VERSION "8.0.0-beta2"

NS_ :

BS_:

BU_:

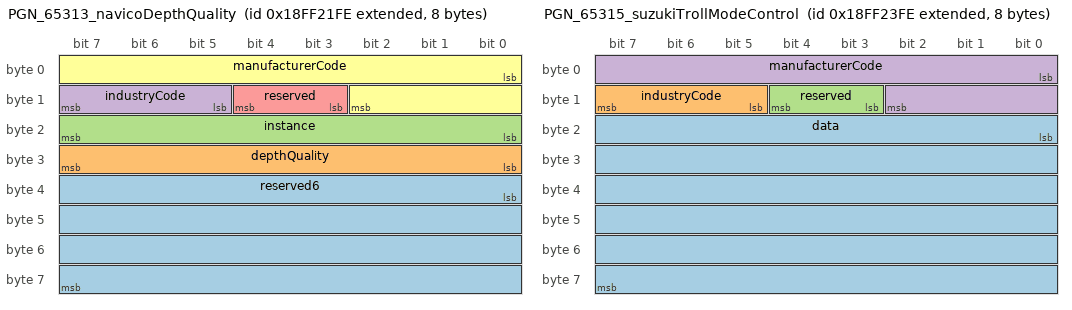
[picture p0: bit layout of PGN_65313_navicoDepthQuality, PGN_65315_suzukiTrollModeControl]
BO_ 2566857214 PGN_65313_navicoDepthQuality: 8 Vector__XXX
 SG_ reserved6 : 32|32@1+ (1,0) [0|0] "" Vector__XXX
 SG_ depthQuality : 24|8@1- (0.01,0) [0|0] "" Vector__XXX
 SG_ instance : 16|8@1+ (1,0) [0|0] "" Vector__XXX
 SG_ industryCode : 13|3@1+ (1,0) [0|0] "" Vector__XXX
 SG_ reserved : 11|2@1+ (1,0) [0|0] "" Vector__XXX
 SG_ manufacturerCode : 0|11@1+ (1,0) [0|0] "" Vector__XXX

BO_ 2566857470 PGN_65314_multiplexed: 8 Vector__XXX
 SG_ m39110_reserved8 m39110 : 48|16@1+ (1,0) [0|0] "" Vector__XXX
 SG_ m39110_reserved7 m39110 : 42|6@1+ (1,0) [0|0] "" Vector__XXX
 SG_ m39110_neutral m39110 : 41|1@1+ (1,0) [0|0] "" Vector__XXX
 SG_ m39110_reserved5 m39110 : 40|1@1+ (1,0) [0|0] "" Vector__XXX
 SG_ m39110_reserved4 m39110 : 16|24@1+ (1,0) [0|0] "" Vector__XXX
 SG_ m39207_data m39207 : 16|48@1+ (1,0) [0|0] "" Vector__XXX
 SG_ manufacturerIndustry M : 0|16@1+ (1,0) [0|0] "" Vector__XXX

BO_ 2566857726 PGN_65315_suzukiTrollModeControl: 8 Vector__XXX
 SG_ data : 16|48@1+ (1,0) [0|0] "" Vector__XXX
 SG_ industryCode : 13|3@1+ (1,0) [0|0] "" Vector__XXX
 SG_ reserved : 11|2@1+ (1,0) [0|0] "" Vector__XXX
 SG_ manufacturerCode : 0|11@1+ (1,0) [0|0] "" Vector__XXX

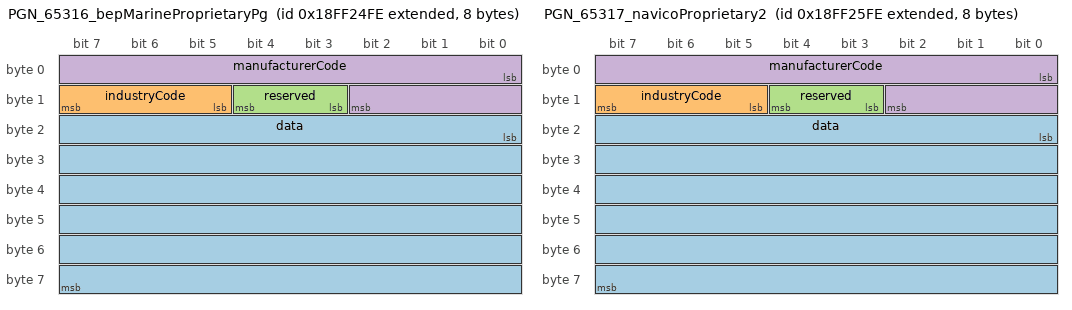
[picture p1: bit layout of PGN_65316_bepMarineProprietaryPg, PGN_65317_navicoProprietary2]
BO_ 2566857982 PGN_65316_bepMarineProprietaryPg: 8 Vector__XXX
 SG_ data : 16|48@1+ (1,0) [0|0] "" Vector__XXX
 SG_ industryCode : 13|3@1+ (1,0) [0|0] "" Vector__XXX
 SG_ reserved : 11|2@1+ (1,0) [0|0] "" Vector__XXX
 SG_ manufacturerCode : 0|11@1+ (1,0) [0|0] "" Vector__XXX

BO_ 2566858238 PGN_65317_navicoProprietary2: 8 Vector__XXX
 SG_ data : 16|48@1+ (1,0) [0|0] "" Vector__XXX
 SG_ industryCode : 13|3@1+ (1,0) [0|0] "" Vector__XXX
 SG_ reserved : 11|2@1+ (1,0) [0|0] "" Vector__XXX
 SG_ manufacturerCode : 0|11@1+ (1,0) [0|0] "" Vector__XXX

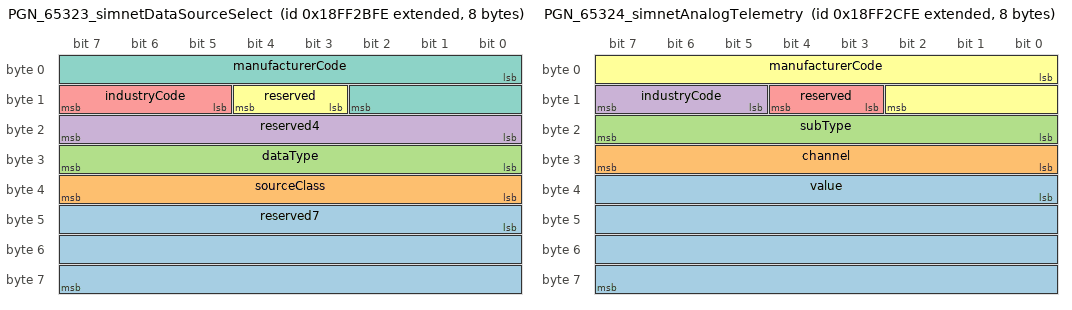
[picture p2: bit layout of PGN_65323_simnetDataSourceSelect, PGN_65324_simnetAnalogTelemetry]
BO_ 2566859774 PGN_65323_simnetDataSourceSelect: 8 Vector__XXX
 SG_ reserved7 : 40|24@1+ (1,0) [0|0] "" Vector__XXX
 SG_ sourceClass : 32|8@1+ (1,0) [0|0] "" Vector__XXX
 SG_ dataType : 24|8@1+ (1,0) [0|0] "" Vector__XXX
 SG_ reserved4 : 16|8@1+ (1,0) [0|0] "" Vector__XXX
 SG_ industryCode : 13|3@1+ (1,0) [0|0] "" Vector__XXX
 SG_ reserved : 11|2@1+ (1,0) [0|0] "" Vector__XXX
 SG_ manufacturerCode : 0|11@1+ (1,0) [0|0] "" Vector__XXX

BO_ 2566860030 PGN_65324_simnetAnalogTelemetry: 8 Vector__XXX
 SG_ value : 32|32@1+ (1,0) [0|0] "" Vector__XXX
 SG_ channel : 24|8@1+ (1,0) [0|0] "" Vector__XXX
 SG_ subType : 16|8@1+ (1,0) [0|0] "" Vector__XXX
 SG_ industryCode : 13|3@1+ (1,0) [0|0] "" Vector__XXX
 SG_ reserved : 11|2@1+ (1,0) [0|0] "" Vector__XXX
 SG_ manufacturerCode : 0|11@1+ (1,0) [0|0] "" Vector__XXX

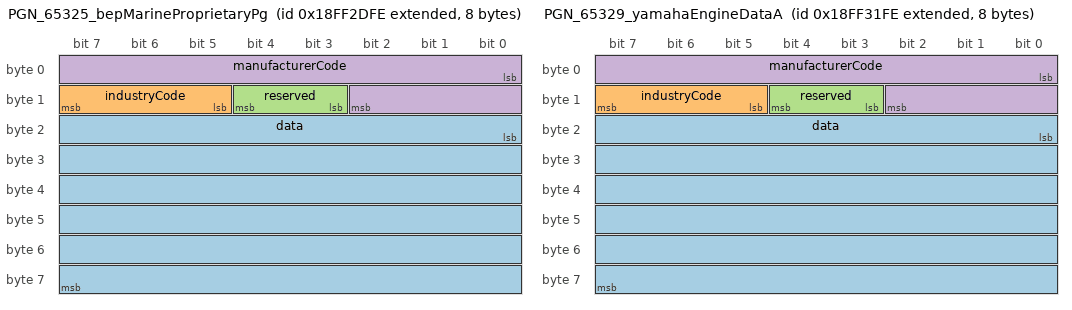
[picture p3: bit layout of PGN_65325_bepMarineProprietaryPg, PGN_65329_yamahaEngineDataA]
BO_ 2566860286 PGN_65325_bepMarineProprietaryPg: 8 Vector__XXX
 SG_ data : 16|48@1+ (1,0) [0|0] "" Vector__XXX
 SG_ industryCode : 13|3@1+ (1,0) [0|0] "" Vector__XXX
 SG_ reserved : 11|2@1+ (1,0) [0|0] "" Vector__XXX
 SG_ manufacturerCode : 0|11@1+ (1,0) [0|0] "" Vector__XXX

BO_ 2566861310 PGN_65329_yamahaEngineDataA: 8 Vector__XXX
 SG_ data : 16|48@1+ (1,0) [0|0] "" Vector__XXX
 SG_ industryCode : 13|3@1+ (1,0) [0|0] "" Vector__XXX
 SG_ reserved : 11|2@1+ (1,0) [0|0] "" Vector__XXX
 SG_ manufacturerCode : 0|11@1+ (1,0) [0|0] "" Vector__XXX

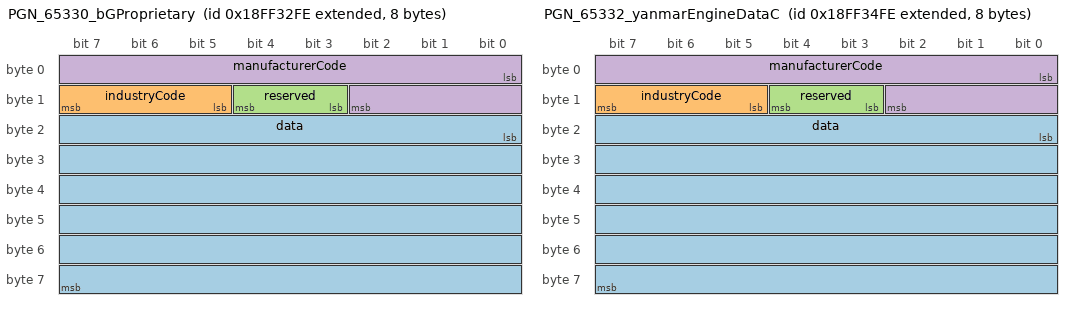
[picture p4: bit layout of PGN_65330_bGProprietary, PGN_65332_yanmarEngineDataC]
BO_ 2566861566 PGN_65330_bGProprietary: 8 Vector__XXX
 SG_ data : 16|48@1+ (1,0) [0|0] "" Vector__XXX
 SG_ industryCode : 13|3@1+ (1,0) [0|0] "" Vector__XXX
 SG_ reserved : 11|2@1+ (1,0) [0|0] "" Vector__XXX
 SG_ manufacturerCode : 0|11@1+ (1,0) [0|0] "" Vector__XXX

BO_ 2566862078 PGN_65332_yanmarEngineDataC: 8 Vector__XXX
 SG_ data : 16|48@1+ (1,0) [0|0] "" Vector__XXX
 SG_ industryCode : 13|3@1+ (1,0) [0|0] "" Vector__XXX
 SG_ reserved : 11|2@1+ (1,0) [0|0] "" Vector__XXX
 SG_ manufacturerCode : 0|11@1+ (1,0) [0|0] "" Vector__XXX

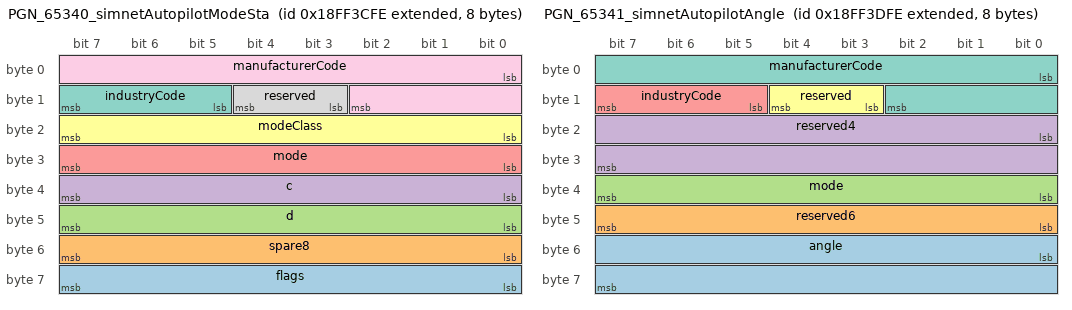
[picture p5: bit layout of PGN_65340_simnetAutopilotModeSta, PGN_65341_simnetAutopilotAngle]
BO_ 2566864126 PGN_65340_simnetAutopilotModeSta: 8 Vector__XXX
 SG_ flags : 56|8@1+ (1,0) [0|0] "" Vector__XXX
 SG_ spare8 : 48|8@1+ (1,0) [0|0] "" Vector__XXX
 SG_ d : 40|8@1+ (1,0) [0|0] "" Vector__XXX
 SG_ c : 32|8@1+ (1,0) [0|0] "" Vector__XXX
 SG_ mode : 24|8@1+ (1,0) [0|0] "" Vector__XXX
 SG_ modeClass : 16|8@1+ (1,0) [0|0] "" Vector__XXX
 SG_ industryCode : 13|3@1+ (1,0) [0|0] "" Vector__XXX
 SG_ reserved : 11|2@1+ (1,0) [0|0] "" Vector__XXX
 SG_ manufacturerCode : 0|11@1+ (1,0) [0|0] "" Vector__XXX

BO_ 2566864382 PGN_65341_simnetAutopilotAngle: 8 Vector__XXX
 SG_ angle : 48|16@1+ (0.0001,0) [0|0] "rad" Vector__XXX
 SG_ reserved6 : 40|8@1+ (1,0) [0|0] "" Vector__XXX
 SG_ mode : 32|8@1+ (1,0) [0|0] "" Vector__XXX
 SG_ reserved4 : 16|16@1+ (1,0) [0|0] "" Vector__XXX
 SG_ industryCode : 13|3@1+ (1,0) [0|0] "" Vector__XXX
 SG_ reserved : 11|2@1+ (1,0) [0|0] "" Vector__XXX
 SG_ manufacturerCode : 0|11@1+ (1,0) [0|0] "" Vector__XXX

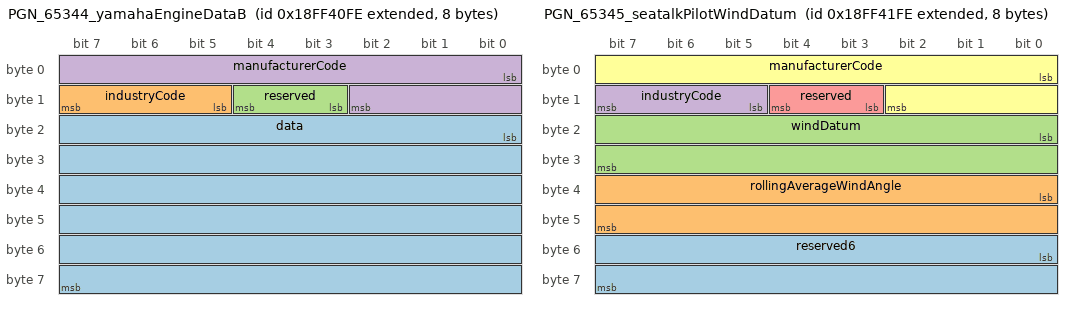
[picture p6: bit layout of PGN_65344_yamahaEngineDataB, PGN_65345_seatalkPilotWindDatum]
BO_ 2566865150 PGN_65344_yamahaEngineDataB: 8 Vector__XXX
 SG_ data : 16|48@1+ (1,0) [0|0] "" Vector__XXX
 SG_ industryCode : 13|3@1+ (1,0) [0|0] "" Vector__XXX
 SG_ reserved : 11|2@1+ (1,0) [0|0] "" Vector__XXX
 SG_ manufacturerCode : 0|11@1+ (1,0) [0|0] "" Vector__XXX

BO_ 2566865406 PGN_65345_seatalkPilotWindDatum: 8 Vector__XXX
 SG_ reserved6 : 48|16@1+ (1,0) [0|0] "" Vector__XXX
 SG_ rollingAverageWindAngle : 32|16@1+ (0.0001,0) [0|0] "rad" Vector__XXX
 SG_ windDatum : 16|16@1+ (0.0001,0) [0|0] "rad" Vector__XXX
 SG_ industryCode : 13|3@1+ (1,0) [0|0] "" Vector__XXX
 SG_ reserved : 11|2@1+ (1,0) [0|0] "" Vector__XXX
 SG_ manufacturerCode : 0|11@1+ (1,0) [0|0] "" Vector__XXX

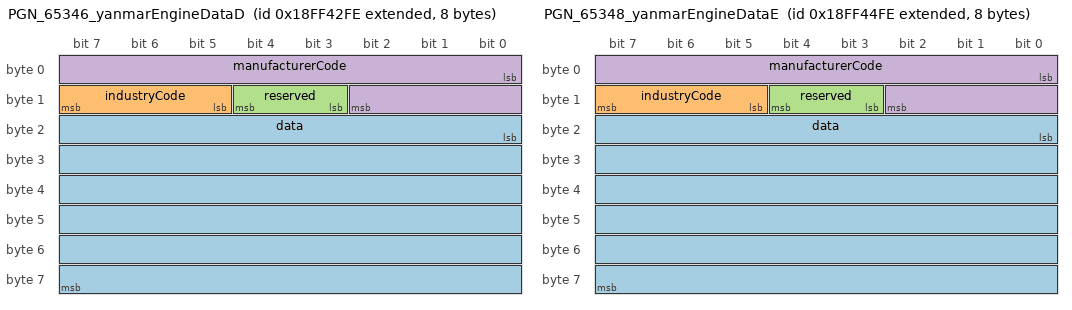
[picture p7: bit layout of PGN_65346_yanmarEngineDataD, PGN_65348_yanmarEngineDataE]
BO_ 2566865662 PGN_65346_yanmarEngineDataD: 8 Vector__XXX
 SG_ data : 16|48@1+ (1,0) [0|0] "" Vector__XXX
 SG_ industryCode : 13|3@1+ (1,0) [0|0] "" Vector__XXX
 SG_ reserved : 11|2@1+ (1,0) [0|0] "" Vector__XXX
 SG_ manufacturerCode : 0|11@1+ (1,0) [0|0] "" Vector__XXX

BO_ 2566866174 PGN_65348_yanmarEngineDataE: 8 Vector__XXX
 SG_ data : 16|48@1+ (1,0) [0|0] "" Vector__XXX
 SG_ industryCode : 13|3@1+ (1,0) [0|0] "" Vector__XXX
 SG_ reserved : 11|2@1+ (1,0) [0|0] "" Vector__XXX
 SG_ manufacturerCode : 0|11@1+ (1,0) [0|0] "" Vector__XXX

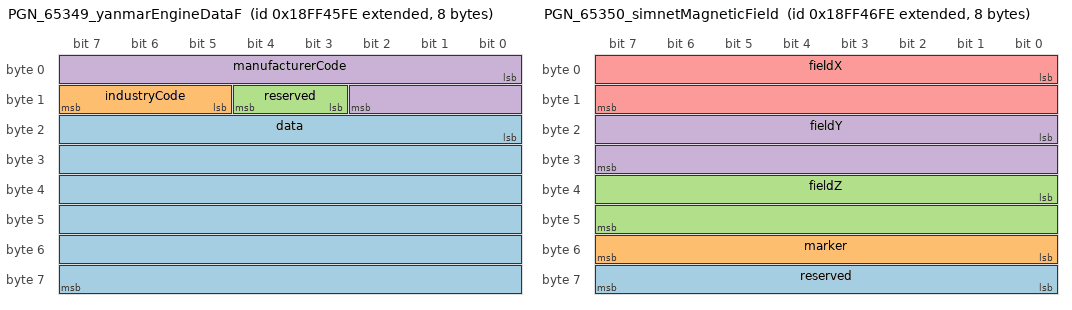
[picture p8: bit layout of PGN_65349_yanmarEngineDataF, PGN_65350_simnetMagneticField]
BO_ 2566866430 PGN_65349_yanmarEngineDataF: 8 Vector__XXX
 SG_ data : 16|48@1+ (1,0) [0|0] "" Vector__XXX
 SG_ industryCode : 13|3@1+ (1,0) [0|0] "" Vector__XXX
 SG_ reserved : 11|2@1+ (1,0) [0|0] "" Vector__XXX
 SG_ manufacturerCode : 0|11@1+ (1,0) [0|0] "" Vector__XXX

BO_ 2566866686 PGN_65350_simnetMagneticField: 8 Vector__XXX
 SG_ reserved : 56|8@1+ (1,0) [0|0] "" Vector__XXX
 SG_ marker : 48|8@1+ (1,0) [0|0] "" Vector__XXX
 SG_ fieldZ : 32|16@1- (0.0001,0) [0|0] "" Vector__XXX
 SG_ fieldY : 16|16@1- (0.0001,0) [0|0] "" Vector__XXX
 SG_ fieldX : 0|16@1- (0.0001,0) [0|0] "" Vector__XXX

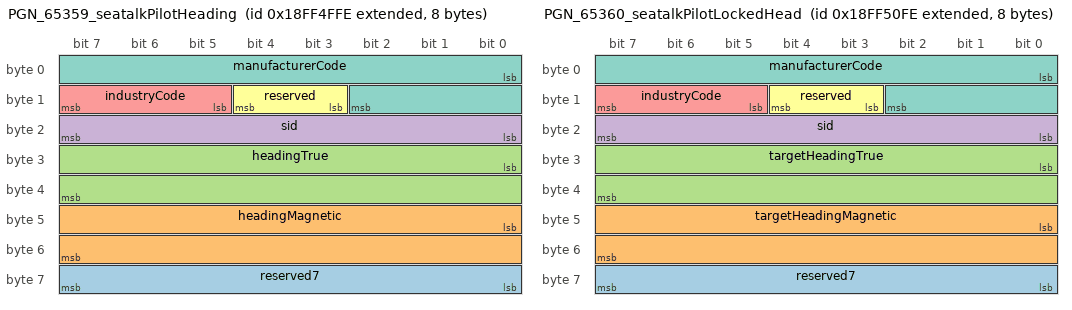
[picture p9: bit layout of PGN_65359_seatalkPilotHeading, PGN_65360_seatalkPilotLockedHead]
BO_ 2566868990 PGN_65359_seatalkPilotHeading: 8 Vector__XXX
 SG_ reserved7 : 56|8@1+ (1,0) [0|0] "" Vector__XXX
 SG_ headingMagnetic : 40|16@1+ (0.0001,0) [0|0] "rad" Vector__XXX
 SG_ headingTrue : 24|16@1+ (0.0001,0) [0|0] "rad" Vector__XXX
 SG_ sid : 16|8@1+ (1,0) [0|0] "" Vector__XXX
 SG_ industryCode : 13|3@1+ (1,0) [0|0] "" Vector__XXX
 SG_ reserved : 11|2@1+ (1,0) [0|0] "" Vector__XXX
 SG_ manufacturerCode : 0|11@1+ (1,0) [0|0] "" Vector__XXX

BO_ 2566869246 PGN_65360_seatalkPilotLockedHead: 8 Vector__XXX
 SG_ reserved7 : 56|8@1+ (1,0) [0|0] "" Vector__XXX
 SG_ targetHeadingMagnetic : 40|16@1+ (0.0001,0) [0|0] "rad" Vector__XXX
 SG_ targetHeadingTrue : 24|16@1+ (0.0001,0) [0|0] "rad" Vector__XXX
 SG_ sid : 16|8@1+ (1,0) [0|0] "" Vector__XXX
 SG_ industryCode : 13|3@1+ (1,0) [0|0] "" Vector__XXX
 SG_ reserved : 11|2@1+ (1,0) [0|0] "" Vector__XXX
 SG_ manufacturerCode : 0|11@1+ (1,0) [0|0] "" Vector__XXX

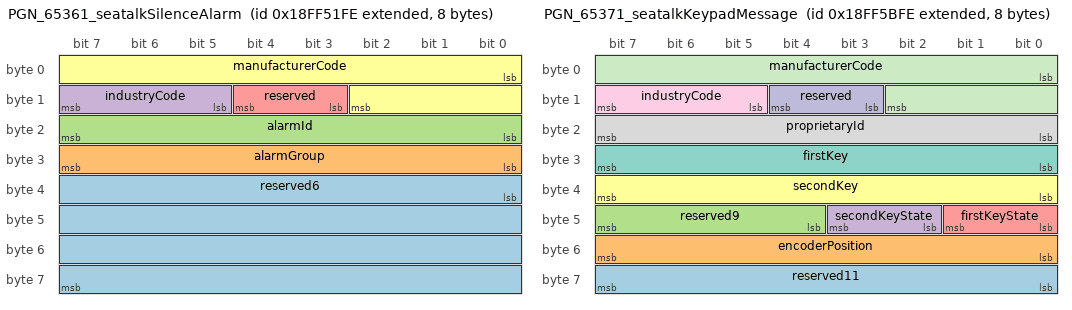
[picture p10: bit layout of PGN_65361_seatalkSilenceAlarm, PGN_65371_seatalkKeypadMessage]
BO_ 2566869502 PGN_65361_seatalkSilenceAlarm: 8 Vector__XXX
 SG_ reserved6 : 32|32@1+ (1,0) [0|0] "" Vector__XXX
 SG_ alarmGroup : 24|8@1+ (1,0) [0|0] "" Vector__XXX
 SG_ alarmId : 16|8@1+ (1,0) [0|0] "" Vector__XXX
 SG_ industryCode : 13|3@1+ (1,0) [0|0] "" Vector__XXX
 SG_ reserved : 11|2@1+ (1,0) [0|0] "" Vector__XXX
 SG_ manufacturerCode : 0|11@1+ (1,0) [0|0] "" Vector__XXX

BO_ 2566872062 PGN_65371_seatalkKeypadMessage: 8 Vector__XXX
 SG_ reserved11 : 56|8@1+ (1,0) [0|0] "" Vector__XXX
 SG_ encoderPosition : 48|8@1+ (1,0) [0|0] "" Vector__XXX
 SG_ reserved9 : 44|4@1+ (1,0) [0|0] "" Vector__XXX
 SG_ secondKeyState : 42|2@1+ (1,0) [0|0] "" Vector__XXX
 SG_ firstKeyState : 40|2@1+ (1,0) [0|0] "" Vector__XXX
 SG_ secondKey : 32|8@1+ (1,0) [0|0] "" Vector__XXX
 SG_ firstKey : 24|8@1+ (1,0) [0|0] "" Vector__XXX
 SG_ proprietaryId : 16|8@1+ (1,0) [0|0] "" Vector__XXX
 SG_ industryCode : 13|3@1+ (1,0) [0|0] "" Vector__XXX
 SG_ reserved : 11|2@1+ (1,0) [0|0] "" Vector__XXX
 SG_ manufacturerCode : 0|11@1+ (1,0) [0|0] "" Vector__XXX

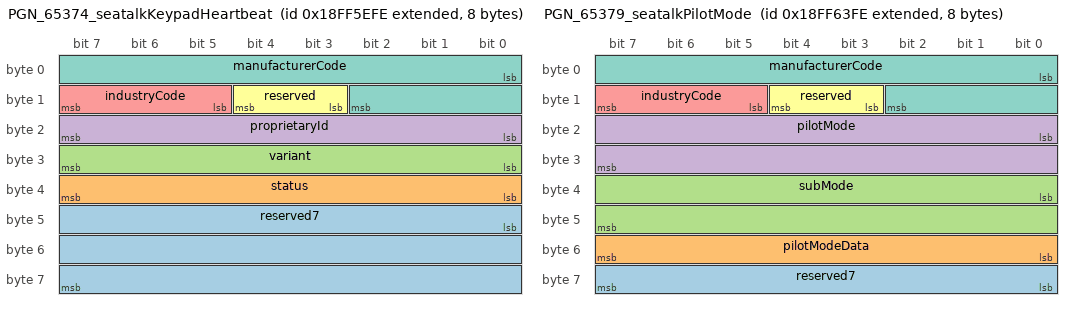
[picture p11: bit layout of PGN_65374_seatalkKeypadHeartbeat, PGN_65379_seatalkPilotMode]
BO_ 2566872830 PGN_65374_seatalkKeypadHeartbeat: 8 Vector__XXX
 SG_ reserved7 : 40|24@1+ (1,0) [0|0] "" Vector__XXX
 SG_ status : 32|8@1+ (1,0) [0|0] "" Vector__XXX
 SG_ variant : 24|8@1+ (1,0) [0|0] "" Vector__XXX
 SG_ proprietaryId : 16|8@1+ (1,0) [0|0] "" Vector__XXX
 SG_ industryCode : 13|3@1+ (1,0) [0|0] "" Vector__XXX
 SG_ reserved : 11|2@1+ (1,0) [0|0] "" Vector__XXX
 SG_ manufacturerCode : 0|11@1+ (1,0) [0|0] "" Vector__XXX

BO_ 2566874110 PGN_65379_seatalkPilotMode: 8 Vector__XXX
 SG_ reserved7 : 56|8@1+ (1,0) [0|0] "" Vector__XXX
 SG_ pilotModeData : 48|8@1+ (1,0) [0|0] "" Vector__XXX
 SG_ subMode : 32|16@1+ (1,0) [0|0] "" Vector__XXX
 SG_ pilotMode : 16|16@1+ (1,0) [0|0] "" Vector__XXX
 SG_ industryCode : 13|3@1+ (1,0) [0|0] "" Vector__XXX
 SG_ reserved : 11|2@1+ (1,0) [0|0] "" Vector__XXX
 SG_ manufacturerCode : 0|11@1+ (1,0) [0|0] "" Vector__XXX

CM_ BO_ 2566857214 "Navico: Depth Quality";
CM_ SG_ 2566857214 depthQuality "Depth signal quality ratio (0 = no bottom lock .. ~1.0 = good)";
CM_ SG_ 2566857214 industryCode "Marine Industry";
CM_ SG_ 2566857214 manufacturerCode "Navico";
CM_ BO_ 2566857470 "Multiplexed message";
CM_ BO_ 2566857726 "Suzuki: Troll Mode Control";
CM_ SG_ 2566857726 industryCode "Marine Industry";
CM_ SG_ 2566857726 manufacturerCode "Suzuki Motor Corporation";
CM_ BO_ 2566857982 "BEP Marine: Proprietary PGN 65316";
CM_ SG_ 2566857982 industryCode "Marine Industry";
CM_ SG_ 2566857982 manufacturerCode "BEP Marine 2";
CM_ BO_ 2566858238 "Navico: Proprietary 2";
CM_ SG_ 2566858238 industryCode "Marine Industry";
CM_ SG_ 2566858238 manufacturerCode "Navico";
CM_ BO_ 2566859774 "Simnet: Data Source Selection Request";
CM_ SG_ 2566859774 sourceClass "Class of source for this Data Type, constant per Data Type: observed as 1 for direct sensor/navigation sources and 100 for autopilot-provided sources";
CM_ SG_ 2566859774 industryCode "Marine Industry";
CM_ SG_ 2566859774 manufacturerCode "Simrad";
CM_ BO_ 2566860030 "Simnet: Analog Telemetry";
CM_ SG_ 2566860030 value "Raw channel reading; 0x7FFF or 0xFFFF means not available";
CM_ SG_ 2566860030 channel "Selects which analog quantity is reported (e.g. drive/heatsink temperature, drive supply voltage, drive current, rudder-feedback angle)";
CM_ SG_ 2566860030 subType "0x40 = telemetry";
CM_ SG_ 2566860030 industryCode "Marine Industry";
CM_ SG_ 2566860030 manufacturerCode "Simrad";
CM_ BO_ 2566860286 "BEP Marine: Proprietary PGN 65325";
CM_ SG_ 2566860286 industryCode "Marine Industry";
CM_ SG_ 2566860286 manufacturerCode "BEP Marine 2";
CM_ BO_ 2566861310 "Yamaha: Engine Data A";
CM_ SG_ 2566861310 industryCode "Marine Industry";
CM_ SG_ 2566861310 manufacturerCode "Mystic Valley Communications";
CM_ BO_ 2566861566 "B&G: Proprietary";
CM_ SG_ 2566861566 industryCode "Marine Industry";
CM_ SG_ 2566861566 manufacturerCode "B & G";
CM_ BO_ 2566862078 "Yanmar: Engine Data C";
CM_ SG_ 2566862078 industryCode "Marine Industry";
CM_ SG_ 2566862078 manufacturerCode "Yanmar Marine";
CM_ BO_ 2566864126 "Simnet: Autopilot Mode State";
CM_ SG_ 2566864126 industryCode "Marine Industry";
CM_ SG_ 2566864126 manufacturerCode "Simrad";
CM_ BO_ 2566864382 "Simnet: Autopilot Angle";
CM_ SG_ 2566864382 industryCode "Marine Industry";
CM_ SG_ 2566864382 manufacturerCode "Simrad";
CM_ BO_ 2566865150 "Yamaha: Engine Data B";
CM_ SG_ 2566865150 industryCode "Marine Industry";
CM_ SG_ 2566865150 manufacturerCode "Mystic Valley Communications";
CM_ BO_ 2566865406 "Seatalk: Pilot Wind Datum";
CM_ SG_ 2566865406 industryCode "Marine Industry";
CM_ SG_ 2566865406 manufacturerCode "Raymarine";
CM_ BO_ 2566865662 "Yanmar: Engine Data D";
CM_ SG_ 2566865662 industryCode "Marine Industry";
CM_ SG_ 2566865662 manufacturerCode "Yanmar Marine";
CM_ BO_ 2566866174 "Yanmar: Engine Data E";
CM_ SG_ 2566866174 industryCode "Marine Industry";
CM_ SG_ 2566866174 manufacturerCode "Yanmar Marine";
CM_ BO_ 2566866430 "Yanmar: Engine Data F";
CM_ SG_ 2566866430 industryCode "Marine Industry";
CM_ SG_ 2566866430 manufacturerCode "Yanmar Marine";
CM_ BO_ 2566866686 "Simnet: Magnetic Field";
CM_ BO_ 2566868990 "Seatalk: Pilot Heading";
CM_ SG_ 2566868990 industryCode "Marine Industry";
CM_ SG_ 2566868990 manufacturerCode "Raymarine";
CM_ BO_ 2566869246 "Seatalk: Pilot Locked Heading";
CM_ SG_ 2566869246 industryCode "Marine Industry";
CM_ SG_ 2566869246 manufacturerCode "Raymarine";
CM_ BO_ 2566869502 "Seatalk: Silence Alarm";
CM_ SG_ 2566869502 industryCode "Marine Industry";
CM_ SG_ 2566869502 manufacturerCode "Raymarine";
CM_ BO_ 2566872062 "Seatalk: Keypad Message";
CM_ SG_ 2566872062 industryCode "Marine Industry";
CM_ SG_ 2566872062 manufacturerCode "Raymarine";
CM_ BO_ 2566872830 "SeaTalk: Keypad Heartbeat";
CM_ SG_ 2566872830 industryCode "Marine Industry";
CM_ SG_ 2566872830 manufacturerCode "Raymarine";
CM_ BO_ 2566874110 "Seatalk: Pilot Mode";
CM_ SG_ 2566874110 industryCode "Marine Industry";
CM_ SG_ 2566874110 manufacturerCode "Raymarine";
BA_DEF_ BO_  "SystemMessageLongSymbol" STRING ;
BA_DEF_ SG_  "SystemSignalLongSymbol" STRING ;
BA_DEF_DEF_  "SystemMessageLongSymbol" "";
BA_DEF_DEF_  "SystemSignalLongSymbol" "";
BA_ "SystemMessageLongSymbol" BO_ 2566857982 "PGN_65316_bepMarineProprietaryPgn65316";
BA_ "SystemMessageLongSymbol" BO_ 2566859774 "PGN_65323_simnetDataSourceSelectionRequest";
BA_ "SystemMessageLongSymbol" BO_ 2566860286 "PGN_65325_bepMarineProprietaryPgn65325";
BA_ "SystemMessageLongSymbol" BO_ 2566864126 "PGN_65340_simnetAutopilotModeState";
BA_ "SystemMessageLongSymbol" BO_ 2566869246 "PGN_65360_seatalkPilotLockedHeading";
VAL_ 2566857214 industryCode 0 "Global" 1 "Highway" 2 "Agriculture" 3 "Construction" 4 "Marine Industry" 5 "Industrial" ;
VAL_ 2566857214 manufacturerCode 69 "ARKS Enterprises, Inc." 78 "FW Murphy/Enovation Controls" 80 "Twin Disc" 85 "Kohler Power Systems" 88 "Hemisphere GPS Inc" 116 "BEP Marine" 135 "Airmar" 137 "Maretron" 140 "Lowrance" 144 "Mercury Marine" 147 "Nautibus Electronic GmbH" 148 "Blue Water Data" 154 "Westerbeke" 157 "ISSPRO Inc" 161 "Offshore Systems (UK) Ltd." 163 "Evinrude/BRP" 165 "CPAC Systems AB" 168 "Xantrex Technology Inc." 169 "Marlin Technologies, Inc." 172 "Yanmar Marine" 174 "Volvo Penta" 175 "Honda Marine" 176 "Carling Technologies Inc. (Moritz Aerospace)" 185 "Beede Instruments" 192 "Floscan Instrument Co. Inc." 193 "Nobletec" 198 "Mystic Valley Communications" 199 "Actia" 200 "Honda Marine 2" 201 "Disenos Y Technologia" 211 "Digital Switching Systems" 215 "Xintex/Atena" 224 "EMMI NETWORK S.L." 225 "Honda Marine 3" 228 "ZF" 229 "Garmin" 233 "Yacht Monitoring Solutions" 235 "Sailormade Marine Telemetry/Tetra Technology LTD" 243 "Eride" 250 "Honda Marine 4" 257 "Honda Motor Company LTD" 272 "Groco" 273 "Actisense" 274 "Amphenol LTW Technology" 275 "Navico" 283 "Hamilton Jet" 285 "Sea Recovery" 286 "Coelmo SRL Italy" 295 "BEP Marine 2" 304 "Empir Bus" 305 "NovAtel" 306 "Sleipner Motor AS" 307 "MBW Technologies" 311 "Fischer Panda" 315 "ICOM" 328 "Qwerty" 329 "Dief" 341 "Boening Automationstechnologie GmbH & Co. KG" 345 "Korean Maritime University" 351 "Thrane and Thrane" 355 "Mastervolt" 356 "Fischer Panda Generators" 358 "Victron Energy" 370 "Rolls Royce Marine" 373 "Electronic Design" 374 "Northern Lights" 378 "Glendinning" 381 "B & G" 384 "Rose Point Navigation Systems" 385 "Johnson Outdoors Marine Electronics Inc Geonav" 394 "Capi 2" 396 "Beyond Measure" 400 "Livorsi Marine" 404 "ComNav" 409 "Chetco" 419 "Fusion Electronics" 421 "Standard Horizon" 422 "True Heading AB" 426 "Egersund Marine Electronics AS" 427 "em-trak Marine Electronics" 431 "Tohatsu Co, JP" 437 "Digital Yacht" 438 "Comar Systems Limited" 440 "Cummins" 443 "VDO (aka Continental-Corporation)" 451 "Parker Hannifin aka Village Marine Tech" 459 "Alltek Marine Electronics Corp" 460 "SAN GIORGIO S.E.I.N" 466 "Veethree Electronics & Marine" 467 "Humminbird Marine Electronics" 470 "SI-TEX Marine Electronics" 471 "Sea Cross Marine AB" 475 "GME aka Standard Communications Pty LTD" 476 "Humminbird Marine Electronics 2" 478 "Ocean Sat BV" 481 "Chetco Digitial Instruments" 493 "Watcheye" 499 "Lcj Capteurs" 502 "Attwood Marine" 503 "Naviop S.R.L." 504 "Vesper Marine Ltd" 510 "Marinesoft Co. LTD" 513 "Simarine" 517 "NoLand Engineering" 518 "Transas USA" 529 "National Instruments Korea" 530 "National Marine Electronics Association" 532 "Onwa Marine" 540 "Webasto" 571 "Marinecraft (South Korea)" 573 "McMurdo Group aka Orolia LTD" 578 "Advansea" 579 "KVH" 580 "San Jose Technology" 583 "Yacht Control" 586 "Suzuki Motor Corporation" 591 "US Coast Guard" 595 "Ship Module aka Customware" 600 "Aquatic AV" 605 "Aventics GmbH" 606 "Intellian" 612 "SamwonIT" 614 "Arlt Tecnologies" 637 "Bavaria Yacts" 641 "Diverse Yacht Services" 644 "Wema U.S.A dba KUS" 645 "Garmin 2" 658 "Shenzhen Jiuzhou Himunication" 688 "Rockford Corp" 699 "Harman International" 704 "JL Audio" 708 "Lars Thrane" 715 "Autonnic" 717 "Yacht Devices" 734 "REAP Systems" 735 "Au Electronics Group" 739 "LxNav" 741 "Littelfuse, Inc (formerly Carling Technologies)" 743 "DaeMyung" 744 "Woosung" 748 "ISOTTA IFRA srl" 772 "Blink Marine" 773 "Clarion US" 776 "HMI Systems" 777 "Ocean Signal" 778 "Seekeeper" 781 "Poly Planar" 785 "Fischer Panda DE" 795 "Broyda Industries" 796 "Canadian Automotive" 797 "Tides Marine" 798 "Lumishore" 799 "Still Water Designs and Audio" 802 "BJ Technologies (Beneteau)" 803 "Gill Sensors" 811 "Blue Water Desalination" 815 "FLIR" 824 "Undheim Systems" 826 "Lewmar Inc" 838 "TeamSurv" 844 "Fell Marine" 847 "Oceanvolt" 862 "Prospec" 868 "Data Panel Corp" 890 "L3 Technologies" 894 "Rhodan Marine Systems" 896 "Nexfour Solutions" 905 "ASA Electronics" 909 "Marines Co (South Korea)" 911 "Nautic-on" 917 "Sentinel" 929 "JL Marine ystems" 930 "Ecotronix" 944 "Zontisa Marine" 951 "EXOR International" 962 "Timbolier Industries" 963 "TJC Micro" 968 "Cox Powertrain" 969 "Blue Seas" 981 "Kobelt Manufacturing Co. Ltd" 992 "Blue Ocean IOT" 997 "Xenta Systems" 999 "Signal K" 1004 "Ultraflex SpA" 1008 "Lintest SmartBoat" 1011 "Soundmax" 1020 "Team Italia Marine (Onyx Marine Automation s.r.l)" 1021 "Entratech" 1022 "ITC Inc." 1029 "The Marine Guardian LLC" 1047 "Sonic Corporation" 1051 "ProNav" 1053 "Vetus Maxwell INC." 1056 "Lithium Pros" 1059 "Boatrax" 1062 "Marol Co ltd" 1065 "CALYPSO Instruments" 1066 "Spot Zero Water" 1069 "Lithionics Battery LLC" 1070 "Quick-teck Electronics Ltd" 1075 "Uniden America" 1083 "Nauticoncept" 1084 "Shadow-Caster LED lighting LLC" 1085 "Wet Sounds, LLC" 1088 "E-T-A Circuit Breakers" 1092 "Scheiber" 1100 "Smart Yachts International Limited" 1109 "Dockmate" 1114 "Bobs Machine" 1118 "L3Harris ASV" 1119 "Balmar LLC" 1120 "Elettromedia spa" 1127 "Electromaax" 1140 "Across Oceans Systems Ltd." 1145 "Kiwi Yachting" 1150 "BSB Artificial Intelligence GmbH" 1151 "Orca Technologoes AS" 1154 "TBS Electronics BV" 1158 "Technoton Electroics" 1160 "MG Energy Systems B.V." 1169 "Sea Macine Robotics Inc." 1171 "Vista Manufacturing" 1183 "Zipwake" 1186 "Sailmon BV" 1192 "Airmoniq Pro Kft" 1194 "Sierra Marine" 1200 "Xinuo Information Technology (Xiamen)" 1218 "Septentrio" 1233 "NKE Marine Elecronics" 1238 "SuperTrack Aps" 1239 "Honda Electronics Co., LTD" 1245 "Raritan Engineering Company, Inc" 1249 "Integrated Power Solutions AG" 1260 "Interactive Technologies, Inc." 1283 "LTG-Tech" 1299 "Energy Solutions (UK) LTD." 1300 "WATT Fuel Cell Corp" 1302 "Pro Mainer" 1305 "Dragonfly Energy" 1306 "Koden Electronics Co., Ltd" 1311 "Humphree AB" 1316 "Hinkley Yachts" 1317 "Global Marine Management GmbH (GMM)" 1320 "Triskel Marine Ltd" 1330 "Warwick Control Technologies" 1331 "Dolphin Charger" 1337 "Barnacle Systems Inc" 1348 "Radian IoT, Inc." 1353 "Ocean LED Marine Ltd" 1359 "BluNav" 1361 "OVA (Nantong Saiyang Electronics Co., Ltd)" 1368 "RAD Propulsion" 1369 "Electric Yacht" 1372 "Elco Motor Yachts" 1384 "Tecnoseal Foundry S.r.l" 1385 "Pro Charging Systems, LLC" 1389 "EVEX Co., LTD" 1398 "Gobius Sensor Technology AB" 1403 "Arco Marine" 1408 "Lenco Marine Inc." 1413 "Naocontrol S.L." 1417 "Revatek" 1438 "Aeolionics" 1439 "PredictWind Ltd" 1440 "Egis Mobile Electric" 1445 "Starboard Yacht Group" 1446 "Roswell Marine" 1451 "ePropulsion (Guangdong ePropulsion Technology Ltd.)" 1452 "Micro-Air LLC" 1453 "Vital Battery" 1458 "Ride Controller LLC" 1460 "Tocaro Blue" 1461 "Vanquish Yachts" 1471 "FT Technologies" 1478 "Alps Alpine Co., Ltd." 1481 "E-Force Marine" 1482 "CMC Marine" 1483 "Nanjing Sandemarine Information Technology Co., Ltd." 1850 "Teleflex Marine (SeaStar Solutions)" 1851 "Raymarine" 1852 "Navionics" 1853 "Japan Radio Co" 1854 "Northstar Technologies" 1855 "Furuno" 1856 "Trimble" 1857 "Simrad" 1858 "Litton" 1859 "Kvasar AB" 1860 "MMP" 1861 "Vector Cantech" 1862 "Yamaha Marine" 1863 "Faria Instruments" ;
VAL_ 2566857470 m39110_neutral 0 "No" 1 "Yes" ;
VAL_ 2566857470 manufacturerIndustry 39207 "BEP Marine 2" 39110 "Mystic Valley Communications" ;
VAL_ 2566857726 industryCode 0 "Global" 1 "Highway" 2 "Agriculture" 3 "Construction" 4 "Marine Industry" 5 "Industrial" ;
VAL_ 2566857726 manufacturerCode 69 "ARKS Enterprises, Inc." 78 "FW Murphy/Enovation Controls" 80 "Twin Disc" 85 "Kohler Power Systems" 88 "Hemisphere GPS Inc" 116 "BEP Marine" 135 "Airmar" 137 "Maretron" 140 "Lowrance" 144 "Mercury Marine" 147 "Nautibus Electronic GmbH" 148 "Blue Water Data" 154 "Westerbeke" 157 "ISSPRO Inc" 161 "Offshore Systems (UK) Ltd." 163 "Evinrude/BRP" 165 "CPAC Systems AB" 168 "Xantrex Technology Inc." 169 "Marlin Technologies, Inc." 172 "Yanmar Marine" 174 "Volvo Penta" 175 "Honda Marine" 176 "Carling Technologies Inc. (Moritz Aerospace)" 185 "Beede Instruments" 192 "Floscan Instrument Co. Inc." 193 "Nobletec" 198 "Mystic Valley Communications" 199 "Actia" 200 "Honda Marine 2" 201 "Disenos Y Technologia" 211 "Digital Switching Systems" 215 "Xintex/Atena" 224 "EMMI NETWORK S.L." 225 "Honda Marine 3" 228 "ZF" 229 "Garmin" 233 "Yacht Monitoring Solutions" 235 "Sailormade Marine Telemetry/Tetra Technology LTD" 243 "Eride" 250 "Honda Marine 4" 257 "Honda Motor Company LTD" 272 "Groco" 273 "Actisense" 274 "Amphenol LTW Technology" 275 "Navico" 283 "Hamilton Jet" 285 "Sea Recovery" 286 "Coelmo SRL Italy" 295 "BEP Marine 2" 304 "Empir Bus" 305 "NovAtel" 306 "Sleipner Motor AS" 307 "MBW Technologies" 311 "Fischer Panda" 315 "ICOM" 328 "Qwerty" 329 "Dief" 341 "Boening Automationstechnologie GmbH & Co. KG" 345 "Korean Maritime University" 351 "Thrane and Thrane" 355 "Mastervolt" 356 "Fischer Panda Generators" 358 "Victron Energy" 370 "Rolls Royce Marine" 373 "Electronic Design" 374 "Northern Lights" 378 "Glendinning" 381 "B & G" 384 "Rose Point Navigation Systems" 385 "Johnson Outdoors Marine Electronics Inc Geonav" 394 "Capi 2" 396 "Beyond Measure" 400 "Livorsi Marine" 404 "ComNav" 409 "Chetco" 419 "Fusion Electronics" 421 "Standard Horizon" 422 "True Heading AB" 426 "Egersund Marine Electronics AS" 427 "em-trak Marine Electronics" 431 "Tohatsu Co, JP" 437 "Digital Yacht" 438 "Comar Systems Limited" 440 "Cummins" 443 "VDO (aka Continental-Corporation)" 451 "Parker Hannifin aka Village Marine Tech" 459 "Alltek Marine Electronics Corp" 460 "SAN GIORGIO S.E.I.N" 466 "Veethree Electronics & Marine" 467 "Humminbird Marine Electronics" 470 "SI-TEX Marine Electronics" 471 "Sea Cross Marine AB" 475 "GME aka Standard Communications Pty LTD" 476 "Humminbird Marine Electronics 2" 478 "Ocean Sat BV" 481 "Chetco Digitial Instruments" 493 "Watcheye" 499 "Lcj Capteurs" 502 "Attwood Marine" 503 "Naviop S.R.L." 504 "Vesper Marine Ltd" 510 "Marinesoft Co. LTD" 513 "Simarine" 517 "NoLand Engineering" 518 "Transas USA" 529 "National Instruments Korea" 530 "National Marine Electronics Association" 532 "Onwa Marine" 540 "Webasto" 571 "Marinecraft (South Korea)" 573 "McMurdo Group aka Orolia LTD" 578 "Advansea" 579 "KVH" 580 "San Jose Technology" 583 "Yacht Control" 586 "Suzuki Motor Corporation" 591 "US Coast Guard" 595 "Ship Module aka Customware" 600 "Aquatic AV" 605 "Aventics GmbH" 606 "Intellian" 612 "SamwonIT" 614 "Arlt Tecnologies" 637 "Bavaria Yacts" 641 "Diverse Yacht Services" 644 "Wema U.S.A dba KUS" 645 "Garmin 2" 658 "Shenzhen Jiuzhou Himunication" 688 "Rockford Corp" 699 "Harman International" 704 "JL Audio" 708 "Lars Thrane" 715 "Autonnic" 717 "Yacht Devices" 734 "REAP Systems" 735 "Au Electronics Group" 739 "LxNav" 741 "Littelfuse, Inc (formerly Carling Technologies)" 743 "DaeMyung" 744 "Woosung" 748 "ISOTTA IFRA srl" 772 "Blink Marine" 773 "Clarion US" 776 "HMI Systems" 777 "Ocean Signal" 778 "Seekeeper" 781 "Poly Planar" 785 "Fischer Panda DE" 795 "Broyda Industries" 796 "Canadian Automotive" 797 "Tides Marine" 798 "Lumishore" 799 "Still Water Designs and Audio" 802 "BJ Technologies (Beneteau)" 803 "Gill Sensors" 811 "Blue Water Desalination" 815 "FLIR" 824 "Undheim Systems" 826 "Lewmar Inc" 838 "TeamSurv" 844 "Fell Marine" 847 "Oceanvolt" 862 "Prospec" 868 "Data Panel Corp" 890 "L3 Technologies" 894 "Rhodan Marine Systems" 896 "Nexfour Solutions" 905 "ASA Electronics" 909 "Marines Co (South Korea)" 911 "Nautic-on" 917 "Sentinel" 929 "JL Marine ystems" 930 "Ecotronix" 944 "Zontisa Marine" 951 "EXOR International" 962 "Timbolier Industries" 963 "TJC Micro" 968 "Cox Powertrain" 969 "Blue Seas" 981 "Kobelt Manufacturing Co. Ltd" 992 "Blue Ocean IOT" 997 "Xenta Systems" 999 "Signal K" 1004 "Ultraflex SpA" 1008 "Lintest SmartBoat" 1011 "Soundmax" 1020 "Team Italia Marine (Onyx Marine Automation s.r.l)" 1021 "Entratech" 1022 "ITC Inc." 1029 "The Marine Guardian LLC" 1047 "Sonic Corporation" 1051 "ProNav" 1053 "Vetus Maxwell INC." 1056 "Lithium Pros" 1059 "Boatrax" 1062 "Marol Co ltd" 1065 "CALYPSO Instruments" 1066 "Spot Zero Water" 1069 "Lithionics Battery LLC" 1070 "Quick-teck Electronics Ltd" 1075 "Uniden America" 1083 "Nauticoncept" 1084 "Shadow-Caster LED lighting LLC" 1085 "Wet Sounds, LLC" 1088 "E-T-A Circuit Breakers" 1092 "Scheiber" 1100 "Smart Yachts International Limited" 1109 "Dockmate" 1114 "Bobs Machine" 1118 "L3Harris ASV" 1119 "Balmar LLC" 1120 "Elettromedia spa" 1127 "Electromaax" 1140 "Across Oceans Systems Ltd." 1145 "Kiwi Yachting" 1150 "BSB Artificial Intelligence GmbH" 1151 "Orca Technologoes AS" 1154 "TBS Electronics BV" 1158 "Technoton Electroics" 1160 "MG Energy Systems B.V." 1169 "Sea Macine Robotics Inc." 1171 "Vista Manufacturing" 1183 "Zipwake" 1186 "Sailmon BV" 1192 "Airmoniq Pro Kft" 1194 "Sierra Marine" 1200 "Xinuo Information Technology (Xiamen)" 1218 "Septentrio" 1233 "NKE Marine Elecronics" 1238 "SuperTrack Aps" 1239 "Honda Electronics Co., LTD" 1245 "Raritan Engineering Company, Inc" 1249 "Integrated Power Solutions AG" 1260 "Interactive Technologies, Inc." 1283 "LTG-Tech" 1299 "Energy Solutions (UK) LTD." 1300 "WATT Fuel Cell Corp" 1302 "Pro Mainer" 1305 "Dragonfly Energy" 1306 "Koden Electronics Co., Ltd" 1311 "Humphree AB" 1316 "Hinkley Yachts" 1317 "Global Marine Management GmbH (GMM)" 1320 "Triskel Marine Ltd" 1330 "Warwick Control Technologies" 1331 "Dolphin Charger" 1337 "Barnacle Systems Inc" 1348 "Radian IoT, Inc." 1353 "Ocean LED Marine Ltd" 1359 "BluNav" 1361 "OVA (Nantong Saiyang Electronics Co., Ltd)" 1368 "RAD Propulsion" 1369 "Electric Yacht" 1372 "Elco Motor Yachts" 1384 "Tecnoseal Foundry S.r.l" 1385 "Pro Charging Systems, LLC" 1389 "EVEX Co., LTD" 1398 "Gobius Sensor Technology AB" 1403 "Arco Marine" 1408 "Lenco Marine Inc." 1413 "Naocontrol S.L." 1417 "Revatek" 1438 "Aeolionics" 1439 "PredictWind Ltd" 1440 "Egis Mobile Electric" 1445 "Starboard Yacht Group" 1446 "Roswell Marine" 1451 "ePropulsion (Guangdong ePropulsion Technology Ltd.)" 1452 "Micro-Air LLC" 1453 "Vital Battery" 1458 "Ride Controller LLC" 1460 "Tocaro Blue" 1461 "Vanquish Yachts" 1471 "FT Technologies" 1478 "Alps Alpine Co., Ltd." 1481 "E-Force Marine" 1482 "CMC Marine" 1483 "Nanjing Sandemarine Information Technology Co., Ltd." 1850 "Teleflex Marine (SeaStar Solutions)" 1851 "Raymarine" 1852 "Navionics" 1853 "Japan Radio Co" 1854 "Northstar Technologies" 1855 "Furuno" 1856 "Trimble" 1857 "Simrad" 1858 "Litton" 1859 "Kvasar AB" 1860 "MMP" 1861 "Vector Cantech" 1862 "Yamaha Marine" 1863 "Faria Instruments" ;
VAL_ 2566857982 industryCode 0 "Global" 1 "Highway" 2 "Agriculture" 3 "Construction" 4 "Marine Industry" 5 "Industrial" ;
VAL_ 2566857982 manufacturerCode 69 "ARKS Enterprises, Inc." 78 "FW Murphy/Enovation Controls" 80 "Twin Disc" 85 "Kohler Power Systems" 88 "Hemisphere GPS Inc" 116 "BEP Marine" 135 "Airmar" 137 "Maretron" 140 "Lowrance" 144 "Mercury Marine" 147 "Nautibus Electronic GmbH" 148 "Blue Water Data" 154 "Westerbeke" 157 "ISSPRO Inc" 161 "Offshore Systems (UK) Ltd." 163 "Evinrude/BRP" 165 "CPAC Systems AB" 168 "Xantrex Technology Inc." 169 "Marlin Technologies, Inc." 172 "Yanmar Marine" 174 "Volvo Penta" 175 "Honda Marine" 176 "Carling Technologies Inc. (Moritz Aerospace)" 185 "Beede Instruments" 192 "Floscan Instrument Co. Inc." 193 "Nobletec" 198 "Mystic Valley Communications" 199 "Actia" 200 "Honda Marine 2" 201 "Disenos Y Technologia" 211 "Digital Switching Systems" 215 "Xintex/Atena" 224 "EMMI NETWORK S.L." 225 "Honda Marine 3" 228 "ZF" 229 "Garmin" 233 "Yacht Monitoring Solutions" 235 "Sailormade Marine Telemetry/Tetra Technology LTD" 243 "Eride" 250 "Honda Marine 4" 257 "Honda Motor Company LTD" 272 "Groco" 273 "Actisense" 274 "Amphenol LTW Technology" 275 "Navico" 283 "Hamilton Jet" 285 "Sea Recovery" 286 "Coelmo SRL Italy" 295 "BEP Marine 2" 304 "Empir Bus" 305 "NovAtel" 306 "Sleipner Motor AS" 307 "MBW Technologies" 311 "Fischer Panda" 315 "ICOM" 328 "Qwerty" 329 "Dief" 341 "Boening Automationstechnologie GmbH & Co. KG" 345 "Korean Maritime University" 351 "Thrane and Thrane" 355 "Mastervolt" 356 "Fischer Panda Generators" 358 "Victron Energy" 370 "Rolls Royce Marine" 373 "Electronic Design" 374 "Northern Lights" 378 "Glendinning" 381 "B & G" 384 "Rose Point Navigation Systems" 385 "Johnson Outdoors Marine Electronics Inc Geonav" 394 "Capi 2" 396 "Beyond Measure" 400 "Livorsi Marine" 404 "ComNav" 409 "Chetco" 419 "Fusion Electronics" 421 "Standard Horizon" 422 "True Heading AB" 426 "Egersund Marine Electronics AS" 427 "em-trak Marine Electronics" 431 "Tohatsu Co, JP" 437 "Digital Yacht" 438 "Comar Systems Limited" 440 "Cummins" 443 "VDO (aka Continental-Corporation)" 451 "Parker Hannifin aka Village Marine Tech" 459 "Alltek Marine Electronics Corp" 460 "SAN GIORGIO S.E.I.N" 466 "Veethree Electronics & Marine" 467 "Humminbird Marine Electronics" 470 "SI-TEX Marine Electronics" 471 "Sea Cross Marine AB" 475 "GME aka Standard Communications Pty LTD" 476 "Humminbird Marine Electronics 2" 478 "Ocean Sat BV" 481 "Chetco Digitial Instruments" 493 "Watcheye" 499 "Lcj Capteurs" 502 "Attwood Marine" 503 "Naviop S.R.L." 504 "Vesper Marine Ltd" 510 "Marinesoft Co. LTD" 513 "Simarine" 517 "NoLand Engineering" 518 "Transas USA" 529 "National Instruments Korea" 530 "National Marine Electronics Association" 532 "Onwa Marine" 540 "Webasto" 571 "Marinecraft (South Korea)" 573 "McMurdo Group aka Orolia LTD" 578 "Advansea" 579 "KVH" 580 "San Jose Technology" 583 "Yacht Control" 586 "Suzuki Motor Corporation" 591 "US Coast Guard" 595 "Ship Module aka Customware" 600 "Aquatic AV" 605 "Aventics GmbH" 606 "Intellian" 612 "SamwonIT" 614 "Arlt Tecnologies" 637 "Bavaria Yacts" 641 "Diverse Yacht Services" 644 "Wema U.S.A dba KUS" 645 "Garmin 2" 658 "Shenzhen Jiuzhou Himunication" 688 "Rockford Corp" 699 "Harman International" 704 "JL Audio" 708 "Lars Thrane" 715 "Autonnic" 717 "Yacht Devices" 734 "REAP Systems" 735 "Au Electronics Group" 739 "LxNav" 741 "Littelfuse, Inc (formerly Carling Technologies)" 743 "DaeMyung" 744 "Woosung" 748 "ISOTTA IFRA srl" 772 "Blink Marine" 773 "Clarion US" 776 "HMI Systems" 777 "Ocean Signal" 778 "Seekeeper" 781 "Poly Planar" 785 "Fischer Panda DE" 795 "Broyda Industries" 796 "Canadian Automotive" 797 "Tides Marine" 798 "Lumishore" 799 "Still Water Designs and Audio" 802 "BJ Technologies (Beneteau)" 803 "Gill Sensors" 811 "Blue Water Desalination" 815 "FLIR" 824 "Undheim Systems" 826 "Lewmar Inc" 838 "TeamSurv" 844 "Fell Marine" 847 "Oceanvolt" 862 "Prospec" 868 "Data Panel Corp" 890 "L3 Technologies" 894 "Rhodan Marine Systems" 896 "Nexfour Solutions" 905 "ASA Electronics" 909 "Marines Co (South Korea)" 911 "Nautic-on" 917 "Sentinel" 929 "JL Marine ystems" 930 "Ecotronix" 944 "Zontisa Marine" 951 "EXOR International" 962 "Timbolier Industries" 963 "TJC Micro" 968 "Cox Powertrain" 969 "Blue Seas" 981 "Kobelt Manufacturing Co. Ltd" 992 "Blue Ocean IOT" 997 "Xenta Systems" 999 "Signal K" 1004 "Ultraflex SpA" 1008 "Lintest SmartBoat" 1011 "Soundmax" 1020 "Team Italia Marine (Onyx Marine Automation s.r.l)" 1021 "Entratech" 1022 "ITC Inc." 1029 "The Marine Guardian LLC" 1047 "Sonic Corporation" 1051 "ProNav" 1053 "Vetus Maxwell INC." 1056 "Lithium Pros" 1059 "Boatrax" 1062 "Marol Co ltd" 1065 "CALYPSO Instruments" 1066 "Spot Zero Water" 1069 "Lithionics Battery LLC" 1070 "Quick-teck Electronics Ltd" 1075 "Uniden America" 1083 "Nauticoncept" 1084 "Shadow-Caster LED lighting LLC" 1085 "Wet Sounds, LLC" 1088 "E-T-A Circuit Breakers" 1092 "Scheiber" 1100 "Smart Yachts International Limited" 1109 "Dockmate" 1114 "Bobs Machine" 1118 "L3Harris ASV" 1119 "Balmar LLC" 1120 "Elettromedia spa" 1127 "Electromaax" 1140 "Across Oceans Systems Ltd." 1145 "Kiwi Yachting" 1150 "BSB Artificial Intelligence GmbH" 1151 "Orca Technologoes AS" 1154 "TBS Electronics BV" 1158 "Technoton Electroics" 1160 "MG Energy Systems B.V." 1169 "Sea Macine Robotics Inc." 1171 "Vista Manufacturing" 1183 "Zipwake" 1186 "Sailmon BV" 1192 "Airmoniq Pro Kft" 1194 "Sierra Marine" 1200 "Xinuo Information Technology (Xiamen)" 1218 "Septentrio" 1233 "NKE Marine Elecronics" 1238 "SuperTrack Aps" 1239 "Honda Electronics Co., LTD" 1245 "Raritan Engineering Company, Inc" 1249 "Integrated Power Solutions AG" 1260 "Interactive Technologies, Inc." 1283 "LTG-Tech" 1299 "Energy Solutions (UK) LTD." 1300 "WATT Fuel Cell Corp" 1302 "Pro Mainer" 1305 "Dragonfly Energy" 1306 "Koden Electronics Co., Ltd" 1311 "Humphree AB" 1316 "Hinkley Yachts" 1317 "Global Marine Management GmbH (GMM)" 1320 "Triskel Marine Ltd" 1330 "Warwick Control Technologies" 1331 "Dolphin Charger" 1337 "Barnacle Systems Inc" 1348 "Radian IoT, Inc." 1353 "Ocean LED Marine Ltd" 1359 "BluNav" 1361 "OVA (Nantong Saiyang Electronics Co., Ltd)" 1368 "RAD Propulsion" 1369 "Electric Yacht" 1372 "Elco Motor Yachts" 1384 "Tecnoseal Foundry S.r.l" 1385 "Pro Charging Systems, LLC" 1389 "EVEX Co., LTD" 1398 "Gobius Sensor Technology AB" 1403 "Arco Marine" 1408 "Lenco Marine Inc." 1413 "Naocontrol S.L." 1417 "Revatek" 1438 "Aeolionics" 1439 "PredictWind Ltd" 1440 "Egis Mobile Electric" 1445 "Starboard Yacht Group" 1446 "Roswell Marine" 1451 "ePropulsion (Guangdong ePropulsion Technology Ltd.)" 1452 "Micro-Air LLC" 1453 "Vital Battery" 1458 "Ride Controller LLC" 1460 "Tocaro Blue" 1461 "Vanquish Yachts" 1471 "FT Technologies" 1478 "Alps Alpine Co., Ltd." 1481 "E-Force Marine" 1482 "CMC Marine" 1483 "Nanjing Sandemarine Information Technology Co., Ltd." 1850 "Teleflex Marine (SeaStar Solutions)" 1851 "Raymarine" 1852 "Navionics" 1853 "Japan Radio Co" 1854 "Northstar Technologies" 1855 "Furuno" 1856 "Trimble" 1857 "Simrad" 1858 "Litton" 1859 "Kvasar AB" 1860 "MMP" 1861 "Vector Cantech" 1862 "Yamaha Marine" 1863 "Faria Instruments" ;
VAL_ 2566858238 industryCode 0 "Global" 1 "Highway" 2 "Agriculture" 3 "Construction" 4 "Marine Industry" 5 "Industrial" ;
VAL_ 2566858238 manufacturerCode 69 "ARKS Enterprises, Inc." 78 "FW Murphy/Enovation Controls" 80 "Twin Disc" 85 "Kohler Power Systems" 88 "Hemisphere GPS Inc" 116 "BEP Marine" 135 "Airmar" 137 "Maretron" 140 "Lowrance" 144 "Mercury Marine" 147 "Nautibus Electronic GmbH" 148 "Blue Water Data" 154 "Westerbeke" 157 "ISSPRO Inc" 161 "Offshore Systems (UK) Ltd." 163 "Evinrude/BRP" 165 "CPAC Systems AB" 168 "Xantrex Technology Inc." 169 "Marlin Technologies, Inc." 172 "Yanmar Marine" 174 "Volvo Penta" 175 "Honda Marine" 176 "Carling Technologies Inc. (Moritz Aerospace)" 185 "Beede Instruments" 192 "Floscan Instrument Co. Inc." 193 "Nobletec" 198 "Mystic Valley Communications" 199 "Actia" 200 "Honda Marine 2" 201 "Disenos Y Technologia" 211 "Digital Switching Systems" 215 "Xintex/Atena" 224 "EMMI NETWORK S.L." 225 "Honda Marine 3" 228 "ZF" 229 "Garmin" 233 "Yacht Monitoring Solutions" 235 "Sailormade Marine Telemetry/Tetra Technology LTD" 243 "Eride" 250 "Honda Marine 4" 257 "Honda Motor Company LTD" 272 "Groco" 273 "Actisense" 274 "Amphenol LTW Technology" 275 "Navico" 283 "Hamilton Jet" 285 "Sea Recovery" 286 "Coelmo SRL Italy" 295 "BEP Marine 2" 304 "Empir Bus" 305 "NovAtel" 306 "Sleipner Motor AS" 307 "MBW Technologies" 311 "Fischer Panda" 315 "ICOM" 328 "Qwerty" 329 "Dief" 341 "Boening Automationstechnologie GmbH & Co. KG" 345 "Korean Maritime University" 351 "Thrane and Thrane" 355 "Mastervolt" 356 "Fischer Panda Generators" 358 "Victron Energy" 370 "Rolls Royce Marine" 373 "Electronic Design" 374 "Northern Lights" 378 "Glendinning" 381 "B & G" 384 "Rose Point Navigation Systems" 385 "Johnson Outdoors Marine Electronics Inc Geonav" 394 "Capi 2" 396 "Beyond Measure" 400 "Livorsi Marine" 404 "ComNav" 409 "Chetco" 419 "Fusion Electronics" 421 "Standard Horizon" 422 "True Heading AB" 426 "Egersund Marine Electronics AS" 427 "em-trak Marine Electronics" 431 "Tohatsu Co, JP" 437 "Digital Yacht" 438 "Comar Systems Limited" 440 "Cummins" 443 "VDO (aka Continental-Corporation)" 451 "Parker Hannifin aka Village Marine Tech" 459 "Alltek Marine Electronics Corp" 460 "SAN GIORGIO S.E.I.N" 466 "Veethree Electronics & Marine" 467 "Humminbird Marine Electronics" 470 "SI-TEX Marine Electronics" 471 "Sea Cross Marine AB" 475 "GME aka Standard Communications Pty LTD" 476 "Humminbird Marine Electronics 2" 478 "Ocean Sat BV" 481 "Chetco Digitial Instruments" 493 "Watcheye" 499 "Lcj Capteurs" 502 "Attwood Marine" 503 "Naviop S.R.L." 504 "Vesper Marine Ltd" 510 "Marinesoft Co. LTD" 513 "Simarine" 517 "NoLand Engineering" 518 "Transas USA" 529 "National Instruments Korea" 530 "National Marine Electronics Association" 532 "Onwa Marine" 540 "Webasto" 571 "Marinecraft (South Korea)" 573 "McMurdo Group aka Orolia LTD" 578 "Advansea" 579 "KVH" 580 "San Jose Technology" 583 "Yacht Control" 586 "Suzuki Motor Corporation" 591 "US Coast Guard" 595 "Ship Module aka Customware" 600 "Aquatic AV" 605 "Aventics GmbH" 606 "Intellian" 612 "SamwonIT" 614 "Arlt Tecnologies" 637 "Bavaria Yacts" 641 "Diverse Yacht Services" 644 "Wema U.S.A dba KUS" 645 "Garmin 2" 658 "Shenzhen Jiuzhou Himunication" 688 "Rockford Corp" 699 "Harman International" 704 "JL Audio" 708 "Lars Thrane" 715 "Autonnic" 717 "Yacht Devices" 734 "REAP Systems" 735 "Au Electronics Group" 739 "LxNav" 741 "Littelfuse, Inc (formerly Carling Technologies)" 743 "DaeMyung" 744 "Woosung" 748 "ISOTTA IFRA srl" 772 "Blink Marine" 773 "Clarion US" 776 "HMI Systems" 777 "Ocean Signal" 778 "Seekeeper" 781 "Poly Planar" 785 "Fischer Panda DE" 795 "Broyda Industries" 796 "Canadian Automotive" 797 "Tides Marine" 798 "Lumishore" 799 "Still Water Designs and Audio" 802 "BJ Technologies (Beneteau)" 803 "Gill Sensors" 811 "Blue Water Desalination" 815 "FLIR" 824 "Undheim Systems" 826 "Lewmar Inc" 838 "TeamSurv" 844 "Fell Marine" 847 "Oceanvolt" 862 "Prospec" 868 "Data Panel Corp" 890 "L3 Technologies" 894 "Rhodan Marine Systems" 896 "Nexfour Solutions" 905 "ASA Electronics" 909 "Marines Co (South Korea)" 911 "Nautic-on" 917 "Sentinel" 929 "JL Marine ystems" 930 "Ecotronix" 944 "Zontisa Marine" 951 "EXOR International" 962 "Timbolier Industries" 963 "TJC Micro" 968 "Cox Powertrain" 969 "Blue Seas" 981 "Kobelt Manufacturing Co. Ltd" 992 "Blue Ocean IOT" 997 "Xenta Systems" 999 "Signal K" 1004 "Ultraflex SpA" 1008 "Lintest SmartBoat" 1011 "Soundmax" 1020 "Team Italia Marine (Onyx Marine Automation s.r.l)" 1021 "Entratech" 1022 "ITC Inc." 1029 "The Marine Guardian LLC" 1047 "Sonic Corporation" 1051 "ProNav" 1053 "Vetus Maxwell INC." 1056 "Lithium Pros" 1059 "Boatrax" 1062 "Marol Co ltd" 1065 "CALYPSO Instruments" 1066 "Spot Zero Water" 1069 "Lithionics Battery LLC" 1070 "Quick-teck Electronics Ltd" 1075 "Uniden America" 1083 "Nauticoncept" 1084 "Shadow-Caster LED lighting LLC" 1085 "Wet Sounds, LLC" 1088 "E-T-A Circuit Breakers" 1092 "Scheiber" 1100 "Smart Yachts International Limited" 1109 "Dockmate" 1114 "Bobs Machine" 1118 "L3Harris ASV" 1119 "Balmar LLC" 1120 "Elettromedia spa" 1127 "Electromaax" 1140 "Across Oceans Systems Ltd." 1145 "Kiwi Yachting" 1150 "BSB Artificial Intelligence GmbH" 1151 "Orca Technologoes AS" 1154 "TBS Electronics BV" 1158 "Technoton Electroics" 1160 "MG Energy Systems B.V." 1169 "Sea Macine Robotics Inc." 1171 "Vista Manufacturing" 1183 "Zipwake" 1186 "Sailmon BV" 1192 "Airmoniq Pro Kft" 1194 "Sierra Marine" 1200 "Xinuo Information Technology (Xiamen)" 1218 "Septentrio" 1233 "NKE Marine Elecronics" 1238 "SuperTrack Aps" 1239 "Honda Electronics Co., LTD" 1245 "Raritan Engineering Company, Inc" 1249 "Integrated Power Solutions AG" 1260 "Interactive Technologies, Inc." 1283 "LTG-Tech" 1299 "Energy Solutions (UK) LTD." 1300 "WATT Fuel Cell Corp" 1302 "Pro Mainer" 1305 "Dragonfly Energy" 1306 "Koden Electronics Co., Ltd" 1311 "Humphree AB" 1316 "Hinkley Yachts" 1317 "Global Marine Management GmbH (GMM)" 1320 "Triskel Marine Ltd" 1330 "Warwick Control Technologies" 1331 "Dolphin Charger" 1337 "Barnacle Systems Inc" 1348 "Radian IoT, Inc." 1353 "Ocean LED Marine Ltd" 1359 "BluNav" 1361 "OVA (Nantong Saiyang Electronics Co., Ltd)" 1368 "RAD Propulsion" 1369 "Electric Yacht" 1372 "Elco Motor Yachts" 1384 "Tecnoseal Foundry S.r.l" 1385 "Pro Charging Systems, LLC" 1389 "EVEX Co., LTD" 1398 "Gobius Sensor Technology AB" 1403 "Arco Marine" 1408 "Lenco Marine Inc." 1413 "Naocontrol S.L." 1417 "Revatek" 1438 "Aeolionics" 1439 "PredictWind Ltd" 1440 "Egis Mobile Electric" 1445 "Starboard Yacht Group" 1446 "Roswell Marine" 1451 "ePropulsion (Guangdong ePropulsion Technology Ltd.)" 1452 "Micro-Air LLC" 1453 "Vital Battery" 1458 "Ride Controller LLC" 1460 "Tocaro Blue" 1461 "Vanquish Yachts" 1471 "FT Technologies" 1478 "Alps Alpine Co., Ltd." 1481 "E-Force Marine" 1482 "CMC Marine" 1483 "Nanjing Sandemarine Information Technology Co., Ltd." 1850 "Teleflex Marine (SeaStar Solutions)" 1851 "Raymarine" 1852 "Navionics" 1853 "Japan Radio Co" 1854 "Northstar Technologies" 1855 "Furuno" 1856 "Trimble" 1857 "Simrad" 1858 "Litton" 1859 "Kvasar AB" 1860 "MMP" 1861 "Vector Cantech" 1862 "Yamaha Marine" 1863 "Faria Instruments" ;
VAL_ 2566859774 dataType 0 "Heading" 1 "Navigation" 2 "Position" 3 "Apparent Wind" 4 "True Wind" 5 "Speed Through Water" 6 "Sea Temperature" 7 "Distance Log" 8 "Depth" 9 "Rudder Feedback" 19 "Monitor Compass" 20 "Position Backup" 21 "Boat Speed Backup" 22 "Air Temperature" 28 "Barometric Pressure" 30 "Heel Angle" 34 "Sailing Navigation" 35 "Trim Angle" 36 "Sailing" 37 "Aft Depth" 38 "Speed Log" 39 "RTCM Signal" 40 "RTCM Corrections" 54 "Autopilot" 59 "Autopilot Function Backup" 104 "Autopilot Control" ;
VAL_ 2566859774 industryCode 0 "Global" 1 "Highway" 2 "Agriculture" 3 "Construction" 4 "Marine Industry" 5 "Industrial" ;
VAL_ 2566859774 manufacturerCode 69 "ARKS Enterprises, Inc." 78 "FW Murphy/Enovation Controls" 80 "Twin Disc" 85 "Kohler Power Systems" 88 "Hemisphere GPS Inc" 116 "BEP Marine" 135 "Airmar" 137 "Maretron" 140 "Lowrance" 144 "Mercury Marine" 147 "Nautibus Electronic GmbH" 148 "Blue Water Data" 154 "Westerbeke" 157 "ISSPRO Inc" 161 "Offshore Systems (UK) Ltd." 163 "Evinrude/BRP" 165 "CPAC Systems AB" 168 "Xantrex Technology Inc." 169 "Marlin Technologies, Inc." 172 "Yanmar Marine" 174 "Volvo Penta" 175 "Honda Marine" 176 "Carling Technologies Inc. (Moritz Aerospace)" 185 "Beede Instruments" 192 "Floscan Instrument Co. Inc." 193 "Nobletec" 198 "Mystic Valley Communications" 199 "Actia" 200 "Honda Marine 2" 201 "Disenos Y Technologia" 211 "Digital Switching Systems" 215 "Xintex/Atena" 224 "EMMI NETWORK S.L." 225 "Honda Marine 3" 228 "ZF" 229 "Garmin" 233 "Yacht Monitoring Solutions" 235 "Sailormade Marine Telemetry/Tetra Technology LTD" 243 "Eride" 250 "Honda Marine 4" 257 "Honda Motor Company LTD" 272 "Groco" 273 "Actisense" 274 "Amphenol LTW Technology" 275 "Navico" 283 "Hamilton Jet" 285 "Sea Recovery" 286 "Coelmo SRL Italy" 295 "BEP Marine 2" 304 "Empir Bus" 305 "NovAtel" 306 "Sleipner Motor AS" 307 "MBW Technologies" 311 "Fischer Panda" 315 "ICOM" 328 "Qwerty" 329 "Dief" 341 "Boening Automationstechnologie GmbH & Co. KG" 345 "Korean Maritime University" 351 "Thrane and Thrane" 355 "Mastervolt" 356 "Fischer Panda Generators" 358 "Victron Energy" 370 "Rolls Royce Marine" 373 "Electronic Design" 374 "Northern Lights" 378 "Glendinning" 381 "B & G" 384 "Rose Point Navigation Systems" 385 "Johnson Outdoors Marine Electronics Inc Geonav" 394 "Capi 2" 396 "Beyond Measure" 400 "Livorsi Marine" 404 "ComNav" 409 "Chetco" 419 "Fusion Electronics" 421 "Standard Horizon" 422 "True Heading AB" 426 "Egersund Marine Electronics AS" 427 "em-trak Marine Electronics" 431 "Tohatsu Co, JP" 437 "Digital Yacht" 438 "Comar Systems Limited" 440 "Cummins" 443 "VDO (aka Continental-Corporation)" 451 "Parker Hannifin aka Village Marine Tech" 459 "Alltek Marine Electronics Corp" 460 "SAN GIORGIO S.E.I.N" 466 "Veethree Electronics & Marine" 467 "Humminbird Marine Electronics" 470 "SI-TEX Marine Electronics" 471 "Sea Cross Marine AB" 475 "GME aka Standard Communications Pty LTD" 476 "Humminbird Marine Electronics 2" 478 "Ocean Sat BV" 481 "Chetco Digitial Instruments" 493 "Watcheye" 499 "Lcj Capteurs" 502 "Attwood Marine" 503 "Naviop S.R.L." 504 "Vesper Marine Ltd" 510 "Marinesoft Co. LTD" 513 "Simarine" 517 "NoLand Engineering" 518 "Transas USA" 529 "National Instruments Korea" 530 "National Marine Electronics Association" 532 "Onwa Marine" 540 "Webasto" 571 "Marinecraft (South Korea)" 573 "McMurdo Group aka Orolia LTD" 578 "Advansea" 579 "KVH" 580 "San Jose Technology" 583 "Yacht Control" 586 "Suzuki Motor Corporation" 591 "US Coast Guard" 595 "Ship Module aka Customware" 600 "Aquatic AV" 605 "Aventics GmbH" 606 "Intellian" 612 "SamwonIT" 614 "Arlt Tecnologies" 637 "Bavaria Yacts" 641 "Diverse Yacht Services" 644 "Wema U.S.A dba KUS" 645 "Garmin 2" 658 "Shenzhen Jiuzhou Himunication" 688 "Rockford Corp" 699 "Harman International" 704 "JL Audio" 708 "Lars Thrane" 715 "Autonnic" 717 "Yacht Devices" 734 "REAP Systems" 735 "Au Electronics Group" 739 "LxNav" 741 "Littelfuse, Inc (formerly Carling Technologies)" 743 "DaeMyung" 744 "Woosung" 748 "ISOTTA IFRA srl" 772 "Blink Marine" 773 "Clarion US" 776 "HMI Systems" 777 "Ocean Signal" 778 "Seekeeper" 781 "Poly Planar" 785 "Fischer Panda DE" 795 "Broyda Industries" 796 "Canadian Automotive" 797 "Tides Marine" 798 "Lumishore" 799 "Still Water Designs and Audio" 802 "BJ Technologies (Beneteau)" 803 "Gill Sensors" 811 "Blue Water Desalination" 815 "FLIR" 824 "Undheim Systems" 826 "Lewmar Inc" 838 "TeamSurv" 844 "Fell Marine" 847 "Oceanvolt" 862 "Prospec" 868 "Data Panel Corp" 890 "L3 Technologies" 894 "Rhodan Marine Systems" 896 "Nexfour Solutions" 905 "ASA Electronics" 909 "Marines Co (South Korea)" 911 "Nautic-on" 917 "Sentinel" 929 "JL Marine ystems" 930 "Ecotronix" 944 "Zontisa Marine" 951 "EXOR International" 962 "Timbolier Industries" 963 "TJC Micro" 968 "Cox Powertrain" 969 "Blue Seas" 981 "Kobelt Manufacturing Co. Ltd" 992 "Blue Ocean IOT" 997 "Xenta Systems" 999 "Signal K" 1004 "Ultraflex SpA" 1008 "Lintest SmartBoat" 1011 "Soundmax" 1020 "Team Italia Marine (Onyx Marine Automation s.r.l)" 1021 "Entratech" 1022 "ITC Inc." 1029 "The Marine Guardian LLC" 1047 "Sonic Corporation" 1051 "ProNav" 1053 "Vetus Maxwell INC." 1056 "Lithium Pros" 1059 "Boatrax" 1062 "Marol Co ltd" 1065 "CALYPSO Instruments" 1066 "Spot Zero Water" 1069 "Lithionics Battery LLC" 1070 "Quick-teck Electronics Ltd" 1075 "Uniden America" 1083 "Nauticoncept" 1084 "Shadow-Caster LED lighting LLC" 1085 "Wet Sounds, LLC" 1088 "E-T-A Circuit Breakers" 1092 "Scheiber" 1100 "Smart Yachts International Limited" 1109 "Dockmate" 1114 "Bobs Machine" 1118 "L3Harris ASV" 1119 "Balmar LLC" 1120 "Elettromedia spa" 1127 "Electromaax" 1140 "Across Oceans Systems Ltd." 1145 "Kiwi Yachting" 1150 "BSB Artificial Intelligence GmbH" 1151 "Orca Technologoes AS" 1154 "TBS Electronics BV" 1158 "Technoton Electroics" 1160 "MG Energy Systems B.V." 1169 "Sea Macine Robotics Inc." 1171 "Vista Manufacturing" 1183 "Zipwake" 1186 "Sailmon BV" 1192 "Airmoniq Pro Kft" 1194 "Sierra Marine" 1200 "Xinuo Information Technology (Xiamen)" 1218 "Septentrio" 1233 "NKE Marine Elecronics" 1238 "SuperTrack Aps" 1239 "Honda Electronics Co., LTD" 1245 "Raritan Engineering Company, Inc" 1249 "Integrated Power Solutions AG" 1260 "Interactive Technologies, Inc." 1283 "LTG-Tech" 1299 "Energy Solutions (UK) LTD." 1300 "WATT Fuel Cell Corp" 1302 "Pro Mainer" 1305 "Dragonfly Energy" 1306 "Koden Electronics Co., Ltd" 1311 "Humphree AB" 1316 "Hinkley Yachts" 1317 "Global Marine Management GmbH (GMM)" 1320 "Triskel Marine Ltd" 1330 "Warwick Control Technologies" 1331 "Dolphin Charger" 1337 "Barnacle Systems Inc" 1348 "Radian IoT, Inc." 1353 "Ocean LED Marine Ltd" 1359 "BluNav" 1361 "OVA (Nantong Saiyang Electronics Co., Ltd)" 1368 "RAD Propulsion" 1369 "Electric Yacht" 1372 "Elco Motor Yachts" 1384 "Tecnoseal Foundry S.r.l" 1385 "Pro Charging Systems, LLC" 1389 "EVEX Co., LTD" 1398 "Gobius Sensor Technology AB" 1403 "Arco Marine" 1408 "Lenco Marine Inc." 1413 "Naocontrol S.L." 1417 "Revatek" 1438 "Aeolionics" 1439 "PredictWind Ltd" 1440 "Egis Mobile Electric" 1445 "Starboard Yacht Group" 1446 "Roswell Marine" 1451 "ePropulsion (Guangdong ePropulsion Technology Ltd.)" 1452 "Micro-Air LLC" 1453 "Vital Battery" 1458 "Ride Controller LLC" 1460 "Tocaro Blue" 1461 "Vanquish Yachts" 1471 "FT Technologies" 1478 "Alps Alpine Co., Ltd." 1481 "E-Force Marine" 1482 "CMC Marine" 1483 "Nanjing Sandemarine Information Technology Co., Ltd." 1850 "Teleflex Marine (SeaStar Solutions)" 1851 "Raymarine" 1852 "Navionics" 1853 "Japan Radio Co" 1854 "Northstar Technologies" 1855 "Furuno" 1856 "Trimble" 1857 "Simrad" 1858 "Litton" 1859 "Kvasar AB" 1860 "MMP" 1861 "Vector Cantech" 1862 "Yamaha Marine" 1863 "Faria Instruments" ;
VAL_ 2566860030 industryCode 0 "Global" 1 "Highway" 2 "Agriculture" 3 "Construction" 4 "Marine Industry" 5 "Industrial" ;
VAL_ 2566860030 manufacturerCode 69 "ARKS Enterprises, Inc." 78 "FW Murphy/Enovation Controls" 80 "Twin Disc" 85 "Kohler Power Systems" 88 "Hemisphere GPS Inc" 116 "BEP Marine" 135 "Airmar" 137 "Maretron" 140 "Lowrance" 144 "Mercury Marine" 147 "Nautibus Electronic GmbH" 148 "Blue Water Data" 154 "Westerbeke" 157 "ISSPRO Inc" 161 "Offshore Systems (UK) Ltd." 163 "Evinrude/BRP" 165 "CPAC Systems AB" 168 "Xantrex Technology Inc." 169 "Marlin Technologies, Inc." 172 "Yanmar Marine" 174 "Volvo Penta" 175 "Honda Marine" 176 "Carling Technologies Inc. (Moritz Aerospace)" 185 "Beede Instruments" 192 "Floscan Instrument Co. Inc." 193 "Nobletec" 198 "Mystic Valley Communications" 199 "Actia" 200 "Honda Marine 2" 201 "Disenos Y Technologia" 211 "Digital Switching Systems" 215 "Xintex/Atena" 224 "EMMI NETWORK S.L." 225 "Honda Marine 3" 228 "ZF" 229 "Garmin" 233 "Yacht Monitoring Solutions" 235 "Sailormade Marine Telemetry/Tetra Technology LTD" 243 "Eride" 250 "Honda Marine 4" 257 "Honda Motor Company LTD" 272 "Groco" 273 "Actisense" 274 "Amphenol LTW Technology" 275 "Navico" 283 "Hamilton Jet" 285 "Sea Recovery" 286 "Coelmo SRL Italy" 295 "BEP Marine 2" 304 "Empir Bus" 305 "NovAtel" 306 "Sleipner Motor AS" 307 "MBW Technologies" 311 "Fischer Panda" 315 "ICOM" 328 "Qwerty" 329 "Dief" 341 "Boening Automationstechnologie GmbH & Co. KG" 345 "Korean Maritime University" 351 "Thrane and Thrane" 355 "Mastervolt" 356 "Fischer Panda Generators" 358 "Victron Energy" 370 "Rolls Royce Marine" 373 "Electronic Design" 374 "Northern Lights" 378 "Glendinning" 381 "B & G" 384 "Rose Point Navigation Systems" 385 "Johnson Outdoors Marine Electronics Inc Geonav" 394 "Capi 2" 396 "Beyond Measure" 400 "Livorsi Marine" 404 "ComNav" 409 "Chetco" 419 "Fusion Electronics" 421 "Standard Horizon" 422 "True Heading AB" 426 "Egersund Marine Electronics AS" 427 "em-trak Marine Electronics" 431 "Tohatsu Co, JP" 437 "Digital Yacht" 438 "Comar Systems Limited" 440 "Cummins" 443 "VDO (aka Continental-Corporation)" 451 "Parker Hannifin aka Village Marine Tech" 459 "Alltek Marine Electronics Corp" 460 "SAN GIORGIO S.E.I.N" 466 "Veethree Electronics & Marine" 467 "Humminbird Marine Electronics" 470 "SI-TEX Marine Electronics" 471 "Sea Cross Marine AB" 475 "GME aka Standard Communications Pty LTD" 476 "Humminbird Marine Electronics 2" 478 "Ocean Sat BV" 481 "Chetco Digitial Instruments" 493 "Watcheye" 499 "Lcj Capteurs" 502 "Attwood Marine" 503 "Naviop S.R.L." 504 "Vesper Marine Ltd" 510 "Marinesoft Co. LTD" 513 "Simarine" 517 "NoLand Engineering" 518 "Transas USA" 529 "National Instruments Korea" 530 "National Marine Electronics Association" 532 "Onwa Marine" 540 "Webasto" 571 "Marinecraft (South Korea)" 573 "McMurdo Group aka Orolia LTD" 578 "Advansea" 579 "KVH" 580 "San Jose Technology" 583 "Yacht Control" 586 "Suzuki Motor Corporation" 591 "US Coast Guard" 595 "Ship Module aka Customware" 600 "Aquatic AV" 605 "Aventics GmbH" 606 "Intellian" 612 "SamwonIT" 614 "Arlt Tecnologies" 637 "Bavaria Yacts" 641 "Diverse Yacht Services" 644 "Wema U.S.A dba KUS" 645 "Garmin 2" 658 "Shenzhen Jiuzhou Himunication" 688 "Rockford Corp" 699 "Harman International" 704 "JL Audio" 708 "Lars Thrane" 715 "Autonnic" 717 "Yacht Devices" 734 "REAP Systems" 735 "Au Electronics Group" 739 "LxNav" 741 "Littelfuse, Inc (formerly Carling Technologies)" 743 "DaeMyung" 744 "Woosung" 748 "ISOTTA IFRA srl" 772 "Blink Marine" 773 "Clarion US" 776 "HMI Systems" 777 "Ocean Signal" 778 "Seekeeper" 781 "Poly Planar" 785 "Fischer Panda DE" 795 "Broyda Industries" 796 "Canadian Automotive" 797 "Tides Marine" 798 "Lumishore" 799 "Still Water Designs and Audio" 802 "BJ Technologies (Beneteau)" 803 "Gill Sensors" 811 "Blue Water Desalination" 815 "FLIR" 824 "Undheim Systems" 826 "Lewmar Inc" 838 "TeamSurv" 844 "Fell Marine" 847 "Oceanvolt" 862 "Prospec" 868 "Data Panel Corp" 890 "L3 Technologies" 894 "Rhodan Marine Systems" 896 "Nexfour Solutions" 905 "ASA Electronics" 909 "Marines Co (South Korea)" 911 "Nautic-on" 917 "Sentinel" 929 "JL Marine ystems" 930 "Ecotronix" 944 "Zontisa Marine" 951 "EXOR International" 962 "Timbolier Industries" 963 "TJC Micro" 968 "Cox Powertrain" 969 "Blue Seas" 981 "Kobelt Manufacturing Co. Ltd" 992 "Blue Ocean IOT" 997 "Xenta Systems" 999 "Signal K" 1004 "Ultraflex SpA" 1008 "Lintest SmartBoat" 1011 "Soundmax" 1020 "Team Italia Marine (Onyx Marine Automation s.r.l)" 1021 "Entratech" 1022 "ITC Inc." 1029 "The Marine Guardian LLC" 1047 "Sonic Corporation" 1051 "ProNav" 1053 "Vetus Maxwell INC." 1056 "Lithium Pros" 1059 "Boatrax" 1062 "Marol Co ltd" 1065 "CALYPSO Instruments" 1066 "Spot Zero Water" 1069 "Lithionics Battery LLC" 1070 "Quick-teck Electronics Ltd" 1075 "Uniden America" 1083 "Nauticoncept" 1084 "Shadow-Caster LED lighting LLC" 1085 "Wet Sounds, LLC" 1088 "E-T-A Circuit Breakers" 1092 "Scheiber" 1100 "Smart Yachts International Limited" 1109 "Dockmate" 1114 "Bobs Machine" 1118 "L3Harris ASV" 1119 "Balmar LLC" 1120 "Elettromedia spa" 1127 "Electromaax" 1140 "Across Oceans Systems Ltd." 1145 "Kiwi Yachting" 1150 "BSB Artificial Intelligence GmbH" 1151 "Orca Technologoes AS" 1154 "TBS Electronics BV" 1158 "Technoton Electroics" 1160 "MG Energy Systems B.V." 1169 "Sea Macine Robotics Inc." 1171 "Vista Manufacturing" 1183 "Zipwake" 1186 "Sailmon BV" 1192 "Airmoniq Pro Kft" 1194 "Sierra Marine" 1200 "Xinuo Information Technology (Xiamen)" 1218 "Septentrio" 1233 "NKE Marine Elecronics" 1238 "SuperTrack Aps" 1239 "Honda Electronics Co., LTD" 1245 "Raritan Engineering Company, Inc" 1249 "Integrated Power Solutions AG" 1260 "Interactive Technologies, Inc." 1283 "LTG-Tech" 1299 "Energy Solutions (UK) LTD." 1300 "WATT Fuel Cell Corp" 1302 "Pro Mainer" 1305 "Dragonfly Energy" 1306 "Koden Electronics Co., Ltd" 1311 "Humphree AB" 1316 "Hinkley Yachts" 1317 "Global Marine Management GmbH (GMM)" 1320 "Triskel Marine Ltd" 1330 "Warwick Control Technologies" 1331 "Dolphin Charger" 1337 "Barnacle Systems Inc" 1348 "Radian IoT, Inc." 1353 "Ocean LED Marine Ltd" 1359 "BluNav" 1361 "OVA (Nantong Saiyang Electronics Co., Ltd)" 1368 "RAD Propulsion" 1369 "Electric Yacht" 1372 "Elco Motor Yachts" 1384 "Tecnoseal Foundry S.r.l" 1385 "Pro Charging Systems, LLC" 1389 "EVEX Co., LTD" 1398 "Gobius Sensor Technology AB" 1403 "Arco Marine" 1408 "Lenco Marine Inc." 1413 "Naocontrol S.L." 1417 "Revatek" 1438 "Aeolionics" 1439 "PredictWind Ltd" 1440 "Egis Mobile Electric" 1445 "Starboard Yacht Group" 1446 "Roswell Marine" 1451 "ePropulsion (Guangdong ePropulsion Technology Ltd.)" 1452 "Micro-Air LLC" 1453 "Vital Battery" 1458 "Ride Controller LLC" 1460 "Tocaro Blue" 1461 "Vanquish Yachts" 1471 "FT Technologies" 1478 "Alps Alpine Co., Ltd." 1481 "E-Force Marine" 1482 "CMC Marine" 1483 "Nanjing Sandemarine Information Technology Co., Ltd." 1850 "Teleflex Marine (SeaStar Solutions)" 1851 "Raymarine" 1852 "Navionics" 1853 "Japan Radio Co" 1854 "Northstar Technologies" 1855 "Furuno" 1856 "Trimble" 1857 "Simrad" 1858 "Litton" 1859 "Kvasar AB" 1860 "MMP" 1861 "Vector Cantech" 1862 "Yamaha Marine" 1863 "Faria Instruments" ;
VAL_ 2566860286 industryCode 0 "Global" 1 "Highway" 2 "Agriculture" 3 "Construction" 4 "Marine Industry" 5 "Industrial" ;
VAL_ 2566860286 manufacturerCode 69 "ARKS Enterprises, Inc." 78 "FW Murphy/Enovation Controls" 80 "Twin Disc" 85 "Kohler Power Systems" 88 "Hemisphere GPS Inc" 116 "BEP Marine" 135 "Airmar" 137 "Maretron" 140 "Lowrance" 144 "Mercury Marine" 147 "Nautibus Electronic GmbH" 148 "Blue Water Data" 154 "Westerbeke" 157 "ISSPRO Inc" 161 "Offshore Systems (UK) Ltd." 163 "Evinrude/BRP" 165 "CPAC Systems AB" 168 "Xantrex Technology Inc." 169 "Marlin Technologies, Inc." 172 "Yanmar Marine" 174 "Volvo Penta" 175 "Honda Marine" 176 "Carling Technologies Inc. (Moritz Aerospace)" 185 "Beede Instruments" 192 "Floscan Instrument Co. Inc." 193 "Nobletec" 198 "Mystic Valley Communications" 199 "Actia" 200 "Honda Marine 2" 201 "Disenos Y Technologia" 211 "Digital Switching Systems" 215 "Xintex/Atena" 224 "EMMI NETWORK S.L." 225 "Honda Marine 3" 228 "ZF" 229 "Garmin" 233 "Yacht Monitoring Solutions" 235 "Sailormade Marine Telemetry/Tetra Technology LTD" 243 "Eride" 250 "Honda Marine 4" 257 "Honda Motor Company LTD" 272 "Groco" 273 "Actisense" 274 "Amphenol LTW Technology" 275 "Navico" 283 "Hamilton Jet" 285 "Sea Recovery" 286 "Coelmo SRL Italy" 295 "BEP Marine 2" 304 "Empir Bus" 305 "NovAtel" 306 "Sleipner Motor AS" 307 "MBW Technologies" 311 "Fischer Panda" 315 "ICOM" 328 "Qwerty" 329 "Dief" 341 "Boening Automationstechnologie GmbH & Co. KG" 345 "Korean Maritime University" 351 "Thrane and Thrane" 355 "Mastervolt" 356 "Fischer Panda Generators" 358 "Victron Energy" 370 "Rolls Royce Marine" 373 "Electronic Design" 374 "Northern Lights" 378 "Glendinning" 381 "B & G" 384 "Rose Point Navigation Systems" 385 "Johnson Outdoors Marine Electronics Inc Geonav" 394 "Capi 2" 396 "Beyond Measure" 400 "Livorsi Marine" 404 "ComNav" 409 "Chetco" 419 "Fusion Electronics" 421 "Standard Horizon" 422 "True Heading AB" 426 "Egersund Marine Electronics AS" 427 "em-trak Marine Electronics" 431 "Tohatsu Co, JP" 437 "Digital Yacht" 438 "Comar Systems Limited" 440 "Cummins" 443 "VDO (aka Continental-Corporation)" 451 "Parker Hannifin aka Village Marine Tech" 459 "Alltek Marine Electronics Corp" 460 "SAN GIORGIO S.E.I.N" 466 "Veethree Electronics & Marine" 467 "Humminbird Marine Electronics" 470 "SI-TEX Marine Electronics" 471 "Sea Cross Marine AB" 475 "GME aka Standard Communications Pty LTD" 476 "Humminbird Marine Electronics 2" 478 "Ocean Sat BV" 481 "Chetco Digitial Instruments" 493 "Watcheye" 499 "Lcj Capteurs" 502 "Attwood Marine" 503 "Naviop S.R.L." 504 "Vesper Marine Ltd" 510 "Marinesoft Co. LTD" 513 "Simarine" 517 "NoLand Engineering" 518 "Transas USA" 529 "National Instruments Korea" 530 "National Marine Electronics Association" 532 "Onwa Marine" 540 "Webasto" 571 "Marinecraft (South Korea)" 573 "McMurdo Group aka Orolia LTD" 578 "Advansea" 579 "KVH" 580 "San Jose Technology" 583 "Yacht Control" 586 "Suzuki Motor Corporation" 591 "US Coast Guard" 595 "Ship Module aka Customware" 600 "Aquatic AV" 605 "Aventics GmbH" 606 "Intellian" 612 "SamwonIT" 614 "Arlt Tecnologies" 637 "Bavaria Yacts" 641 "Diverse Yacht Services" 644 "Wema U.S.A dba KUS" 645 "Garmin 2" 658 "Shenzhen Jiuzhou Himunication" 688 "Rockford Corp" 699 "Harman International" 704 "JL Audio" 708 "Lars Thrane" 715 "Autonnic" 717 "Yacht Devices" 734 "REAP Systems" 735 "Au Electronics Group" 739 "LxNav" 741 "Littelfuse, Inc (formerly Carling Technologies)" 743 "DaeMyung" 744 "Woosung" 748 "ISOTTA IFRA srl" 772 "Blink Marine" 773 "Clarion US" 776 "HMI Systems" 777 "Ocean Signal" 778 "Seekeeper" 781 "Poly Planar" 785 "Fischer Panda DE" 795 "Broyda Industries" 796 "Canadian Automotive" 797 "Tides Marine" 798 "Lumishore" 799 "Still Water Designs and Audio" 802 "BJ Technologies (Beneteau)" 803 "Gill Sensors" 811 "Blue Water Desalination" 815 "FLIR" 824 "Undheim Systems" 826 "Lewmar Inc" 838 "TeamSurv" 844 "Fell Marine" 847 "Oceanvolt" 862 "Prospec" 868 "Data Panel Corp" 890 "L3 Technologies" 894 "Rhodan Marine Systems" 896 "Nexfour Solutions" 905 "ASA Electronics" 909 "Marines Co (South Korea)" 911 "Nautic-on" 917 "Sentinel" 929 "JL Marine ystems" 930 "Ecotronix" 944 "Zontisa Marine" 951 "EXOR International" 962 "Timbolier Industries" 963 "TJC Micro" 968 "Cox Powertrain" 969 "Blue Seas" 981 "Kobelt Manufacturing Co. Ltd" 992 "Blue Ocean IOT" 997 "Xenta Systems" 999 "Signal K" 1004 "Ultraflex SpA" 1008 "Lintest SmartBoat" 1011 "Soundmax" 1020 "Team Italia Marine (Onyx Marine Automation s.r.l)" 1021 "Entratech" 1022 "ITC Inc." 1029 "The Marine Guardian LLC" 1047 "Sonic Corporation" 1051 "ProNav" 1053 "Vetus Maxwell INC." 1056 "Lithium Pros" 1059 "Boatrax" 1062 "Marol Co ltd" 1065 "CALYPSO Instruments" 1066 "Spot Zero Water" 1069 "Lithionics Battery LLC" 1070 "Quick-teck Electronics Ltd" 1075 "Uniden America" 1083 "Nauticoncept" 1084 "Shadow-Caster LED lighting LLC" 1085 "Wet Sounds, LLC" 1088 "E-T-A Circuit Breakers" 1092 "Scheiber" 1100 "Smart Yachts International Limited" 1109 "Dockmate" 1114 "Bobs Machine" 1118 "L3Harris ASV" 1119 "Balmar LLC" 1120 "Elettromedia spa" 1127 "Electromaax" 1140 "Across Oceans Systems Ltd." 1145 "Kiwi Yachting" 1150 "BSB Artificial Intelligence GmbH" 1151 "Orca Technologoes AS" 1154 "TBS Electronics BV" 1158 "Technoton Electroics" 1160 "MG Energy Systems B.V." 1169 "Sea Macine Robotics Inc." 1171 "Vista Manufacturing" 1183 "Zipwake" 1186 "Sailmon BV" 1192 "Airmoniq Pro Kft" 1194 "Sierra Marine" 1200 "Xinuo Information Technology (Xiamen)" 1218 "Septentrio" 1233 "NKE Marine Elecronics" 1238 "SuperTrack Aps" 1239 "Honda Electronics Co., LTD" 1245 "Raritan Engineering Company, Inc" 1249 "Integrated Power Solutions AG" 1260 "Interactive Technologies, Inc." 1283 "LTG-Tech" 1299 "Energy Solutions (UK) LTD." 1300 "WATT Fuel Cell Corp" 1302 "Pro Mainer" 1305 "Dragonfly Energy" 1306 "Koden Electronics Co., Ltd" 1311 "Humphree AB" 1316 "Hinkley Yachts" 1317 "Global Marine Management GmbH (GMM)" 1320 "Triskel Marine Ltd" 1330 "Warwick Control Technologies" 1331 "Dolphin Charger" 1337 "Barnacle Systems Inc" 1348 "Radian IoT, Inc." 1353 "Ocean LED Marine Ltd" 1359 "BluNav" 1361 "OVA (Nantong Saiyang Electronics Co., Ltd)" 1368 "RAD Propulsion" 1369 "Electric Yacht" 1372 "Elco Motor Yachts" 1384 "Tecnoseal Foundry S.r.l" 1385 "Pro Charging Systems, LLC" 1389 "EVEX Co., LTD" 1398 "Gobius Sensor Technology AB" 1403 "Arco Marine" 1408 "Lenco Marine Inc." 1413 "Naocontrol S.L." 1417 "Revatek" 1438 "Aeolionics" 1439 "PredictWind Ltd" 1440 "Egis Mobile Electric" 1445 "Starboard Yacht Group" 1446 "Roswell Marine" 1451 "ePropulsion (Guangdong ePropulsion Technology Ltd.)" 1452 "Micro-Air LLC" 1453 "Vital Battery" 1458 "Ride Controller LLC" 1460 "Tocaro Blue" 1461 "Vanquish Yachts" 1471 "FT Technologies" 1478 "Alps Alpine Co., Ltd." 1481 "E-Force Marine" 1482 "CMC Marine" 1483 "Nanjing Sandemarine Information Technology Co., Ltd." 1850 "Teleflex Marine (SeaStar Solutions)" 1851 "Raymarine" 1852 "Navionics" 1853 "Japan Radio Co" 1854 "Northstar Technologies" 1855 "Furuno" 1856 "Trimble" 1857 "Simrad" 1858 "Litton" 1859 "Kvasar AB" 1860 "MMP" 1861 "Vector Cantech" 1862 "Yamaha Marine" 1863 "Faria Instruments" ;
VAL_ 2566861310 industryCode 0 "Global" 1 "Highway" 2 "Agriculture" 3 "Construction" 4 "Marine Industry" 5 "Industrial" ;
VAL_ 2566861310 manufacturerCode 69 "ARKS Enterprises, Inc." 78 "FW Murphy/Enovation Controls" 80 "Twin Disc" 85 "Kohler Power Systems" 88 "Hemisphere GPS Inc" 116 "BEP Marine" 135 "Airmar" 137 "Maretron" 140 "Lowrance" 144 "Mercury Marine" 147 "Nautibus Electronic GmbH" 148 "Blue Water Data" 154 "Westerbeke" 157 "ISSPRO Inc" 161 "Offshore Systems (UK) Ltd." 163 "Evinrude/BRP" 165 "CPAC Systems AB" 168 "Xantrex Technology Inc." 169 "Marlin Technologies, Inc." 172 "Yanmar Marine" 174 "Volvo Penta" 175 "Honda Marine" 176 "Carling Technologies Inc. (Moritz Aerospace)" 185 "Beede Instruments" 192 "Floscan Instrument Co. Inc." 193 "Nobletec" 198 "Mystic Valley Communications" 199 "Actia" 200 "Honda Marine 2" 201 "Disenos Y Technologia" 211 "Digital Switching Systems" 215 "Xintex/Atena" 224 "EMMI NETWORK S.L." 225 "Honda Marine 3" 228 "ZF" 229 "Garmin" 233 "Yacht Monitoring Solutions" 235 "Sailormade Marine Telemetry/Tetra Technology LTD" 243 "Eride" 250 "Honda Marine 4" 257 "Honda Motor Company LTD" 272 "Groco" 273 "Actisense" 274 "Amphenol LTW Technology" 275 "Navico" 283 "Hamilton Jet" 285 "Sea Recovery" 286 "Coelmo SRL Italy" 295 "BEP Marine 2" 304 "Empir Bus" 305 "NovAtel" 306 "Sleipner Motor AS" 307 "MBW Technologies" 311 "Fischer Panda" 315 "ICOM" 328 "Qwerty" 329 "Dief" 341 "Boening Automationstechnologie GmbH & Co. KG" 345 "Korean Maritime University" 351 "Thrane and Thrane" 355 "Mastervolt" 356 "Fischer Panda Generators" 358 "Victron Energy" 370 "Rolls Royce Marine" 373 "Electronic Design" 374 "Northern Lights" 378 "Glendinning" 381 "B & G" 384 "Rose Point Navigation Systems" 385 "Johnson Outdoors Marine Electronics Inc Geonav" 394 "Capi 2" 396 "Beyond Measure" 400 "Livorsi Marine" 404 "ComNav" 409 "Chetco" 419 "Fusion Electronics" 421 "Standard Horizon" 422 "True Heading AB" 426 "Egersund Marine Electronics AS" 427 "em-trak Marine Electronics" 431 "Tohatsu Co, JP" 437 "Digital Yacht" 438 "Comar Systems Limited" 440 "Cummins" 443 "VDO (aka Continental-Corporation)" 451 "Parker Hannifin aka Village Marine Tech" 459 "Alltek Marine Electronics Corp" 460 "SAN GIORGIO S.E.I.N" 466 "Veethree Electronics & Marine" 467 "Humminbird Marine Electronics" 470 "SI-TEX Marine Electronics" 471 "Sea Cross Marine AB" 475 "GME aka Standard Communications Pty LTD" 476 "Humminbird Marine Electronics 2" 478 "Ocean Sat BV" 481 "Chetco Digitial Instruments" 493 "Watcheye" 499 "Lcj Capteurs" 502 "Attwood Marine" 503 "Naviop S.R.L." 504 "Vesper Marine Ltd" 510 "Marinesoft Co. LTD" 513 "Simarine" 517 "NoLand Engineering" 518 "Transas USA" 529 "National Instruments Korea" 530 "National Marine Electronics Association" 532 "Onwa Marine" 540 "Webasto" 571 "Marinecraft (South Korea)" 573 "McMurdo Group aka Orolia LTD" 578 "Advansea" 579 "KVH" 580 "San Jose Technology" 583 "Yacht Control" 586 "Suzuki Motor Corporation" 591 "US Coast Guard" 595 "Ship Module aka Customware" 600 "Aquatic AV" 605 "Aventics GmbH" 606 "Intellian" 612 "SamwonIT" 614 "Arlt Tecnologies" 637 "Bavaria Yacts" 641 "Diverse Yacht Services" 644 "Wema U.S.A dba KUS" 645 "Garmin 2" 658 "Shenzhen Jiuzhou Himunication" 688 "Rockford Corp" 699 "Harman International" 704 "JL Audio" 708 "Lars Thrane" 715 "Autonnic" 717 "Yacht Devices" 734 "REAP Systems" 735 "Au Electronics Group" 739 "LxNav" 741 "Littelfuse, Inc (formerly Carling Technologies)" 743 "DaeMyung" 744 "Woosung" 748 "ISOTTA IFRA srl" 772 "Blink Marine" 773 "Clarion US" 776 "HMI Systems" 777 "Ocean Signal" 778 "Seekeeper" 781 "Poly Planar" 785 "Fischer Panda DE" 795 "Broyda Industries" 796 "Canadian Automotive" 797 "Tides Marine" 798 "Lumishore" 799 "Still Water Designs and Audio" 802 "BJ Technologies (Beneteau)" 803 "Gill Sensors" 811 "Blue Water Desalination" 815 "FLIR" 824 "Undheim Systems" 826 "Lewmar Inc" 838 "TeamSurv" 844 "Fell Marine" 847 "Oceanvolt" 862 "Prospec" 868 "Data Panel Corp" 890 "L3 Technologies" 894 "Rhodan Marine Systems" 896 "Nexfour Solutions" 905 "ASA Electronics" 909 "Marines Co (South Korea)" 911 "Nautic-on" 917 "Sentinel" 929 "JL Marine ystems" 930 "Ecotronix" 944 "Zontisa Marine" 951 "EXOR International" 962 "Timbolier Industries" 963 "TJC Micro" 968 "Cox Powertrain" 969 "Blue Seas" 981 "Kobelt Manufacturing Co. Ltd" 992 "Blue Ocean IOT" 997 "Xenta Systems" 999 "Signal K" 1004 "Ultraflex SpA" 1008 "Lintest SmartBoat" 1011 "Soundmax" 1020 "Team Italia Marine (Onyx Marine Automation s.r.l)" 1021 "Entratech" 1022 "ITC Inc." 1029 "The Marine Guardian LLC" 1047 "Sonic Corporation" 1051 "ProNav" 1053 "Vetus Maxwell INC." 1056 "Lithium Pros" 1059 "Boatrax" 1062 "Marol Co ltd" 1065 "CALYPSO Instruments" 1066 "Spot Zero Water" 1069 "Lithionics Battery LLC" 1070 "Quick-teck Electronics Ltd" 1075 "Uniden America" 1083 "Nauticoncept" 1084 "Shadow-Caster LED lighting LLC" 1085 "Wet Sounds, LLC" 1088 "E-T-A Circuit Breakers" 1092 "Scheiber" 1100 "Smart Yachts International Limited" 1109 "Dockmate" 1114 "Bobs Machine" 1118 "L3Harris ASV" 1119 "Balmar LLC" 1120 "Elettromedia spa" 1127 "Electromaax" 1140 "Across Oceans Systems Ltd." 1145 "Kiwi Yachting" 1150 "BSB Artificial Intelligence GmbH" 1151 "Orca Technologoes AS" 1154 "TBS Electronics BV" 1158 "Technoton Electroics" 1160 "MG Energy Systems B.V." 1169 "Sea Macine Robotics Inc." 1171 "Vista Manufacturing" 1183 "Zipwake" 1186 "Sailmon BV" 1192 "Airmoniq Pro Kft" 1194 "Sierra Marine" 1200 "Xinuo Information Technology (Xiamen)" 1218 "Septentrio" 1233 "NKE Marine Elecronics" 1238 "SuperTrack Aps" 1239 "Honda Electronics Co., LTD" 1245 "Raritan Engineering Company, Inc" 1249 "Integrated Power Solutions AG" 1260 "Interactive Technologies, Inc." 1283 "LTG-Tech" 1299 "Energy Solutions (UK) LTD." 1300 "WATT Fuel Cell Corp" 1302 "Pro Mainer" 1305 "Dragonfly Energy" 1306 "Koden Electronics Co., Ltd" 1311 "Humphree AB" 1316 "Hinkley Yachts" 1317 "Global Marine Management GmbH (GMM)" 1320 "Triskel Marine Ltd" 1330 "Warwick Control Technologies" 1331 "Dolphin Charger" 1337 "Barnacle Systems Inc" 1348 "Radian IoT, Inc." 1353 "Ocean LED Marine Ltd" 1359 "BluNav" 1361 "OVA (Nantong Saiyang Electronics Co., Ltd)" 1368 "RAD Propulsion" 1369 "Electric Yacht" 1372 "Elco Motor Yachts" 1384 "Tecnoseal Foundry S.r.l" 1385 "Pro Charging Systems, LLC" 1389 "EVEX Co., LTD" 1398 "Gobius Sensor Technology AB" 1403 "Arco Marine" 1408 "Lenco Marine Inc." 1413 "Naocontrol S.L." 1417 "Revatek" 1438 "Aeolionics" 1439 "PredictWind Ltd" 1440 "Egis Mobile Electric" 1445 "Starboard Yacht Group" 1446 "Roswell Marine" 1451 "ePropulsion (Guangdong ePropulsion Technology Ltd.)" 1452 "Micro-Air LLC" 1453 "Vital Battery" 1458 "Ride Controller LLC" 1460 "Tocaro Blue" 1461 "Vanquish Yachts" 1471 "FT Technologies" 1478 "Alps Alpine Co., Ltd." 1481 "E-Force Marine" 1482 "CMC Marine" 1483 "Nanjing Sandemarine Information Technology Co., Ltd." 1850 "Teleflex Marine (SeaStar Solutions)" 1851 "Raymarine" 1852 "Navionics" 1853 "Japan Radio Co" 1854 "Northstar Technologies" 1855 "Furuno" 1856 "Trimble" 1857 "Simrad" 1858 "Litton" 1859 "Kvasar AB" 1860 "MMP" 1861 "Vector Cantech" 1862 "Yamaha Marine" 1863 "Faria Instruments" ;
VAL_ 2566861566 industryCode 0 "Global" 1 "Highway" 2 "Agriculture" 3 "Construction" 4 "Marine Industry" 5 "Industrial" ;
VAL_ 2566861566 manufacturerCode 69 "ARKS Enterprises, Inc." 78 "FW Murphy/Enovation Controls" 80 "Twin Disc" 85 "Kohler Power Systems" 88 "Hemisphere GPS Inc" 116 "BEP Marine" 135 "Airmar" 137 "Maretron" 140 "Lowrance" 144 "Mercury Marine" 147 "Nautibus Electronic GmbH" 148 "Blue Water Data" 154 "Westerbeke" 157 "ISSPRO Inc" 161 "Offshore Systems (UK) Ltd." 163 "Evinrude/BRP" 165 "CPAC Systems AB" 168 "Xantrex Technology Inc." 169 "Marlin Technologies, Inc." 172 "Yanmar Marine" 174 "Volvo Penta" 175 "Honda Marine" 176 "Carling Technologies Inc. (Moritz Aerospace)" 185 "Beede Instruments" 192 "Floscan Instrument Co. Inc." 193 "Nobletec" 198 "Mystic Valley Communications" 199 "Actia" 200 "Honda Marine 2" 201 "Disenos Y Technologia" 211 "Digital Switching Systems" 215 "Xintex/Atena" 224 "EMMI NETWORK S.L." 225 "Honda Marine 3" 228 "ZF" 229 "Garmin" 233 "Yacht Monitoring Solutions" 235 "Sailormade Marine Telemetry/Tetra Technology LTD" 243 "Eride" 250 "Honda Marine 4" 257 "Honda Motor Company LTD" 272 "Groco" 273 "Actisense" 274 "Amphenol LTW Technology" 275 "Navico" 283 "Hamilton Jet" 285 "Sea Recovery" 286 "Coelmo SRL Italy" 295 "BEP Marine 2" 304 "Empir Bus" 305 "NovAtel" 306 "Sleipner Motor AS" 307 "MBW Technologies" 311 "Fischer Panda" 315 "ICOM" 328 "Qwerty" 329 "Dief" 341 "Boening Automationstechnologie GmbH & Co. KG" 345 "Korean Maritime University" 351 "Thrane and Thrane" 355 "Mastervolt" 356 "Fischer Panda Generators" 358 "Victron Energy" 370 "Rolls Royce Marine" 373 "Electronic Design" 374 "Northern Lights" 378 "Glendinning" 381 "B & G" 384 "Rose Point Navigation Systems" 385 "Johnson Outdoors Marine Electronics Inc Geonav" 394 "Capi 2" 396 "Beyond Measure" 400 "Livorsi Marine" 404 "ComNav" 409 "Chetco" 419 "Fusion Electronics" 421 "Standard Horizon" 422 "True Heading AB" 426 "Egersund Marine Electronics AS" 427 "em-trak Marine Electronics" 431 "Tohatsu Co, JP" 437 "Digital Yacht" 438 "Comar Systems Limited" 440 "Cummins" 443 "VDO (aka Continental-Corporation)" 451 "Parker Hannifin aka Village Marine Tech" 459 "Alltek Marine Electronics Corp" 460 "SAN GIORGIO S.E.I.N" 466 "Veethree Electronics & Marine" 467 "Humminbird Marine Electronics" 470 "SI-TEX Marine Electronics" 471 "Sea Cross Marine AB" 475 "GME aka Standard Communications Pty LTD" 476 "Humminbird Marine Electronics 2" 478 "Ocean Sat BV" 481 "Chetco Digitial Instruments" 493 "Watcheye" 499 "Lcj Capteurs" 502 "Attwood Marine" 503 "Naviop S.R.L." 504 "Vesper Marine Ltd" 510 "Marinesoft Co. LTD" 513 "Simarine" 517 "NoLand Engineering" 518 "Transas USA" 529 "National Instruments Korea" 530 "National Marine Electronics Association" 532 "Onwa Marine" 540 "Webasto" 571 "Marinecraft (South Korea)" 573 "McMurdo Group aka Orolia LTD" 578 "Advansea" 579 "KVH" 580 "San Jose Technology" 583 "Yacht Control" 586 "Suzuki Motor Corporation" 591 "US Coast Guard" 595 "Ship Module aka Customware" 600 "Aquatic AV" 605 "Aventics GmbH" 606 "Intellian" 612 "SamwonIT" 614 "Arlt Tecnologies" 637 "Bavaria Yacts" 641 "Diverse Yacht Services" 644 "Wema U.S.A dba KUS" 645 "Garmin 2" 658 "Shenzhen Jiuzhou Himunication" 688 "Rockford Corp" 699 "Harman International" 704 "JL Audio" 708 "Lars Thrane" 715 "Autonnic" 717 "Yacht Devices" 734 "REAP Systems" 735 "Au Electronics Group" 739 "LxNav" 741 "Littelfuse, Inc (formerly Carling Technologies)" 743 "DaeMyung" 744 "Woosung" 748 "ISOTTA IFRA srl" 772 "Blink Marine" 773 "Clarion US" 776 "HMI Systems" 777 "Ocean Signal" 778 "Seekeeper" 781 "Poly Planar" 785 "Fischer Panda DE" 795 "Broyda Industries" 796 "Canadian Automotive" 797 "Tides Marine" 798 "Lumishore" 799 "Still Water Designs and Audio" 802 "BJ Technologies (Beneteau)" 803 "Gill Sensors" 811 "Blue Water Desalination" 815 "FLIR" 824 "Undheim Systems" 826 "Lewmar Inc" 838 "TeamSurv" 844 "Fell Marine" 847 "Oceanvolt" 862 "Prospec" 868 "Data Panel Corp" 890 "L3 Technologies" 894 "Rhodan Marine Systems" 896 "Nexfour Solutions" 905 "ASA Electronics" 909 "Marines Co (South Korea)" 911 "Nautic-on" 917 "Sentinel" 929 "JL Marine ystems" 930 "Ecotronix" 944 "Zontisa Marine" 951 "EXOR International" 962 "Timbolier Industries" 963 "TJC Micro" 968 "Cox Powertrain" 969 "Blue Seas" 981 "Kobelt Manufacturing Co. Ltd" 992 "Blue Ocean IOT" 997 "Xenta Systems" 999 "Signal K" 1004 "Ultraflex SpA" 1008 "Lintest SmartBoat" 1011 "Soundmax" 1020 "Team Italia Marine (Onyx Marine Automation s.r.l)" 1021 "Entratech" 1022 "ITC Inc." 1029 "The Marine Guardian LLC" 1047 "Sonic Corporation" 1051 "ProNav" 1053 "Vetus Maxwell INC." 1056 "Lithium Pros" 1059 "Boatrax" 1062 "Marol Co ltd" 1065 "CALYPSO Instruments" 1066 "Spot Zero Water" 1069 "Lithionics Battery LLC" 1070 "Quick-teck Electronics Ltd" 1075 "Uniden America" 1083 "Nauticoncept" 1084 "Shadow-Caster LED lighting LLC" 1085 "Wet Sounds, LLC" 1088 "E-T-A Circuit Breakers" 1092 "Scheiber" 1100 "Smart Yachts International Limited" 1109 "Dockmate" 1114 "Bobs Machine" 1118 "L3Harris ASV" 1119 "Balmar LLC" 1120 "Elettromedia spa" 1127 "Electromaax" 1140 "Across Oceans Systems Ltd." 1145 "Kiwi Yachting" 1150 "BSB Artificial Intelligence GmbH" 1151 "Orca Technologoes AS" 1154 "TBS Electronics BV" 1158 "Technoton Electroics" 1160 "MG Energy Systems B.V." 1169 "Sea Macine Robotics Inc." 1171 "Vista Manufacturing" 1183 "Zipwake" 1186 "Sailmon BV" 1192 "Airmoniq Pro Kft" 1194 "Sierra Marine" 1200 "Xinuo Information Technology (Xiamen)" 1218 "Septentrio" 1233 "NKE Marine Elecronics" 1238 "SuperTrack Aps" 1239 "Honda Electronics Co., LTD" 1245 "Raritan Engineering Company, Inc" 1249 "Integrated Power Solutions AG" 1260 "Interactive Technologies, Inc." 1283 "LTG-Tech" 1299 "Energy Solutions (UK) LTD." 1300 "WATT Fuel Cell Corp" 1302 "Pro Mainer" 1305 "Dragonfly Energy" 1306 "Koden Electronics Co., Ltd" 1311 "Humphree AB" 1316 "Hinkley Yachts" 1317 "Global Marine Management GmbH (GMM)" 1320 "Triskel Marine Ltd" 1330 "Warwick Control Technologies" 1331 "Dolphin Charger" 1337 "Barnacle Systems Inc" 1348 "Radian IoT, Inc." 1353 "Ocean LED Marine Ltd" 1359 "BluNav" 1361 "OVA (Nantong Saiyang Electronics Co., Ltd)" 1368 "RAD Propulsion" 1369 "Electric Yacht" 1372 "Elco Motor Yachts" 1384 "Tecnoseal Foundry S.r.l" 1385 "Pro Charging Systems, LLC" 1389 "EVEX Co., LTD" 1398 "Gobius Sensor Technology AB" 1403 "Arco Marine" 1408 "Lenco Marine Inc." 1413 "Naocontrol S.L." 1417 "Revatek" 1438 "Aeolionics" 1439 "PredictWind Ltd" 1440 "Egis Mobile Electric" 1445 "Starboard Yacht Group" 1446 "Roswell Marine" 1451 "ePropulsion (Guangdong ePropulsion Technology Ltd.)" 1452 "Micro-Air LLC" 1453 "Vital Battery" 1458 "Ride Controller LLC" 1460 "Tocaro Blue" 1461 "Vanquish Yachts" 1471 "FT Technologies" 1478 "Alps Alpine Co., Ltd." 1481 "E-Force Marine" 1482 "CMC Marine" 1483 "Nanjing Sandemarine Information Technology Co., Ltd." 1850 "Teleflex Marine (SeaStar Solutions)" 1851 "Raymarine" 1852 "Navionics" 1853 "Japan Radio Co" 1854 "Northstar Technologies" 1855 "Furuno" 1856 "Trimble" 1857 "Simrad" 1858 "Litton" 1859 "Kvasar AB" 1860 "MMP" 1861 "Vector Cantech" 1862 "Yamaha Marine" 1863 "Faria Instruments" ;
VAL_ 2566862078 industryCode 0 "Global" 1 "Highway" 2 "Agriculture" 3 "Construction" 4 "Marine Industry" 5 "Industrial" ;
VAL_ 2566862078 manufacturerCode 69 "ARKS Enterprises, Inc." 78 "FW Murphy/Enovation Controls" 80 "Twin Disc" 85 "Kohler Power Systems" 88 "Hemisphere GPS Inc" 116 "BEP Marine" 135 "Airmar" 137 "Maretron" 140 "Lowrance" 144 "Mercury Marine" 147 "Nautibus Electronic GmbH" 148 "Blue Water Data" 154 "Westerbeke" 157 "ISSPRO Inc" 161 "Offshore Systems (UK) Ltd." 163 "Evinrude/BRP" 165 "CPAC Systems AB" 168 "Xantrex Technology Inc." 169 "Marlin Technologies, Inc." 172 "Yanmar Marine" 174 "Volvo Penta" 175 "Honda Marine" 176 "Carling Technologies Inc. (Moritz Aerospace)" 185 "Beede Instruments" 192 "Floscan Instrument Co. Inc." 193 "Nobletec" 198 "Mystic Valley Communications" 199 "Actia" 200 "Honda Marine 2" 201 "Disenos Y Technologia" 211 "Digital Switching Systems" 215 "Xintex/Atena" 224 "EMMI NETWORK S.L." 225 "Honda Marine 3" 228 "ZF" 229 "Garmin" 233 "Yacht Monitoring Solutions" 235 "Sailormade Marine Telemetry/Tetra Technology LTD" 243 "Eride" 250 "Honda Marine 4" 257 "Honda Motor Company LTD" 272 "Groco" 273 "Actisense" 274 "Amphenol LTW Technology" 275 "Navico" 283 "Hamilton Jet" 285 "Sea Recovery" 286 "Coelmo SRL Italy" 295 "BEP Marine 2" 304 "Empir Bus" 305 "NovAtel" 306 "Sleipner Motor AS" 307 "MBW Technologies" 311 "Fischer Panda" 315 "ICOM" 328 "Qwerty" 329 "Dief" 341 "Boening Automationstechnologie GmbH & Co. KG" 345 "Korean Maritime University" 351 "Thrane and Thrane" 355 "Mastervolt" 356 "Fischer Panda Generators" 358 "Victron Energy" 370 "Rolls Royce Marine" 373 "Electronic Design" 374 "Northern Lights" 378 "Glendinning" 381 "B & G" 384 "Rose Point Navigation Systems" 385 "Johnson Outdoors Marine Electronics Inc Geonav" 394 "Capi 2" 396 "Beyond Measure" 400 "Livorsi Marine" 404 "ComNav" 409 "Chetco" 419 "Fusion Electronics" 421 "Standard Horizon" 422 "True Heading AB" 426 "Egersund Marine Electronics AS" 427 "em-trak Marine Electronics" 431 "Tohatsu Co, JP" 437 "Digital Yacht" 438 "Comar Systems Limited" 440 "Cummins" 443 "VDO (aka Continental-Corporation)" 451 "Parker Hannifin aka Village Marine Tech" 459 "Alltek Marine Electronics Corp" 460 "SAN GIORGIO S.E.I.N" 466 "Veethree Electronics & Marine" 467 "Humminbird Marine Electronics" 470 "SI-TEX Marine Electronics" 471 "Sea Cross Marine AB" 475 "GME aka Standard Communications Pty LTD" 476 "Humminbird Marine Electronics 2" 478 "Ocean Sat BV" 481 "Chetco Digitial Instruments" 493 "Watcheye" 499 "Lcj Capteurs" 502 "Attwood Marine" 503 "Naviop S.R.L." 504 "Vesper Marine Ltd" 510 "Marinesoft Co. LTD" 513 "Simarine" 517 "NoLand Engineering" 518 "Transas USA" 529 "National Instruments Korea" 530 "National Marine Electronics Association" 532 "Onwa Marine" 540 "Webasto" 571 "Marinecraft (South Korea)" 573 "McMurdo Group aka Orolia LTD" 578 "Advansea" 579 "KVH" 580 "San Jose Technology" 583 "Yacht Control" 586 "Suzuki Motor Corporation" 591 "US Coast Guard" 595 "Ship Module aka Customware" 600 "Aquatic AV" 605 "Aventics GmbH" 606 "Intellian" 612 "SamwonIT" 614 "Arlt Tecnologies" 637 "Bavaria Yacts" 641 "Diverse Yacht Services" 644 "Wema U.S.A dba KUS" 645 "Garmin 2" 658 "Shenzhen Jiuzhou Himunication" 688 "Rockford Corp" 699 "Harman International" 704 "JL Audio" 708 "Lars Thrane" 715 "Autonnic" 717 "Yacht Devices" 734 "REAP Systems" 735 "Au Electronics Group" 739 "LxNav" 741 "Littelfuse, Inc (formerly Carling Technologies)" 743 "DaeMyung" 744 "Woosung" 748 "ISOTTA IFRA srl" 772 "Blink Marine" 773 "Clarion US" 776 "HMI Systems" 777 "Ocean Signal" 778 "Seekeeper" 781 "Poly Planar" 785 "Fischer Panda DE" 795 "Broyda Industries" 796 "Canadian Automotive" 797 "Tides Marine" 798 "Lumishore" 799 "Still Water Designs and Audio" 802 "BJ Technologies (Beneteau)" 803 "Gill Sensors" 811 "Blue Water Desalination" 815 "FLIR" 824 "Undheim Systems" 826 "Lewmar Inc" 838 "TeamSurv" 844 "Fell Marine" 847 "Oceanvolt" 862 "Prospec" 868 "Data Panel Corp" 890 "L3 Technologies" 894 "Rhodan Marine Systems" 896 "Nexfour Solutions" 905 "ASA Electronics" 909 "Marines Co (South Korea)" 911 "Nautic-on" 917 "Sentinel" 929 "JL Marine ystems" 930 "Ecotronix" 944 "Zontisa Marine" 951 "EXOR International" 962 "Timbolier Industries" 963 "TJC Micro" 968 "Cox Powertrain" 969 "Blue Seas" 981 "Kobelt Manufacturing Co. Ltd" 992 "Blue Ocean IOT" 997 "Xenta Systems" 999 "Signal K" 1004 "Ultraflex SpA" 1008 "Lintest SmartBoat" 1011 "Soundmax" 1020 "Team Italia Marine (Onyx Marine Automation s.r.l)" 1021 "Entratech" 1022 "ITC Inc." 1029 "The Marine Guardian LLC" 1047 "Sonic Corporation" 1051 "ProNav" 1053 "Vetus Maxwell INC." 1056 "Lithium Pros" 1059 "Boatrax" 1062 "Marol Co ltd" 1065 "CALYPSO Instruments" 1066 "Spot Zero Water" 1069 "Lithionics Battery LLC" 1070 "Quick-teck Electronics Ltd" 1075 "Uniden America" 1083 "Nauticoncept" 1084 "Shadow-Caster LED lighting LLC" 1085 "Wet Sounds, LLC" 1088 "E-T-A Circuit Breakers" 1092 "Scheiber" 1100 "Smart Yachts International Limited" 1109 "Dockmate" 1114 "Bobs Machine" 1118 "L3Harris ASV" 1119 "Balmar LLC" 1120 "Elettromedia spa" 1127 "Electromaax" 1140 "Across Oceans Systems Ltd." 1145 "Kiwi Yachting" 1150 "BSB Artificial Intelligence GmbH" 1151 "Orca Technologoes AS" 1154 "TBS Electronics BV" 1158 "Technoton Electroics" 1160 "MG Energy Systems B.V." 1169 "Sea Macine Robotics Inc." 1171 "Vista Manufacturing" 1183 "Zipwake" 1186 "Sailmon BV" 1192 "Airmoniq Pro Kft" 1194 "Sierra Marine" 1200 "Xinuo Information Technology (Xiamen)" 1218 "Septentrio" 1233 "NKE Marine Elecronics" 1238 "SuperTrack Aps" 1239 "Honda Electronics Co., LTD" 1245 "Raritan Engineering Company, Inc" 1249 "Integrated Power Solutions AG" 1260 "Interactive Technologies, Inc." 1283 "LTG-Tech" 1299 "Energy Solutions (UK) LTD." 1300 "WATT Fuel Cell Corp" 1302 "Pro Mainer" 1305 "Dragonfly Energy" 1306 "Koden Electronics Co., Ltd" 1311 "Humphree AB" 1316 "Hinkley Yachts" 1317 "Global Marine Management GmbH (GMM)" 1320 "Triskel Marine Ltd" 1330 "Warwick Control Technologies" 1331 "Dolphin Charger" 1337 "Barnacle Systems Inc" 1348 "Radian IoT, Inc." 1353 "Ocean LED Marine Ltd" 1359 "BluNav" 1361 "OVA (Nantong Saiyang Electronics Co., Ltd)" 1368 "RAD Propulsion" 1369 "Electric Yacht" 1372 "Elco Motor Yachts" 1384 "Tecnoseal Foundry S.r.l" 1385 "Pro Charging Systems, LLC" 1389 "EVEX Co., LTD" 1398 "Gobius Sensor Technology AB" 1403 "Arco Marine" 1408 "Lenco Marine Inc." 1413 "Naocontrol S.L." 1417 "Revatek" 1438 "Aeolionics" 1439 "PredictWind Ltd" 1440 "Egis Mobile Electric" 1445 "Starboard Yacht Group" 1446 "Roswell Marine" 1451 "ePropulsion (Guangdong ePropulsion Technology Ltd.)" 1452 "Micro-Air LLC" 1453 "Vital Battery" 1458 "Ride Controller LLC" 1460 "Tocaro Blue" 1461 "Vanquish Yachts" 1471 "FT Technologies" 1478 "Alps Alpine Co., Ltd." 1481 "E-Force Marine" 1482 "CMC Marine" 1483 "Nanjing Sandemarine Information Technology Co., Ltd." 1850 "Teleflex Marine (SeaStar Solutions)" 1851 "Raymarine" 1852 "Navionics" 1853 "Japan Radio Co" 1854 "Northstar Technologies" 1855 "Furuno" 1856 "Trimble" 1857 "Simrad" 1858 "Litton" 1859 "Kvasar AB" 1860 "MMP" 1861 "Vector Cantech" 1862 "Yamaha Marine" 1863 "Faria Instruments" ;
VAL_ 2566864126 mode 0 "Standby" 1 "Heading" 3 "Mode 4" 4 "Wind" 5 "Non-Follow-Up" 6 "Navigation" ;
VAL_ 2566864126 modeClass 0 "Standby" 16 "Engaged" ;
VAL_ 2566864126 industryCode 0 "Global" 1 "Highway" 2 "Agriculture" 3 "Construction" 4 "Marine Industry" 5 "Industrial" ;
VAL_ 2566864126 manufacturerCode 69 "ARKS Enterprises, Inc." 78 "FW Murphy/Enovation Controls" 80 "Twin Disc" 85 "Kohler Power Systems" 88 "Hemisphere GPS Inc" 116 "BEP Marine" 135 "Airmar" 137 "Maretron" 140 "Lowrance" 144 "Mercury Marine" 147 "Nautibus Electronic GmbH" 148 "Blue Water Data" 154 "Westerbeke" 157 "ISSPRO Inc" 161 "Offshore Systems (UK) Ltd." 163 "Evinrude/BRP" 165 "CPAC Systems AB" 168 "Xantrex Technology Inc." 169 "Marlin Technologies, Inc." 172 "Yanmar Marine" 174 "Volvo Penta" 175 "Honda Marine" 176 "Carling Technologies Inc. (Moritz Aerospace)" 185 "Beede Instruments" 192 "Floscan Instrument Co. Inc." 193 "Nobletec" 198 "Mystic Valley Communications" 199 "Actia" 200 "Honda Marine 2" 201 "Disenos Y Technologia" 211 "Digital Switching Systems" 215 "Xintex/Atena" 224 "EMMI NETWORK S.L." 225 "Honda Marine 3" 228 "ZF" 229 "Garmin" 233 "Yacht Monitoring Solutions" 235 "Sailormade Marine Telemetry/Tetra Technology LTD" 243 "Eride" 250 "Honda Marine 4" 257 "Honda Motor Company LTD" 272 "Groco" 273 "Actisense" 274 "Amphenol LTW Technology" 275 "Navico" 283 "Hamilton Jet" 285 "Sea Recovery" 286 "Coelmo SRL Italy" 295 "BEP Marine 2" 304 "Empir Bus" 305 "NovAtel" 306 "Sleipner Motor AS" 307 "MBW Technologies" 311 "Fischer Panda" 315 "ICOM" 328 "Qwerty" 329 "Dief" 341 "Boening Automationstechnologie GmbH & Co. KG" 345 "Korean Maritime University" 351 "Thrane and Thrane" 355 "Mastervolt" 356 "Fischer Panda Generators" 358 "Victron Energy" 370 "Rolls Royce Marine" 373 "Electronic Design" 374 "Northern Lights" 378 "Glendinning" 381 "B & G" 384 "Rose Point Navigation Systems" 385 "Johnson Outdoors Marine Electronics Inc Geonav" 394 "Capi 2" 396 "Beyond Measure" 400 "Livorsi Marine" 404 "ComNav" 409 "Chetco" 419 "Fusion Electronics" 421 "Standard Horizon" 422 "True Heading AB" 426 "Egersund Marine Electronics AS" 427 "em-trak Marine Electronics" 431 "Tohatsu Co, JP" 437 "Digital Yacht" 438 "Comar Systems Limited" 440 "Cummins" 443 "VDO (aka Continental-Corporation)" 451 "Parker Hannifin aka Village Marine Tech" 459 "Alltek Marine Electronics Corp" 460 "SAN GIORGIO S.E.I.N" 466 "Veethree Electronics & Marine" 467 "Humminbird Marine Electronics" 470 "SI-TEX Marine Electronics" 471 "Sea Cross Marine AB" 475 "GME aka Standard Communications Pty LTD" 476 "Humminbird Marine Electronics 2" 478 "Ocean Sat BV" 481 "Chetco Digitial Instruments" 493 "Watcheye" 499 "Lcj Capteurs" 502 "Attwood Marine" 503 "Naviop S.R.L." 504 "Vesper Marine Ltd" 510 "Marinesoft Co. LTD" 513 "Simarine" 517 "NoLand Engineering" 518 "Transas USA" 529 "National Instruments Korea" 530 "National Marine Electronics Association" 532 "Onwa Marine" 540 "Webasto" 571 "Marinecraft (South Korea)" 573 "McMurdo Group aka Orolia LTD" 578 "Advansea" 579 "KVH" 580 "San Jose Technology" 583 "Yacht Control" 586 "Suzuki Motor Corporation" 591 "US Coast Guard" 595 "Ship Module aka Customware" 600 "Aquatic AV" 605 "Aventics GmbH" 606 "Intellian" 612 "SamwonIT" 614 "Arlt Tecnologies" 637 "Bavaria Yacts" 641 "Diverse Yacht Services" 644 "Wema U.S.A dba KUS" 645 "Garmin 2" 658 "Shenzhen Jiuzhou Himunication" 688 "Rockford Corp" 699 "Harman International" 704 "JL Audio" 708 "Lars Thrane" 715 "Autonnic" 717 "Yacht Devices" 734 "REAP Systems" 735 "Au Electronics Group" 739 "LxNav" 741 "Littelfuse, Inc (formerly Carling Technologies)" 743 "DaeMyung" 744 "Woosung" 748 "ISOTTA IFRA srl" 772 "Blink Marine" 773 "Clarion US" 776 "HMI Systems" 777 "Ocean Signal" 778 "Seekeeper" 781 "Poly Planar" 785 "Fischer Panda DE" 795 "Broyda Industries" 796 "Canadian Automotive" 797 "Tides Marine" 798 "Lumishore" 799 "Still Water Designs and Audio" 802 "BJ Technologies (Beneteau)" 803 "Gill Sensors" 811 "Blue Water Desalination" 815 "FLIR" 824 "Undheim Systems" 826 "Lewmar Inc" 838 "TeamSurv" 844 "Fell Marine" 847 "Oceanvolt" 862 "Prospec" 868 "Data Panel Corp" 890 "L3 Technologies" 894 "Rhodan Marine Systems" 896 "Nexfour Solutions" 905 "ASA Electronics" 909 "Marines Co (South Korea)" 911 "Nautic-on" 917 "Sentinel" 929 "JL Marine ystems" 930 "Ecotronix" 944 "Zontisa Marine" 951 "EXOR International" 962 "Timbolier Industries" 963 "TJC Micro" 968 "Cox Powertrain" 969 "Blue Seas" 981 "Kobelt Manufacturing Co. Ltd" 992 "Blue Ocean IOT" 997 "Xenta Systems" 999 "Signal K" 1004 "Ultraflex SpA" 1008 "Lintest SmartBoat" 1011 "Soundmax" 1020 "Team Italia Marine (Onyx Marine Automation s.r.l)" 1021 "Entratech" 1022 "ITC Inc." 1029 "The Marine Guardian LLC" 1047 "Sonic Corporation" 1051 "ProNav" 1053 "Vetus Maxwell INC." 1056 "Lithium Pros" 1059 "Boatrax" 1062 "Marol Co ltd" 1065 "CALYPSO Instruments" 1066 "Spot Zero Water" 1069 "Lithionics Battery LLC" 1070 "Quick-teck Electronics Ltd" 1075 "Uniden America" 1083 "Nauticoncept" 1084 "Shadow-Caster LED lighting LLC" 1085 "Wet Sounds, LLC" 1088 "E-T-A Circuit Breakers" 1092 "Scheiber" 1100 "Smart Yachts International Limited" 1109 "Dockmate" 1114 "Bobs Machine" 1118 "L3Harris ASV" 1119 "Balmar LLC" 1120 "Elettromedia spa" 1127 "Electromaax" 1140 "Across Oceans Systems Ltd." 1145 "Kiwi Yachting" 1150 "BSB Artificial Intelligence GmbH" 1151 "Orca Technologoes AS" 1154 "TBS Electronics BV" 1158 "Technoton Electroics" 1160 "MG Energy Systems B.V." 1169 "Sea Macine Robotics Inc." 1171 "Vista Manufacturing" 1183 "Zipwake" 1186 "Sailmon BV" 1192 "Airmoniq Pro Kft" 1194 "Sierra Marine" 1200 "Xinuo Information Technology (Xiamen)" 1218 "Septentrio" 1233 "NKE Marine Elecronics" 1238 "SuperTrack Aps" 1239 "Honda Electronics Co., LTD" 1245 "Raritan Engineering Company, Inc" 1249 "Integrated Power Solutions AG" 1260 "Interactive Technologies, Inc." 1283 "LTG-Tech" 1299 "Energy Solutions (UK) LTD." 1300 "WATT Fuel Cell Corp" 1302 "Pro Mainer" 1305 "Dragonfly Energy" 1306 "Koden Electronics Co., Ltd" 1311 "Humphree AB" 1316 "Hinkley Yachts" 1317 "Global Marine Management GmbH (GMM)" 1320 "Triskel Marine Ltd" 1330 "Warwick Control Technologies" 1331 "Dolphin Charger" 1337 "Barnacle Systems Inc" 1348 "Radian IoT, Inc." 1353 "Ocean LED Marine Ltd" 1359 "BluNav" 1361 "OVA (Nantong Saiyang Electronics Co., Ltd)" 1368 "RAD Propulsion" 1369 "Electric Yacht" 1372 "Elco Motor Yachts" 1384 "Tecnoseal Foundry S.r.l" 1385 "Pro Charging Systems, LLC" 1389 "EVEX Co., LTD" 1398 "Gobius Sensor Technology AB" 1403 "Arco Marine" 1408 "Lenco Marine Inc." 1413 "Naocontrol S.L." 1417 "Revatek" 1438 "Aeolionics" 1439 "PredictWind Ltd" 1440 "Egis Mobile Electric" 1445 "Starboard Yacht Group" 1446 "Roswell Marine" 1451 "ePropulsion (Guangdong ePropulsion Technology Ltd.)" 1452 "Micro-Air LLC" 1453 "Vital Battery" 1458 "Ride Controller LLC" 1460 "Tocaro Blue" 1461 "Vanquish Yachts" 1471 "FT Technologies" 1478 "Alps Alpine Co., Ltd." 1481 "E-Force Marine" 1482 "CMC Marine" 1483 "Nanjing Sandemarine Information Technology Co., Ltd." 1850 "Teleflex Marine (SeaStar Solutions)" 1851 "Raymarine" 1852 "Navionics" 1853 "Japan Radio Co" 1854 "Northstar Technologies" 1855 "Furuno" 1856 "Trimble" 1857 "Simrad" 1858 "Litton" 1859 "Kvasar AB" 1860 "MMP" 1861 "Vector Cantech" 1862 "Yamaha Marine" 1863 "Faria Instruments" ;
VAL_ 2566864382 mode 2 "Heading" 3 "Wind" 10 "Nav" 11 "No Drift" ;
VAL_ 2566864382 industryCode 0 "Global" 1 "Highway" 2 "Agriculture" 3 "Construction" 4 "Marine Industry" 5 "Industrial" ;
VAL_ 2566864382 manufacturerCode 69 "ARKS Enterprises, Inc." 78 "FW Murphy/Enovation Controls" 80 "Twin Disc" 85 "Kohler Power Systems" 88 "Hemisphere GPS Inc" 116 "BEP Marine" 135 "Airmar" 137 "Maretron" 140 "Lowrance" 144 "Mercury Marine" 147 "Nautibus Electronic GmbH" 148 "Blue Water Data" 154 "Westerbeke" 157 "ISSPRO Inc" 161 "Offshore Systems (UK) Ltd." 163 "Evinrude/BRP" 165 "CPAC Systems AB" 168 "Xantrex Technology Inc." 169 "Marlin Technologies, Inc." 172 "Yanmar Marine" 174 "Volvo Penta" 175 "Honda Marine" 176 "Carling Technologies Inc. (Moritz Aerospace)" 185 "Beede Instruments" 192 "Floscan Instrument Co. Inc." 193 "Nobletec" 198 "Mystic Valley Communications" 199 "Actia" 200 "Honda Marine 2" 201 "Disenos Y Technologia" 211 "Digital Switching Systems" 215 "Xintex/Atena" 224 "EMMI NETWORK S.L." 225 "Honda Marine 3" 228 "ZF" 229 "Garmin" 233 "Yacht Monitoring Solutions" 235 "Sailormade Marine Telemetry/Tetra Technology LTD" 243 "Eride" 250 "Honda Marine 4" 257 "Honda Motor Company LTD" 272 "Groco" 273 "Actisense" 274 "Amphenol LTW Technology" 275 "Navico" 283 "Hamilton Jet" 285 "Sea Recovery" 286 "Coelmo SRL Italy" 295 "BEP Marine 2" 304 "Empir Bus" 305 "NovAtel" 306 "Sleipner Motor AS" 307 "MBW Technologies" 311 "Fischer Panda" 315 "ICOM" 328 "Qwerty" 329 "Dief" 341 "Boening Automationstechnologie GmbH & Co. KG" 345 "Korean Maritime University" 351 "Thrane and Thrane" 355 "Mastervolt" 356 "Fischer Panda Generators" 358 "Victron Energy" 370 "Rolls Royce Marine" 373 "Electronic Design" 374 "Northern Lights" 378 "Glendinning" 381 "B & G" 384 "Rose Point Navigation Systems" 385 "Johnson Outdoors Marine Electronics Inc Geonav" 394 "Capi 2" 396 "Beyond Measure" 400 "Livorsi Marine" 404 "ComNav" 409 "Chetco" 419 "Fusion Electronics" 421 "Standard Horizon" 422 "True Heading AB" 426 "Egersund Marine Electronics AS" 427 "em-trak Marine Electronics" 431 "Tohatsu Co, JP" 437 "Digital Yacht" 438 "Comar Systems Limited" 440 "Cummins" 443 "VDO (aka Continental-Corporation)" 451 "Parker Hannifin aka Village Marine Tech" 459 "Alltek Marine Electronics Corp" 460 "SAN GIORGIO S.E.I.N" 466 "Veethree Electronics & Marine" 467 "Humminbird Marine Electronics" 470 "SI-TEX Marine Electronics" 471 "Sea Cross Marine AB" 475 "GME aka Standard Communications Pty LTD" 476 "Humminbird Marine Electronics 2" 478 "Ocean Sat BV" 481 "Chetco Digitial Instruments" 493 "Watcheye" 499 "Lcj Capteurs" 502 "Attwood Marine" 503 "Naviop S.R.L." 504 "Vesper Marine Ltd" 510 "Marinesoft Co. LTD" 513 "Simarine" 517 "NoLand Engineering" 518 "Transas USA" 529 "National Instruments Korea" 530 "National Marine Electronics Association" 532 "Onwa Marine" 540 "Webasto" 571 "Marinecraft (South Korea)" 573 "McMurdo Group aka Orolia LTD" 578 "Advansea" 579 "KVH" 580 "San Jose Technology" 583 "Yacht Control" 586 "Suzuki Motor Corporation" 591 "US Coast Guard" 595 "Ship Module aka Customware" 600 "Aquatic AV" 605 "Aventics GmbH" 606 "Intellian" 612 "SamwonIT" 614 "Arlt Tecnologies" 637 "Bavaria Yacts" 641 "Diverse Yacht Services" 644 "Wema U.S.A dba KUS" 645 "Garmin 2" 658 "Shenzhen Jiuzhou Himunication" 688 "Rockford Corp" 699 "Harman International" 704 "JL Audio" 708 "Lars Thrane" 715 "Autonnic" 717 "Yacht Devices" 734 "REAP Systems" 735 "Au Electronics Group" 739 "LxNav" 741 "Littelfuse, Inc (formerly Carling Technologies)" 743 "DaeMyung" 744 "Woosung" 748 "ISOTTA IFRA srl" 772 "Blink Marine" 773 "Clarion US" 776 "HMI Systems" 777 "Ocean Signal" 778 "Seekeeper" 781 "Poly Planar" 785 "Fischer Panda DE" 795 "Broyda Industries" 796 "Canadian Automotive" 797 "Tides Marine" 798 "Lumishore" 799 "Still Water Designs and Audio" 802 "BJ Technologies (Beneteau)" 803 "Gill Sensors" 811 "Blue Water Desalination" 815 "FLIR" 824 "Undheim Systems" 826 "Lewmar Inc" 838 "TeamSurv" 844 "Fell Marine" 847 "Oceanvolt" 862 "Prospec" 868 "Data Panel Corp" 890 "L3 Technologies" 894 "Rhodan Marine Systems" 896 "Nexfour Solutions" 905 "ASA Electronics" 909 "Marines Co (South Korea)" 911 "Nautic-on" 917 "Sentinel" 929 "JL Marine ystems" 930 "Ecotronix" 944 "Zontisa Marine" 951 "EXOR International" 962 "Timbolier Industries" 963 "TJC Micro" 968 "Cox Powertrain" 969 "Blue Seas" 981 "Kobelt Manufacturing Co. Ltd" 992 "Blue Ocean IOT" 997 "Xenta Systems" 999 "Signal K" 1004 "Ultraflex SpA" 1008 "Lintest SmartBoat" 1011 "Soundmax" 1020 "Team Italia Marine (Onyx Marine Automation s.r.l)" 1021 "Entratech" 1022 "ITC Inc." 1029 "The Marine Guardian LLC" 1047 "Sonic Corporation" 1051 "ProNav" 1053 "Vetus Maxwell INC." 1056 "Lithium Pros" 1059 "Boatrax" 1062 "Marol Co ltd" 1065 "CALYPSO Instruments" 1066 "Spot Zero Water" 1069 "Lithionics Battery LLC" 1070 "Quick-teck Electronics Ltd" 1075 "Uniden America" 1083 "Nauticoncept" 1084 "Shadow-Caster LED lighting LLC" 1085 "Wet Sounds, LLC" 1088 "E-T-A Circuit Breakers" 1092 "Scheiber" 1100 "Smart Yachts International Limited" 1109 "Dockmate" 1114 "Bobs Machine" 1118 "L3Harris ASV" 1119 "Balmar LLC" 1120 "Elettromedia spa" 1127 "Electromaax" 1140 "Across Oceans Systems Ltd." 1145 "Kiwi Yachting" 1150 "BSB Artificial Intelligence GmbH" 1151 "Orca Technologoes AS" 1154 "TBS Electronics BV" 1158 "Technoton Electroics" 1160 "MG Energy Systems B.V." 1169 "Sea Macine Robotics Inc." 1171 "Vista Manufacturing" 1183 "Zipwake" 1186 "Sailmon BV" 1192 "Airmoniq Pro Kft" 1194 "Sierra Marine" 1200 "Xinuo Information Technology (Xiamen)" 1218 "Septentrio" 1233 "NKE Marine Elecronics" 1238 "SuperTrack Aps" 1239 "Honda Electronics Co., LTD" 1245 "Raritan Engineering Company, Inc" 1249 "Integrated Power Solutions AG" 1260 "Interactive Technologies, Inc." 1283 "LTG-Tech" 1299 "Energy Solutions (UK) LTD." 1300 "WATT Fuel Cell Corp" 1302 "Pro Mainer" 1305 "Dragonfly Energy" 1306 "Koden Electronics Co., Ltd" 1311 "Humphree AB" 1316 "Hinkley Yachts" 1317 "Global Marine Management GmbH (GMM)" 1320 "Triskel Marine Ltd" 1330 "Warwick Control Technologies" 1331 "Dolphin Charger" 1337 "Barnacle Systems Inc" 1348 "Radian IoT, Inc." 1353 "Ocean LED Marine Ltd" 1359 "BluNav" 1361 "OVA (Nantong Saiyang Electronics Co., Ltd)" 1368 "RAD Propulsion" 1369 "Electric Yacht" 1372 "Elco Motor Yachts" 1384 "Tecnoseal Foundry S.r.l" 1385 "Pro Charging Systems, LLC" 1389 "EVEX Co., LTD" 1398 "Gobius Sensor Technology AB" 1403 "Arco Marine" 1408 "Lenco Marine Inc." 1413 "Naocontrol S.L." 1417 "Revatek" 1438 "Aeolionics" 1439 "PredictWind Ltd" 1440 "Egis Mobile Electric" 1445 "Starboard Yacht Group" 1446 "Roswell Marine" 1451 "ePropulsion (Guangdong ePropulsion Technology Ltd.)" 1452 "Micro-Air LLC" 1453 "Vital Battery" 1458 "Ride Controller LLC" 1460 "Tocaro Blue" 1461 "Vanquish Yachts" 1471 "FT Technologies" 1478 "Alps Alpine Co., Ltd." 1481 "E-Force Marine" 1482 "CMC Marine" 1483 "Nanjing Sandemarine Information Technology Co., Ltd." 1850 "Teleflex Marine (SeaStar Solutions)" 1851 "Raymarine" 1852 "Navionics" 1853 "Japan Radio Co" 1854 "Northstar Technologies" 1855 "Furuno" 1856 "Trimble" 1857 "Simrad" 1858 "Litton" 1859 "Kvasar AB" 1860 "MMP" 1861 "Vector Cantech" 1862 "Yamaha Marine" 1863 "Faria Instruments" ;
VAL_ 2566865150 industryCode 0 "Global" 1 "Highway" 2 "Agriculture" 3 "Construction" 4 "Marine Industry" 5 "Industrial" ;
VAL_ 2566865150 manufacturerCode 69 "ARKS Enterprises, Inc." 78 "FW Murphy/Enovation Controls" 80 "Twin Disc" 85 "Kohler Power Systems" 88 "Hemisphere GPS Inc" 116 "BEP Marine" 135 "Airmar" 137 "Maretron" 140 "Lowrance" 144 "Mercury Marine" 147 "Nautibus Electronic GmbH" 148 "Blue Water Data" 154 "Westerbeke" 157 "ISSPRO Inc" 161 "Offshore Systems (UK) Ltd." 163 "Evinrude/BRP" 165 "CPAC Systems AB" 168 "Xantrex Technology Inc." 169 "Marlin Technologies, Inc." 172 "Yanmar Marine" 174 "Volvo Penta" 175 "Honda Marine" 176 "Carling Technologies Inc. (Moritz Aerospace)" 185 "Beede Instruments" 192 "Floscan Instrument Co. Inc." 193 "Nobletec" 198 "Mystic Valley Communications" 199 "Actia" 200 "Honda Marine 2" 201 "Disenos Y Technologia" 211 "Digital Switching Systems" 215 "Xintex/Atena" 224 "EMMI NETWORK S.L." 225 "Honda Marine 3" 228 "ZF" 229 "Garmin" 233 "Yacht Monitoring Solutions" 235 "Sailormade Marine Telemetry/Tetra Technology LTD" 243 "Eride" 250 "Honda Marine 4" 257 "Honda Motor Company LTD" 272 "Groco" 273 "Actisense" 274 "Amphenol LTW Technology" 275 "Navico" 283 "Hamilton Jet" 285 "Sea Recovery" 286 "Coelmo SRL Italy" 295 "BEP Marine 2" 304 "Empir Bus" 305 "NovAtel" 306 "Sleipner Motor AS" 307 "MBW Technologies" 311 "Fischer Panda" 315 "ICOM" 328 "Qwerty" 329 "Dief" 341 "Boening Automationstechnologie GmbH & Co. KG" 345 "Korean Maritime University" 351 "Thrane and Thrane" 355 "Mastervolt" 356 "Fischer Panda Generators" 358 "Victron Energy" 370 "Rolls Royce Marine" 373 "Electronic Design" 374 "Northern Lights" 378 "Glendinning" 381 "B & G" 384 "Rose Point Navigation Systems" 385 "Johnson Outdoors Marine Electronics Inc Geonav" 394 "Capi 2" 396 "Beyond Measure" 400 "Livorsi Marine" 404 "ComNav" 409 "Chetco" 419 "Fusion Electronics" 421 "Standard Horizon" 422 "True Heading AB" 426 "Egersund Marine Electronics AS" 427 "em-trak Marine Electronics" 431 "Tohatsu Co, JP" 437 "Digital Yacht" 438 "Comar Systems Limited" 440 "Cummins" 443 "VDO (aka Continental-Corporation)" 451 "Parker Hannifin aka Village Marine Tech" 459 "Alltek Marine Electronics Corp" 460 "SAN GIORGIO S.E.I.N" 466 "Veethree Electronics & Marine" 467 "Humminbird Marine Electronics" 470 "SI-TEX Marine Electronics" 471 "Sea Cross Marine AB" 475 "GME aka Standard Communications Pty LTD" 476 "Humminbird Marine Electronics 2" 478 "Ocean Sat BV" 481 "Chetco Digitial Instruments" 493 "Watcheye" 499 "Lcj Capteurs" 502 "Attwood Marine" 503 "Naviop S.R.L." 504 "Vesper Marine Ltd" 510 "Marinesoft Co. LTD" 513 "Simarine" 517 "NoLand Engineering" 518 "Transas USA" 529 "National Instruments Korea" 530 "National Marine Electronics Association" 532 "Onwa Marine" 540 "Webasto" 571 "Marinecraft (South Korea)" 573 "McMurdo Group aka Orolia LTD" 578 "Advansea" 579 "KVH" 580 "San Jose Technology" 583 "Yacht Control" 586 "Suzuki Motor Corporation" 591 "US Coast Guard" 595 "Ship Module aka Customware" 600 "Aquatic AV" 605 "Aventics GmbH" 606 "Intellian" 612 "SamwonIT" 614 "Arlt Tecnologies" 637 "Bavaria Yacts" 641 "Diverse Yacht Services" 644 "Wema U.S.A dba KUS" 645 "Garmin 2" 658 "Shenzhen Jiuzhou Himunication" 688 "Rockford Corp" 699 "Harman International" 704 "JL Audio" 708 "Lars Thrane" 715 "Autonnic" 717 "Yacht Devices" 734 "REAP Systems" 735 "Au Electronics Group" 739 "LxNav" 741 "Littelfuse, Inc (formerly Carling Technologies)" 743 "DaeMyung" 744 "Woosung" 748 "ISOTTA IFRA srl" 772 "Blink Marine" 773 "Clarion US" 776 "HMI Systems" 777 "Ocean Signal" 778 "Seekeeper" 781 "Poly Planar" 785 "Fischer Panda DE" 795 "Broyda Industries" 796 "Canadian Automotive" 797 "Tides Marine" 798 "Lumishore" 799 "Still Water Designs and Audio" 802 "BJ Technologies (Beneteau)" 803 "Gill Sensors" 811 "Blue Water Desalination" 815 "FLIR" 824 "Undheim Systems" 826 "Lewmar Inc" 838 "TeamSurv" 844 "Fell Marine" 847 "Oceanvolt" 862 "Prospec" 868 "Data Panel Corp" 890 "L3 Technologies" 894 "Rhodan Marine Systems" 896 "Nexfour Solutions" 905 "ASA Electronics" 909 "Marines Co (South Korea)" 911 "Nautic-on" 917 "Sentinel" 929 "JL Marine ystems" 930 "Ecotronix" 944 "Zontisa Marine" 951 "EXOR International" 962 "Timbolier Industries" 963 "TJC Micro" 968 "Cox Powertrain" 969 "Blue Seas" 981 "Kobelt Manufacturing Co. Ltd" 992 "Blue Ocean IOT" 997 "Xenta Systems" 999 "Signal K" 1004 "Ultraflex SpA" 1008 "Lintest SmartBoat" 1011 "Soundmax" 1020 "Team Italia Marine (Onyx Marine Automation s.r.l)" 1021 "Entratech" 1022 "ITC Inc." 1029 "The Marine Guardian LLC" 1047 "Sonic Corporation" 1051 "ProNav" 1053 "Vetus Maxwell INC." 1056 "Lithium Pros" 1059 "Boatrax" 1062 "Marol Co ltd" 1065 "CALYPSO Instruments" 1066 "Spot Zero Water" 1069 "Lithionics Battery LLC" 1070 "Quick-teck Electronics Ltd" 1075 "Uniden America" 1083 "Nauticoncept" 1084 "Shadow-Caster LED lighting LLC" 1085 "Wet Sounds, LLC" 1088 "E-T-A Circuit Breakers" 1092 "Scheiber" 1100 "Smart Yachts International Limited" 1109 "Dockmate" 1114 "Bobs Machine" 1118 "L3Harris ASV" 1119 "Balmar LLC" 1120 "Elettromedia spa" 1127 "Electromaax" 1140 "Across Oceans Systems Ltd." 1145 "Kiwi Yachting" 1150 "BSB Artificial Intelligence GmbH" 1151 "Orca Technologoes AS" 1154 "TBS Electronics BV" 1158 "Technoton Electroics" 1160 "MG Energy Systems B.V." 1169 "Sea Macine Robotics Inc." 1171 "Vista Manufacturing" 1183 "Zipwake" 1186 "Sailmon BV" 1192 "Airmoniq Pro Kft" 1194 "Sierra Marine" 1200 "Xinuo Information Technology (Xiamen)" 1218 "Septentrio" 1233 "NKE Marine Elecronics" 1238 "SuperTrack Aps" 1239 "Honda Electronics Co., LTD" 1245 "Raritan Engineering Company, Inc" 1249 "Integrated Power Solutions AG" 1260 "Interactive Technologies, Inc." 1283 "LTG-Tech" 1299 "Energy Solutions (UK) LTD." 1300 "WATT Fuel Cell Corp" 1302 "Pro Mainer" 1305 "Dragonfly Energy" 1306 "Koden Electronics Co., Ltd" 1311 "Humphree AB" 1316 "Hinkley Yachts" 1317 "Global Marine Management GmbH (GMM)" 1320 "Triskel Marine Ltd" 1330 "Warwick Control Technologies" 1331 "Dolphin Charger" 1337 "Barnacle Systems Inc" 1348 "Radian IoT, Inc." 1353 "Ocean LED Marine Ltd" 1359 "BluNav" 1361 "OVA (Nantong Saiyang Electronics Co., Ltd)" 1368 "RAD Propulsion" 1369 "Electric Yacht" 1372 "Elco Motor Yachts" 1384 "Tecnoseal Foundry S.r.l" 1385 "Pro Charging Systems, LLC" 1389 "EVEX Co., LTD" 1398 "Gobius Sensor Technology AB" 1403 "Arco Marine" 1408 "Lenco Marine Inc." 1413 "Naocontrol S.L." 1417 "Revatek" 1438 "Aeolionics" 1439 "PredictWind Ltd" 1440 "Egis Mobile Electric" 1445 "Starboard Yacht Group" 1446 "Roswell Marine" 1451 "ePropulsion (Guangdong ePropulsion Technology Ltd.)" 1452 "Micro-Air LLC" 1453 "Vital Battery" 1458 "Ride Controller LLC" 1460 "Tocaro Blue" 1461 "Vanquish Yachts" 1471 "FT Technologies" 1478 "Alps Alpine Co., Ltd." 1481 "E-Force Marine" 1482 "CMC Marine" 1483 "Nanjing Sandemarine Information Technology Co., Ltd." 1850 "Teleflex Marine (SeaStar Solutions)" 1851 "Raymarine" 1852 "Navionics" 1853 "Japan Radio Co" 1854 "Northstar Technologies" 1855 "Furuno" 1856 "Trimble" 1857 "Simrad" 1858 "Litton" 1859 "Kvasar AB" 1860 "MMP" 1861 "Vector Cantech" 1862 "Yamaha Marine" 1863 "Faria Instruments" ;
VAL_ 2566865406 industryCode 0 "Global" 1 "Highway" 2 "Agriculture" 3 "Construction" 4 "Marine Industry" 5 "Industrial" ;
VAL_ 2566865406 manufacturerCode 69 "ARKS Enterprises, Inc." 78 "FW Murphy/Enovation Controls" 80 "Twin Disc" 85 "Kohler Power Systems" 88 "Hemisphere GPS Inc" 116 "BEP Marine" 135 "Airmar" 137 "Maretron" 140 "Lowrance" 144 "Mercury Marine" 147 "Nautibus Electronic GmbH" 148 "Blue Water Data" 154 "Westerbeke" 157 "ISSPRO Inc" 161 "Offshore Systems (UK) Ltd." 163 "Evinrude/BRP" 165 "CPAC Systems AB" 168 "Xantrex Technology Inc." 169 "Marlin Technologies, Inc." 172 "Yanmar Marine" 174 "Volvo Penta" 175 "Honda Marine" 176 "Carling Technologies Inc. (Moritz Aerospace)" 185 "Beede Instruments" 192 "Floscan Instrument Co. Inc." 193 "Nobletec" 198 "Mystic Valley Communications" 199 "Actia" 200 "Honda Marine 2" 201 "Disenos Y Technologia" 211 "Digital Switching Systems" 215 "Xintex/Atena" 224 "EMMI NETWORK S.L." 225 "Honda Marine 3" 228 "ZF" 229 "Garmin" 233 "Yacht Monitoring Solutions" 235 "Sailormade Marine Telemetry/Tetra Technology LTD" 243 "Eride" 250 "Honda Marine 4" 257 "Honda Motor Company LTD" 272 "Groco" 273 "Actisense" 274 "Amphenol LTW Technology" 275 "Navico" 283 "Hamilton Jet" 285 "Sea Recovery" 286 "Coelmo SRL Italy" 295 "BEP Marine 2" 304 "Empir Bus" 305 "NovAtel" 306 "Sleipner Motor AS" 307 "MBW Technologies" 311 "Fischer Panda" 315 "ICOM" 328 "Qwerty" 329 "Dief" 341 "Boening Automationstechnologie GmbH & Co. KG" 345 "Korean Maritime University" 351 "Thrane and Thrane" 355 "Mastervolt" 356 "Fischer Panda Generators" 358 "Victron Energy" 370 "Rolls Royce Marine" 373 "Electronic Design" 374 "Northern Lights" 378 "Glendinning" 381 "B & G" 384 "Rose Point Navigation Systems" 385 "Johnson Outdoors Marine Electronics Inc Geonav" 394 "Capi 2" 396 "Beyond Measure" 400 "Livorsi Marine" 404 "ComNav" 409 "Chetco" 419 "Fusion Electronics" 421 "Standard Horizon" 422 "True Heading AB" 426 "Egersund Marine Electronics AS" 427 "em-trak Marine Electronics" 431 "Tohatsu Co, JP" 437 "Digital Yacht" 438 "Comar Systems Limited" 440 "Cummins" 443 "VDO (aka Continental-Corporation)" 451 "Parker Hannifin aka Village Marine Tech" 459 "Alltek Marine Electronics Corp" 460 "SAN GIORGIO S.E.I.N" 466 "Veethree Electronics & Marine" 467 "Humminbird Marine Electronics" 470 "SI-TEX Marine Electronics" 471 "Sea Cross Marine AB" 475 "GME aka Standard Communications Pty LTD" 476 "Humminbird Marine Electronics 2" 478 "Ocean Sat BV" 481 "Chetco Digitial Instruments" 493 "Watcheye" 499 "Lcj Capteurs" 502 "Attwood Marine" 503 "Naviop S.R.L." 504 "Vesper Marine Ltd" 510 "Marinesoft Co. LTD" 513 "Simarine" 517 "NoLand Engineering" 518 "Transas USA" 529 "National Instruments Korea" 530 "National Marine Electronics Association" 532 "Onwa Marine" 540 "Webasto" 571 "Marinecraft (South Korea)" 573 "McMurdo Group aka Orolia LTD" 578 "Advansea" 579 "KVH" 580 "San Jose Technology" 583 "Yacht Control" 586 "Suzuki Motor Corporation" 591 "US Coast Guard" 595 "Ship Module aka Customware" 600 "Aquatic AV" 605 "Aventics GmbH" 606 "Intellian" 612 "SamwonIT" 614 "Arlt Tecnologies" 637 "Bavaria Yacts" 641 "Diverse Yacht Services" 644 "Wema U.S.A dba KUS" 645 "Garmin 2" 658 "Shenzhen Jiuzhou Himunication" 688 "Rockford Corp" 699 "Harman International" 704 "JL Audio" 708 "Lars Thrane" 715 "Autonnic" 717 "Yacht Devices" 734 "REAP Systems" 735 "Au Electronics Group" 739 "LxNav" 741 "Littelfuse, Inc (formerly Carling Technologies)" 743 "DaeMyung" 744 "Woosung" 748 "ISOTTA IFRA srl" 772 "Blink Marine" 773 "Clarion US" 776 "HMI Systems" 777 "Ocean Signal" 778 "Seekeeper" 781 "Poly Planar" 785 "Fischer Panda DE" 795 "Broyda Industries" 796 "Canadian Automotive" 797 "Tides Marine" 798 "Lumishore" 799 "Still Water Designs and Audio" 802 "BJ Technologies (Beneteau)" 803 "Gill Sensors" 811 "Blue Water Desalination" 815 "FLIR" 824 "Undheim Systems" 826 "Lewmar Inc" 838 "TeamSurv" 844 "Fell Marine" 847 "Oceanvolt" 862 "Prospec" 868 "Data Panel Corp" 890 "L3 Technologies" 894 "Rhodan Marine Systems" 896 "Nexfour Solutions" 905 "ASA Electronics" 909 "Marines Co (South Korea)" 911 "Nautic-on" 917 "Sentinel" 929 "JL Marine ystems" 930 "Ecotronix" 944 "Zontisa Marine" 951 "EXOR International" 962 "Timbolier Industries" 963 "TJC Micro" 968 "Cox Powertrain" 969 "Blue Seas" 981 "Kobelt Manufacturing Co. Ltd" 992 "Blue Ocean IOT" 997 "Xenta Systems" 999 "Signal K" 1004 "Ultraflex SpA" 1008 "Lintest SmartBoat" 1011 "Soundmax" 1020 "Team Italia Marine (Onyx Marine Automation s.r.l)" 1021 "Entratech" 1022 "ITC Inc." 1029 "The Marine Guardian LLC" 1047 "Sonic Corporation" 1051 "ProNav" 1053 "Vetus Maxwell INC." 1056 "Lithium Pros" 1059 "Boatrax" 1062 "Marol Co ltd" 1065 "CALYPSO Instruments" 1066 "Spot Zero Water" 1069 "Lithionics Battery LLC" 1070 "Quick-teck Electronics Ltd" 1075 "Uniden America" 1083 "Nauticoncept" 1084 "Shadow-Caster LED lighting LLC" 1085 "Wet Sounds, LLC" 1088 "E-T-A Circuit Breakers" 1092 "Scheiber" 1100 "Smart Yachts International Limited" 1109 "Dockmate" 1114 "Bobs Machine" 1118 "L3Harris ASV" 1119 "Balmar LLC" 1120 "Elettromedia spa" 1127 "Electromaax" 1140 "Across Oceans Systems Ltd." 1145 "Kiwi Yachting" 1150 "BSB Artificial Intelligence GmbH" 1151 "Orca Technologoes AS" 1154 "TBS Electronics BV" 1158 "Technoton Electroics" 1160 "MG Energy Systems B.V." 1169 "Sea Macine Robotics Inc." 1171 "Vista Manufacturing" 1183 "Zipwake" 1186 "Sailmon BV" 1192 "Airmoniq Pro Kft" 1194 "Sierra Marine" 1200 "Xinuo Information Technology (Xiamen)" 1218 "Septentrio" 1233 "NKE Marine Elecronics" 1238 "SuperTrack Aps" 1239 "Honda Electronics Co., LTD" 1245 "Raritan Engineering Company, Inc" 1249 "Integrated Power Solutions AG" 1260 "Interactive Technologies, Inc." 1283 "LTG-Tech" 1299 "Energy Solutions (UK) LTD." 1300 "WATT Fuel Cell Corp" 1302 "Pro Mainer" 1305 "Dragonfly Energy" 1306 "Koden Electronics Co., Ltd" 1311 "Humphree AB" 1316 "Hinkley Yachts" 1317 "Global Marine Management GmbH (GMM)" 1320 "Triskel Marine Ltd" 1330 "Warwick Control Technologies" 1331 "Dolphin Charger" 1337 "Barnacle Systems Inc" 1348 "Radian IoT, Inc." 1353 "Ocean LED Marine Ltd" 1359 "BluNav" 1361 "OVA (Nantong Saiyang Electronics Co., Ltd)" 1368 "RAD Propulsion" 1369 "Electric Yacht" 1372 "Elco Motor Yachts" 1384 "Tecnoseal Foundry S.r.l" 1385 "Pro Charging Systems, LLC" 1389 "EVEX Co., LTD" 1398 "Gobius Sensor Technology AB" 1403 "Arco Marine" 1408 "Lenco Marine Inc." 1413 "Naocontrol S.L." 1417 "Revatek" 1438 "Aeolionics" 1439 "PredictWind Ltd" 1440 "Egis Mobile Electric" 1445 "Starboard Yacht Group" 1446 "Roswell Marine" 1451 "ePropulsion (Guangdong ePropulsion Technology Ltd.)" 1452 "Micro-Air LLC" 1453 "Vital Battery" 1458 "Ride Controller LLC" 1460 "Tocaro Blue" 1461 "Vanquish Yachts" 1471 "FT Technologies" 1478 "Alps Alpine Co., Ltd." 1481 "E-Force Marine" 1482 "CMC Marine" 1483 "Nanjing Sandemarine Information Technology Co., Ltd." 1850 "Teleflex Marine (SeaStar Solutions)" 1851 "Raymarine" 1852 "Navionics" 1853 "Japan Radio Co" 1854 "Northstar Technologies" 1855 "Furuno" 1856 "Trimble" 1857 "Simrad" 1858 "Litton" 1859 "Kvasar AB" 1860 "MMP" 1861 "Vector Cantech" 1862 "Yamaha Marine" 1863 "Faria Instruments" ;
VAL_ 2566865662 industryCode 0 "Global" 1 "Highway" 2 "Agriculture" 3 "Construction" 4 "Marine Industry" 5 "Industrial" ;
VAL_ 2566865662 manufacturerCode 69 "ARKS Enterprises, Inc." 78 "FW Murphy/Enovation Controls" 80 "Twin Disc" 85 "Kohler Power Systems" 88 "Hemisphere GPS Inc" 116 "BEP Marine" 135 "Airmar" 137 "Maretron" 140 "Lowrance" 144 "Mercury Marine" 147 "Nautibus Electronic GmbH" 148 "Blue Water Data" 154 "Westerbeke" 157 "ISSPRO Inc" 161 "Offshore Systems (UK) Ltd." 163 "Evinrude/BRP" 165 "CPAC Systems AB" 168 "Xantrex Technology Inc." 169 "Marlin Technologies, Inc." 172 "Yanmar Marine" 174 "Volvo Penta" 175 "Honda Marine" 176 "Carling Technologies Inc. (Moritz Aerospace)" 185 "Beede Instruments" 192 "Floscan Instrument Co. Inc." 193 "Nobletec" 198 "Mystic Valley Communications" 199 "Actia" 200 "Honda Marine 2" 201 "Disenos Y Technologia" 211 "Digital Switching Systems" 215 "Xintex/Atena" 224 "EMMI NETWORK S.L." 225 "Honda Marine 3" 228 "ZF" 229 "Garmin" 233 "Yacht Monitoring Solutions" 235 "Sailormade Marine Telemetry/Tetra Technology LTD" 243 "Eride" 250 "Honda Marine 4" 257 "Honda Motor Company LTD" 272 "Groco" 273 "Actisense" 274 "Amphenol LTW Technology" 275 "Navico" 283 "Hamilton Jet" 285 "Sea Recovery" 286 "Coelmo SRL Italy" 295 "BEP Marine 2" 304 "Empir Bus" 305 "NovAtel" 306 "Sleipner Motor AS" 307 "MBW Technologies" 311 "Fischer Panda" 315 "ICOM" 328 "Qwerty" 329 "Dief" 341 "Boening Automationstechnologie GmbH & Co. KG" 345 "Korean Maritime University" 351 "Thrane and Thrane" 355 "Mastervolt" 356 "Fischer Panda Generators" 358 "Victron Energy" 370 "Rolls Royce Marine" 373 "Electronic Design" 374 "Northern Lights" 378 "Glendinning" 381 "B & G" 384 "Rose Point Navigation Systems" 385 "Johnson Outdoors Marine Electronics Inc Geonav" 394 "Capi 2" 396 "Beyond Measure" 400 "Livorsi Marine" 404 "ComNav" 409 "Chetco" 419 "Fusion Electronics" 421 "Standard Horizon" 422 "True Heading AB" 426 "Egersund Marine Electronics AS" 427 "em-trak Marine Electronics" 431 "Tohatsu Co, JP" 437 "Digital Yacht" 438 "Comar Systems Limited" 440 "Cummins" 443 "VDO (aka Continental-Corporation)" 451 "Parker Hannifin aka Village Marine Tech" 459 "Alltek Marine Electronics Corp" 460 "SAN GIORGIO S.E.I.N" 466 "Veethree Electronics & Marine" 467 "Humminbird Marine Electronics" 470 "SI-TEX Marine Electronics" 471 "Sea Cross Marine AB" 475 "GME aka Standard Communications Pty LTD" 476 "Humminbird Marine Electronics 2" 478 "Ocean Sat BV" 481 "Chetco Digitial Instruments" 493 "Watcheye" 499 "Lcj Capteurs" 502 "Attwood Marine" 503 "Naviop S.R.L." 504 "Vesper Marine Ltd" 510 "Marinesoft Co. LTD" 513 "Simarine" 517 "NoLand Engineering" 518 "Transas USA" 529 "National Instruments Korea" 530 "National Marine Electronics Association" 532 "Onwa Marine" 540 "Webasto" 571 "Marinecraft (South Korea)" 573 "McMurdo Group aka Orolia LTD" 578 "Advansea" 579 "KVH" 580 "San Jose Technology" 583 "Yacht Control" 586 "Suzuki Motor Corporation" 591 "US Coast Guard" 595 "Ship Module aka Customware" 600 "Aquatic AV" 605 "Aventics GmbH" 606 "Intellian" 612 "SamwonIT" 614 "Arlt Tecnologies" 637 "Bavaria Yacts" 641 "Diverse Yacht Services" 644 "Wema U.S.A dba KUS" 645 "Garmin 2" 658 "Shenzhen Jiuzhou Himunication" 688 "Rockford Corp" 699 "Harman International" 704 "JL Audio" 708 "Lars Thrane" 715 "Autonnic" 717 "Yacht Devices" 734 "REAP Systems" 735 "Au Electronics Group" 739 "LxNav" 741 "Littelfuse, Inc (formerly Carling Technologies)" 743 "DaeMyung" 744 "Woosung" 748 "ISOTTA IFRA srl" 772 "Blink Marine" 773 "Clarion US" 776 "HMI Systems" 777 "Ocean Signal" 778 "Seekeeper" 781 "Poly Planar" 785 "Fischer Panda DE" 795 "Broyda Industries" 796 "Canadian Automotive" 797 "Tides Marine" 798 "Lumishore" 799 "Still Water Designs and Audio" 802 "BJ Technologies (Beneteau)" 803 "Gill Sensors" 811 "Blue Water Desalination" 815 "FLIR" 824 "Undheim Systems" 826 "Lewmar Inc" 838 "TeamSurv" 844 "Fell Marine" 847 "Oceanvolt" 862 "Prospec" 868 "Data Panel Corp" 890 "L3 Technologies" 894 "Rhodan Marine Systems" 896 "Nexfour Solutions" 905 "ASA Electronics" 909 "Marines Co (South Korea)" 911 "Nautic-on" 917 "Sentinel" 929 "JL Marine ystems" 930 "Ecotronix" 944 "Zontisa Marine" 951 "EXOR International" 962 "Timbolier Industries" 963 "TJC Micro" 968 "Cox Powertrain" 969 "Blue Seas" 981 "Kobelt Manufacturing Co. Ltd" 992 "Blue Ocean IOT" 997 "Xenta Systems" 999 "Signal K" 1004 "Ultraflex SpA" 1008 "Lintest SmartBoat" 1011 "Soundmax" 1020 "Team Italia Marine (Onyx Marine Automation s.r.l)" 1021 "Entratech" 1022 "ITC Inc." 1029 "The Marine Guardian LLC" 1047 "Sonic Corporation" 1051 "ProNav" 1053 "Vetus Maxwell INC." 1056 "Lithium Pros" 1059 "Boatrax" 1062 "Marol Co ltd" 1065 "CALYPSO Instruments" 1066 "Spot Zero Water" 1069 "Lithionics Battery LLC" 1070 "Quick-teck Electronics Ltd" 1075 "Uniden America" 1083 "Nauticoncept" 1084 "Shadow-Caster LED lighting LLC" 1085 "Wet Sounds, LLC" 1088 "E-T-A Circuit Breakers" 1092 "Scheiber" 1100 "Smart Yachts International Limited" 1109 "Dockmate" 1114 "Bobs Machine" 1118 "L3Harris ASV" 1119 "Balmar LLC" 1120 "Elettromedia spa" 1127 "Electromaax" 1140 "Across Oceans Systems Ltd." 1145 "Kiwi Yachting" 1150 "BSB Artificial Intelligence GmbH" 1151 "Orca Technologoes AS" 1154 "TBS Electronics BV" 1158 "Technoton Electroics" 1160 "MG Energy Systems B.V." 1169 "Sea Macine Robotics Inc." 1171 "Vista Manufacturing" 1183 "Zipwake" 1186 "Sailmon BV" 1192 "Airmoniq Pro Kft" 1194 "Sierra Marine" 1200 "Xinuo Information Technology (Xiamen)" 1218 "Septentrio" 1233 "NKE Marine Elecronics" 1238 "SuperTrack Aps" 1239 "Honda Electronics Co., LTD" 1245 "Raritan Engineering Company, Inc" 1249 "Integrated Power Solutions AG" 1260 "Interactive Technologies, Inc." 1283 "LTG-Tech" 1299 "Energy Solutions (UK) LTD." 1300 "WATT Fuel Cell Corp" 1302 "Pro Mainer" 1305 "Dragonfly Energy" 1306 "Koden Electronics Co., Ltd" 1311 "Humphree AB" 1316 "Hinkley Yachts" 1317 "Global Marine Management GmbH (GMM)" 1320 "Triskel Marine Ltd" 1330 "Warwick Control Technologies" 1331 "Dolphin Charger" 1337 "Barnacle Systems Inc" 1348 "Radian IoT, Inc." 1353 "Ocean LED Marine Ltd" 1359 "BluNav" 1361 "OVA (Nantong Saiyang Electronics Co., Ltd)" 1368 "RAD Propulsion" 1369 "Electric Yacht" 1372 "Elco Motor Yachts" 1384 "Tecnoseal Foundry S.r.l" 1385 "Pro Charging Systems, LLC" 1389 "EVEX Co., LTD" 1398 "Gobius Sensor Technology AB" 1403 "Arco Marine" 1408 "Lenco Marine Inc." 1413 "Naocontrol S.L." 1417 "Revatek" 1438 "Aeolionics" 1439 "PredictWind Ltd" 1440 "Egis Mobile Electric" 1445 "Starboard Yacht Group" 1446 "Roswell Marine" 1451 "ePropulsion (Guangdong ePropulsion Technology Ltd.)" 1452 "Micro-Air LLC" 1453 "Vital Battery" 1458 "Ride Controller LLC" 1460 "Tocaro Blue" 1461 "Vanquish Yachts" 1471 "FT Technologies" 1478 "Alps Alpine Co., Ltd." 1481 "E-Force Marine" 1482 "CMC Marine" 1483 "Nanjing Sandemarine Information Technology Co., Ltd." 1850 "Teleflex Marine (SeaStar Solutions)" 1851 "Raymarine" 1852 "Navionics" 1853 "Japan Radio Co" 1854 "Northstar Technologies" 1855 "Furuno" 1856 "Trimble" 1857 "Simrad" 1858 "Litton" 1859 "Kvasar AB" 1860 "MMP" 1861 "Vector Cantech" 1862 "Yamaha Marine" 1863 "Faria Instruments" ;
VAL_ 2566866174 industryCode 0 "Global" 1 "Highway" 2 "Agriculture" 3 "Construction" 4 "Marine Industry" 5 "Industrial" ;
VAL_ 2566866174 manufacturerCode 69 "ARKS Enterprises, Inc." 78 "FW Murphy/Enovation Controls" 80 "Twin Disc" 85 "Kohler Power Systems" 88 "Hemisphere GPS Inc" 116 "BEP Marine" 135 "Airmar" 137 "Maretron" 140 "Lowrance" 144 "Mercury Marine" 147 "Nautibus Electronic GmbH" 148 "Blue Water Data" 154 "Westerbeke" 157 "ISSPRO Inc" 161 "Offshore Systems (UK) Ltd." 163 "Evinrude/BRP" 165 "CPAC Systems AB" 168 "Xantrex Technology Inc." 169 "Marlin Technologies, Inc." 172 "Yanmar Marine" 174 "Volvo Penta" 175 "Honda Marine" 176 "Carling Technologies Inc. (Moritz Aerospace)" 185 "Beede Instruments" 192 "Floscan Instrument Co. Inc." 193 "Nobletec" 198 "Mystic Valley Communications" 199 "Actia" 200 "Honda Marine 2" 201 "Disenos Y Technologia" 211 "Digital Switching Systems" 215 "Xintex/Atena" 224 "EMMI NETWORK S.L." 225 "Honda Marine 3" 228 "ZF" 229 "Garmin" 233 "Yacht Monitoring Solutions" 235 "Sailormade Marine Telemetry/Tetra Technology LTD" 243 "Eride" 250 "Honda Marine 4" 257 "Honda Motor Company LTD" 272 "Groco" 273 "Actisense" 274 "Amphenol LTW Technology" 275 "Navico" 283 "Hamilton Jet" 285 "Sea Recovery" 286 "Coelmo SRL Italy" 295 "BEP Marine 2" 304 "Empir Bus" 305 "NovAtel" 306 "Sleipner Motor AS" 307 "MBW Technologies" 311 "Fischer Panda" 315 "ICOM" 328 "Qwerty" 329 "Dief" 341 "Boening Automationstechnologie GmbH & Co. KG" 345 "Korean Maritime University" 351 "Thrane and Thrane" 355 "Mastervolt" 356 "Fischer Panda Generators" 358 "Victron Energy" 370 "Rolls Royce Marine" 373 "Electronic Design" 374 "Northern Lights" 378 "Glendinning" 381 "B & G" 384 "Rose Point Navigation Systems" 385 "Johnson Outdoors Marine Electronics Inc Geonav" 394 "Capi 2" 396 "Beyond Measure" 400 "Livorsi Marine" 404 "ComNav" 409 "Chetco" 419 "Fusion Electronics" 421 "Standard Horizon" 422 "True Heading AB" 426 "Egersund Marine Electronics AS" 427 "em-trak Marine Electronics" 431 "Tohatsu Co, JP" 437 "Digital Yacht" 438 "Comar Systems Limited" 440 "Cummins" 443 "VDO (aka Continental-Corporation)" 451 "Parker Hannifin aka Village Marine Tech" 459 "Alltek Marine Electronics Corp" 460 "SAN GIORGIO S.E.I.N" 466 "Veethree Electronics & Marine" 467 "Humminbird Marine Electronics" 470 "SI-TEX Marine Electronics" 471 "Sea Cross Marine AB" 475 "GME aka Standard Communications Pty LTD" 476 "Humminbird Marine Electronics 2" 478 "Ocean Sat BV" 481 "Chetco Digitial Instruments" 493 "Watcheye" 499 "Lcj Capteurs" 502 "Attwood Marine" 503 "Naviop S.R.L." 504 "Vesper Marine Ltd" 510 "Marinesoft Co. LTD" 513 "Simarine" 517 "NoLand Engineering" 518 "Transas USA" 529 "National Instruments Korea" 530 "National Marine Electronics Association" 532 "Onwa Marine" 540 "Webasto" 571 "Marinecraft (South Korea)" 573 "McMurdo Group aka Orolia LTD" 578 "Advansea" 579 "KVH" 580 "San Jose Technology" 583 "Yacht Control" 586 "Suzuki Motor Corporation" 591 "US Coast Guard" 595 "Ship Module aka Customware" 600 "Aquatic AV" 605 "Aventics GmbH" 606 "Intellian" 612 "SamwonIT" 614 "Arlt Tecnologies" 637 "Bavaria Yacts" 641 "Diverse Yacht Services" 644 "Wema U.S.A dba KUS" 645 "Garmin 2" 658 "Shenzhen Jiuzhou Himunication" 688 "Rockford Corp" 699 "Harman International" 704 "JL Audio" 708 "Lars Thrane" 715 "Autonnic" 717 "Yacht Devices" 734 "REAP Systems" 735 "Au Electronics Group" 739 "LxNav" 741 "Littelfuse, Inc (formerly Carling Technologies)" 743 "DaeMyung" 744 "Woosung" 748 "ISOTTA IFRA srl" 772 "Blink Marine" 773 "Clarion US" 776 "HMI Systems" 777 "Ocean Signal" 778 "Seekeeper" 781 "Poly Planar" 785 "Fischer Panda DE" 795 "Broyda Industries" 796 "Canadian Automotive" 797 "Tides Marine" 798 "Lumishore" 799 "Still Water Designs and Audio" 802 "BJ Technologies (Beneteau)" 803 "Gill Sensors" 811 "Blue Water Desalination" 815 "FLIR" 824 "Undheim Systems" 826 "Lewmar Inc" 838 "TeamSurv" 844 "Fell Marine" 847 "Oceanvolt" 862 "Prospec" 868 "Data Panel Corp" 890 "L3 Technologies" 894 "Rhodan Marine Systems" 896 "Nexfour Solutions" 905 "ASA Electronics" 909 "Marines Co (South Korea)" 911 "Nautic-on" 917 "Sentinel" 929 "JL Marine ystems" 930 "Ecotronix" 944 "Zontisa Marine" 951 "EXOR International" 962 "Timbolier Industries" 963 "TJC Micro" 968 "Cox Powertrain" 969 "Blue Seas" 981 "Kobelt Manufacturing Co. Ltd" 992 "Blue Ocean IOT" 997 "Xenta Systems" 999 "Signal K" 1004 "Ultraflex SpA" 1008 "Lintest SmartBoat" 1011 "Soundmax" 1020 "Team Italia Marine (Onyx Marine Automation s.r.l)" 1021 "Entratech" 1022 "ITC Inc." 1029 "The Marine Guardian LLC" 1047 "Sonic Corporation" 1051 "ProNav" 1053 "Vetus Maxwell INC." 1056 "Lithium Pros" 1059 "Boatrax" 1062 "Marol Co ltd" 1065 "CALYPSO Instruments" 1066 "Spot Zero Water" 1069 "Lithionics Battery LLC" 1070 "Quick-teck Electronics Ltd" 1075 "Uniden America" 1083 "Nauticoncept" 1084 "Shadow-Caster LED lighting LLC" 1085 "Wet Sounds, LLC" 1088 "E-T-A Circuit Breakers" 1092 "Scheiber" 1100 "Smart Yachts International Limited" 1109 "Dockmate" 1114 "Bobs Machine" 1118 "L3Harris ASV" 1119 "Balmar LLC" 1120 "Elettromedia spa" 1127 "Electromaax" 1140 "Across Oceans Systems Ltd." 1145 "Kiwi Yachting" 1150 "BSB Artificial Intelligence GmbH" 1151 "Orca Technologoes AS" 1154 "TBS Electronics BV" 1158 "Technoton Electroics" 1160 "MG Energy Systems B.V." 1169 "Sea Macine Robotics Inc." 1171 "Vista Manufacturing" 1183 "Zipwake" 1186 "Sailmon BV" 1192 "Airmoniq Pro Kft" 1194 "Sierra Marine" 1200 "Xinuo Information Technology (Xiamen)" 1218 "Septentrio" 1233 "NKE Marine Elecronics" 1238 "SuperTrack Aps" 1239 "Honda Electronics Co., LTD" 1245 "Raritan Engineering Company, Inc" 1249 "Integrated Power Solutions AG" 1260 "Interactive Technologies, Inc." 1283 "LTG-Tech" 1299 "Energy Solutions (UK) LTD." 1300 "WATT Fuel Cell Corp" 1302 "Pro Mainer" 1305 "Dragonfly Energy" 1306 "Koden Electronics Co., Ltd" 1311 "Humphree AB" 1316 "Hinkley Yachts" 1317 "Global Marine Management GmbH (GMM)" 1320 "Triskel Marine Ltd" 1330 "Warwick Control Technologies" 1331 "Dolphin Charger" 1337 "Barnacle Systems Inc" 1348 "Radian IoT, Inc." 1353 "Ocean LED Marine Ltd" 1359 "BluNav" 1361 "OVA (Nantong Saiyang Electronics Co., Ltd)" 1368 "RAD Propulsion" 1369 "Electric Yacht" 1372 "Elco Motor Yachts" 1384 "Tecnoseal Foundry S.r.l" 1385 "Pro Charging Systems, LLC" 1389 "EVEX Co., LTD" 1398 "Gobius Sensor Technology AB" 1403 "Arco Marine" 1408 "Lenco Marine Inc." 1413 "Naocontrol S.L." 1417 "Revatek" 1438 "Aeolionics" 1439 "PredictWind Ltd" 1440 "Egis Mobile Electric" 1445 "Starboard Yacht Group" 1446 "Roswell Marine" 1451 "ePropulsion (Guangdong ePropulsion Technology Ltd.)" 1452 "Micro-Air LLC" 1453 "Vital Battery" 1458 "Ride Controller LLC" 1460 "Tocaro Blue" 1461 "Vanquish Yachts" 1471 "FT Technologies" 1478 "Alps Alpine Co., Ltd." 1481 "E-Force Marine" 1482 "CMC Marine" 1483 "Nanjing Sandemarine Information Technology Co., Ltd." 1850 "Teleflex Marine (SeaStar Solutions)" 1851 "Raymarine" 1852 "Navionics" 1853 "Japan Radio Co" 1854 "Northstar Technologies" 1855 "Furuno" 1856 "Trimble" 1857 "Simrad" 1858 "Litton" 1859 "Kvasar AB" 1860 "MMP" 1861 "Vector Cantech" 1862 "Yamaha Marine" 1863 "Faria Instruments" ;
VAL_ 2566866430 industryCode 0 "Global" 1 "Highway" 2 "Agriculture" 3 "Construction" 4 "Marine Industry" 5 "Industrial" ;
VAL_ 2566866430 manufacturerCode 69 "ARKS Enterprises, Inc." 78 "FW Murphy/Enovation Controls" 80 "Twin Disc" 85 "Kohler Power Systems" 88 "Hemisphere GPS Inc" 116 "BEP Marine" 135 "Airmar" 137 "Maretron" 140 "Lowrance" 144 "Mercury Marine" 147 "Nautibus Electronic GmbH" 148 "Blue Water Data" 154 "Westerbeke" 157 "ISSPRO Inc" 161 "Offshore Systems (UK) Ltd." 163 "Evinrude/BRP" 165 "CPAC Systems AB" 168 "Xantrex Technology Inc." 169 "Marlin Technologies, Inc." 172 "Yanmar Marine" 174 "Volvo Penta" 175 "Honda Marine" 176 "Carling Technologies Inc. (Moritz Aerospace)" 185 "Beede Instruments" 192 "Floscan Instrument Co. Inc." 193 "Nobletec" 198 "Mystic Valley Communications" 199 "Actia" 200 "Honda Marine 2" 201 "Disenos Y Technologia" 211 "Digital Switching Systems" 215 "Xintex/Atena" 224 "EMMI NETWORK S.L." 225 "Honda Marine 3" 228 "ZF" 229 "Garmin" 233 "Yacht Monitoring Solutions" 235 "Sailormade Marine Telemetry/Tetra Technology LTD" 243 "Eride" 250 "Honda Marine 4" 257 "Honda Motor Company LTD" 272 "Groco" 273 "Actisense" 274 "Amphenol LTW Technology" 275 "Navico" 283 "Hamilton Jet" 285 "Sea Recovery" 286 "Coelmo SRL Italy" 295 "BEP Marine 2" 304 "Empir Bus" 305 "NovAtel" 306 "Sleipner Motor AS" 307 "MBW Technologies" 311 "Fischer Panda" 315 "ICOM" 328 "Qwerty" 329 "Dief" 341 "Boening Automationstechnologie GmbH & Co. KG" 345 "Korean Maritime University" 351 "Thrane and Thrane" 355 "Mastervolt" 356 "Fischer Panda Generators" 358 "Victron Energy" 370 "Rolls Royce Marine" 373 "Electronic Design" 374 "Northern Lights" 378 "Glendinning" 381 "B & G" 384 "Rose Point Navigation Systems" 385 "Johnson Outdoors Marine Electronics Inc Geonav" 394 "Capi 2" 396 "Beyond Measure" 400 "Livorsi Marine" 404 "ComNav" 409 "Chetco" 419 "Fusion Electronics" 421 "Standard Horizon" 422 "True Heading AB" 426 "Egersund Marine Electronics AS" 427 "em-trak Marine Electronics" 431 "Tohatsu Co, JP" 437 "Digital Yacht" 438 "Comar Systems Limited" 440 "Cummins" 443 "VDO (aka Continental-Corporation)" 451 "Parker Hannifin aka Village Marine Tech" 459 "Alltek Marine Electronics Corp" 460 "SAN GIORGIO S.E.I.N" 466 "Veethree Electronics & Marine" 467 "Humminbird Marine Electronics" 470 "SI-TEX Marine Electronics" 471 "Sea Cross Marine AB" 475 "GME aka Standard Communications Pty LTD" 476 "Humminbird Marine Electronics 2" 478 "Ocean Sat BV" 481 "Chetco Digitial Instruments" 493 "Watcheye" 499 "Lcj Capteurs" 502 "Attwood Marine" 503 "Naviop S.R.L." 504 "Vesper Marine Ltd" 510 "Marinesoft Co. LTD" 513 "Simarine" 517 "NoLand Engineering" 518 "Transas USA" 529 "National Instruments Korea" 530 "National Marine Electronics Association" 532 "Onwa Marine" 540 "Webasto" 571 "Marinecraft (South Korea)" 573 "McMurdo Group aka Orolia LTD" 578 "Advansea" 579 "KVH" 580 "San Jose Technology" 583 "Yacht Control" 586 "Suzuki Motor Corporation" 591 "US Coast Guard" 595 "Ship Module aka Customware" 600 "Aquatic AV" 605 "Aventics GmbH" 606 "Intellian" 612 "SamwonIT" 614 "Arlt Tecnologies" 637 "Bavaria Yacts" 641 "Diverse Yacht Services" 644 "Wema U.S.A dba KUS" 645 "Garmin 2" 658 "Shenzhen Jiuzhou Himunication" 688 "Rockford Corp" 699 "Harman International" 704 "JL Audio" 708 "Lars Thrane" 715 "Autonnic" 717 "Yacht Devices" 734 "REAP Systems" 735 "Au Electronics Group" 739 "LxNav" 741 "Littelfuse, Inc (formerly Carling Technologies)" 743 "DaeMyung" 744 "Woosung" 748 "ISOTTA IFRA srl" 772 "Blink Marine" 773 "Clarion US" 776 "HMI Systems" 777 "Ocean Signal" 778 "Seekeeper" 781 "Poly Planar" 785 "Fischer Panda DE" 795 "Broyda Industries" 796 "Canadian Automotive" 797 "Tides Marine" 798 "Lumishore" 799 "Still Water Designs and Audio" 802 "BJ Technologies (Beneteau)" 803 "Gill Sensors" 811 "Blue Water Desalination" 815 "FLIR" 824 "Undheim Systems" 826 "Lewmar Inc" 838 "TeamSurv" 844 "Fell Marine" 847 "Oceanvolt" 862 "Prospec" 868 "Data Panel Corp" 890 "L3 Technologies" 894 "Rhodan Marine Systems" 896 "Nexfour Solutions" 905 "ASA Electronics" 909 "Marines Co (South Korea)" 911 "Nautic-on" 917 "Sentinel" 929 "JL Marine ystems" 930 "Ecotronix" 944 "Zontisa Marine" 951 "EXOR International" 962 "Timbolier Industries" 963 "TJC Micro" 968 "Cox Powertrain" 969 "Blue Seas" 981 "Kobelt Manufacturing Co. Ltd" 992 "Blue Ocean IOT" 997 "Xenta Systems" 999 "Signal K" 1004 "Ultraflex SpA" 1008 "Lintest SmartBoat" 1011 "Soundmax" 1020 "Team Italia Marine (Onyx Marine Automation s.r.l)" 1021 "Entratech" 1022 "ITC Inc." 1029 "The Marine Guardian LLC" 1047 "Sonic Corporation" 1051 "ProNav" 1053 "Vetus Maxwell INC." 1056 "Lithium Pros" 1059 "Boatrax" 1062 "Marol Co ltd" 1065 "CALYPSO Instruments" 1066 "Spot Zero Water" 1069 "Lithionics Battery LLC" 1070 "Quick-teck Electronics Ltd" 1075 "Uniden America" 1083 "Nauticoncept" 1084 "Shadow-Caster LED lighting LLC" 1085 "Wet Sounds, LLC" 1088 "E-T-A Circuit Breakers" 1092 "Scheiber" 1100 "Smart Yachts International Limited" 1109 "Dockmate" 1114 "Bobs Machine" 1118 "L3Harris ASV" 1119 "Balmar LLC" 1120 "Elettromedia spa" 1127 "Electromaax" 1140 "Across Oceans Systems Ltd." 1145 "Kiwi Yachting" 1150 "BSB Artificial Intelligence GmbH" 1151 "Orca Technologoes AS" 1154 "TBS Electronics BV" 1158 "Technoton Electroics" 1160 "MG Energy Systems B.V." 1169 "Sea Macine Robotics Inc." 1171 "Vista Manufacturing" 1183 "Zipwake" 1186 "Sailmon BV" 1192 "Airmoniq Pro Kft" 1194 "Sierra Marine" 1200 "Xinuo Information Technology (Xiamen)" 1218 "Septentrio" 1233 "NKE Marine Elecronics" 1238 "SuperTrack Aps" 1239 "Honda Electronics Co., LTD" 1245 "Raritan Engineering Company, Inc" 1249 "Integrated Power Solutions AG" 1260 "Interactive Technologies, Inc." 1283 "LTG-Tech" 1299 "Energy Solutions (UK) LTD." 1300 "WATT Fuel Cell Corp" 1302 "Pro Mainer" 1305 "Dragonfly Energy" 1306 "Koden Electronics Co., Ltd" 1311 "Humphree AB" 1316 "Hinkley Yachts" 1317 "Global Marine Management GmbH (GMM)" 1320 "Triskel Marine Ltd" 1330 "Warwick Control Technologies" 1331 "Dolphin Charger" 1337 "Barnacle Systems Inc" 1348 "Radian IoT, Inc." 1353 "Ocean LED Marine Ltd" 1359 "BluNav" 1361 "OVA (Nantong Saiyang Electronics Co., Ltd)" 1368 "RAD Propulsion" 1369 "Electric Yacht" 1372 "Elco Motor Yachts" 1384 "Tecnoseal Foundry S.r.l" 1385 "Pro Charging Systems, LLC" 1389 "EVEX Co., LTD" 1398 "Gobius Sensor Technology AB" 1403 "Arco Marine" 1408 "Lenco Marine Inc." 1413 "Naocontrol S.L." 1417 "Revatek" 1438 "Aeolionics" 1439 "PredictWind Ltd" 1440 "Egis Mobile Electric" 1445 "Starboard Yacht Group" 1446 "Roswell Marine" 1451 "ePropulsion (Guangdong ePropulsion Technology Ltd.)" 1452 "Micro-Air LLC" 1453 "Vital Battery" 1458 "Ride Controller LLC" 1460 "Tocaro Blue" 1461 "Vanquish Yachts" 1471 "FT Technologies" 1478 "Alps Alpine Co., Ltd." 1481 "E-Force Marine" 1482 "CMC Marine" 1483 "Nanjing Sandemarine Information Technology Co., Ltd." 1850 "Teleflex Marine (SeaStar Solutions)" 1851 "Raymarine" 1852 "Navionics" 1853 "Japan Radio Co" 1854 "Northstar Technologies" 1855 "Furuno" 1856 "Trimble" 1857 "Simrad" 1858 "Litton" 1859 "Kvasar AB" 1860 "MMP" 1861 "Vector Cantech" 1862 "Yamaha Marine" 1863 "Faria Instruments" ;
VAL_ 2566868990 industryCode 0 "Global" 1 "Highway" 2 "Agriculture" 3 "Construction" 4 "Marine Industry" 5 "Industrial" ;
VAL_ 2566868990 manufacturerCode 69 "ARKS Enterprises, Inc." 78 "FW Murphy/Enovation Controls" 80 "Twin Disc" 85 "Kohler Power Systems" 88 "Hemisphere GPS Inc" 116 "BEP Marine" 135 "Airmar" 137 "Maretron" 140 "Lowrance" 144 "Mercury Marine" 147 "Nautibus Electronic GmbH" 148 "Blue Water Data" 154 "Westerbeke" 157 "ISSPRO Inc" 161 "Offshore Systems (UK) Ltd." 163 "Evinrude/BRP" 165 "CPAC Systems AB" 168 "Xantrex Technology Inc." 169 "Marlin Technologies, Inc." 172 "Yanmar Marine" 174 "Volvo Penta" 175 "Honda Marine" 176 "Carling Technologies Inc. (Moritz Aerospace)" 185 "Beede Instruments" 192 "Floscan Instrument Co. Inc." 193 "Nobletec" 198 "Mystic Valley Communications" 199 "Actia" 200 "Honda Marine 2" 201 "Disenos Y Technologia" 211 "Digital Switching Systems" 215 "Xintex/Atena" 224 "EMMI NETWORK S.L." 225 "Honda Marine 3" 228 "ZF" 229 "Garmin" 233 "Yacht Monitoring Solutions" 235 "Sailormade Marine Telemetry/Tetra Technology LTD" 243 "Eride" 250 "Honda Marine 4" 257 "Honda Motor Company LTD" 272 "Groco" 273 "Actisense" 274 "Amphenol LTW Technology" 275 "Navico" 283 "Hamilton Jet" 285 "Sea Recovery" 286 "Coelmo SRL Italy" 295 "BEP Marine 2" 304 "Empir Bus" 305 "NovAtel" 306 "Sleipner Motor AS" 307 "MBW Technologies" 311 "Fischer Panda" 315 "ICOM" 328 "Qwerty" 329 "Dief" 341 "Boening Automationstechnologie GmbH & Co. KG" 345 "Korean Maritime University" 351 "Thrane and Thrane" 355 "Mastervolt" 356 "Fischer Panda Generators" 358 "Victron Energy" 370 "Rolls Royce Marine" 373 "Electronic Design" 374 "Northern Lights" 378 "Glendinning" 381 "B & G" 384 "Rose Point Navigation Systems" 385 "Johnson Outdoors Marine Electronics Inc Geonav" 394 "Capi 2" 396 "Beyond Measure" 400 "Livorsi Marine" 404 "ComNav" 409 "Chetco" 419 "Fusion Electronics" 421 "Standard Horizon" 422 "True Heading AB" 426 "Egersund Marine Electronics AS" 427 "em-trak Marine Electronics" 431 "Tohatsu Co, JP" 437 "Digital Yacht" 438 "Comar Systems Limited" 440 "Cummins" 443 "VDO (aka Continental-Corporation)" 451 "Parker Hannifin aka Village Marine Tech" 459 "Alltek Marine Electronics Corp" 460 "SAN GIORGIO S.E.I.N" 466 "Veethree Electronics & Marine" 467 "Humminbird Marine Electronics" 470 "SI-TEX Marine Electronics" 471 "Sea Cross Marine AB" 475 "GME aka Standard Communications Pty LTD" 476 "Humminbird Marine Electronics 2" 478 "Ocean Sat BV" 481 "Chetco Digitial Instruments" 493 "Watcheye" 499 "Lcj Capteurs" 502 "Attwood Marine" 503 "Naviop S.R.L." 504 "Vesper Marine Ltd" 510 "Marinesoft Co. LTD" 513 "Simarine" 517 "NoLand Engineering" 518 "Transas USA" 529 "National Instruments Korea" 530 "National Marine Electronics Association" 532 "Onwa Marine" 540 "Webasto" 571 "Marinecraft (South Korea)" 573 "McMurdo Group aka Orolia LTD" 578 "Advansea" 579 "KVH" 580 "San Jose Technology" 583 "Yacht Control" 586 "Suzuki Motor Corporation" 591 "US Coast Guard" 595 "Ship Module aka Customware" 600 "Aquatic AV" 605 "Aventics GmbH" 606 "Intellian" 612 "SamwonIT" 614 "Arlt Tecnologies" 637 "Bavaria Yacts" 641 "Diverse Yacht Services" 644 "Wema U.S.A dba KUS" 645 "Garmin 2" 658 "Shenzhen Jiuzhou Himunication" 688 "Rockford Corp" 699 "Harman International" 704 "JL Audio" 708 "Lars Thrane" 715 "Autonnic" 717 "Yacht Devices" 734 "REAP Systems" 735 "Au Electronics Group" 739 "LxNav" 741 "Littelfuse, Inc (formerly Carling Technologies)" 743 "DaeMyung" 744 "Woosung" 748 "ISOTTA IFRA srl" 772 "Blink Marine" 773 "Clarion US" 776 "HMI Systems" 777 "Ocean Signal" 778 "Seekeeper" 781 "Poly Planar" 785 "Fischer Panda DE" 795 "Broyda Industries" 796 "Canadian Automotive" 797 "Tides Marine" 798 "Lumishore" 799 "Still Water Designs and Audio" 802 "BJ Technologies (Beneteau)" 803 "Gill Sensors" 811 "Blue Water Desalination" 815 "FLIR" 824 "Undheim Systems" 826 "Lewmar Inc" 838 "TeamSurv" 844 "Fell Marine" 847 "Oceanvolt" 862 "Prospec" 868 "Data Panel Corp" 890 "L3 Technologies" 894 "Rhodan Marine Systems" 896 "Nexfour Solutions" 905 "ASA Electronics" 909 "Marines Co (South Korea)" 911 "Nautic-on" 917 "Sentinel" 929 "JL Marine ystems" 930 "Ecotronix" 944 "Zontisa Marine" 951 "EXOR International" 962 "Timbolier Industries" 963 "TJC Micro" 968 "Cox Powertrain" 969 "Blue Seas" 981 "Kobelt Manufacturing Co. Ltd" 992 "Blue Ocean IOT" 997 "Xenta Systems" 999 "Signal K" 1004 "Ultraflex SpA" 1008 "Lintest SmartBoat" 1011 "Soundmax" 1020 "Team Italia Marine (Onyx Marine Automation s.r.l)" 1021 "Entratech" 1022 "ITC Inc." 1029 "The Marine Guardian LLC" 1047 "Sonic Corporation" 1051 "ProNav" 1053 "Vetus Maxwell INC." 1056 "Lithium Pros" 1059 "Boatrax" 1062 "Marol Co ltd" 1065 "CALYPSO Instruments" 1066 "Spot Zero Water" 1069 "Lithionics Battery LLC" 1070 "Quick-teck Electronics Ltd" 1075 "Uniden America" 1083 "Nauticoncept" 1084 "Shadow-Caster LED lighting LLC" 1085 "Wet Sounds, LLC" 1088 "E-T-A Circuit Breakers" 1092 "Scheiber" 1100 "Smart Yachts International Limited" 1109 "Dockmate" 1114 "Bobs Machine" 1118 "L3Harris ASV" 1119 "Balmar LLC" 1120 "Elettromedia spa" 1127 "Electromaax" 1140 "Across Oceans Systems Ltd." 1145 "Kiwi Yachting" 1150 "BSB Artificial Intelligence GmbH" 1151 "Orca Technologoes AS" 1154 "TBS Electronics BV" 1158 "Technoton Electroics" 1160 "MG Energy Systems B.V." 1169 "Sea Macine Robotics Inc." 1171 "Vista Manufacturing" 1183 "Zipwake" 1186 "Sailmon BV" 1192 "Airmoniq Pro Kft" 1194 "Sierra Marine" 1200 "Xinuo Information Technology (Xiamen)" 1218 "Septentrio" 1233 "NKE Marine Elecronics" 1238 "SuperTrack Aps" 1239 "Honda Electronics Co., LTD" 1245 "Raritan Engineering Company, Inc" 1249 "Integrated Power Solutions AG" 1260 "Interactive Technologies, Inc." 1283 "LTG-Tech" 1299 "Energy Solutions (UK) LTD." 1300 "WATT Fuel Cell Corp" 1302 "Pro Mainer" 1305 "Dragonfly Energy" 1306 "Koden Electronics Co., Ltd" 1311 "Humphree AB" 1316 "Hinkley Yachts" 1317 "Global Marine Management GmbH (GMM)" 1320 "Triskel Marine Ltd" 1330 "Warwick Control Technologies" 1331 "Dolphin Charger" 1337 "Barnacle Systems Inc" 1348 "Radian IoT, Inc." 1353 "Ocean LED Marine Ltd" 1359 "BluNav" 1361 "OVA (Nantong Saiyang Electronics Co., Ltd)" 1368 "RAD Propulsion" 1369 "Electric Yacht" 1372 "Elco Motor Yachts" 1384 "Tecnoseal Foundry S.r.l" 1385 "Pro Charging Systems, LLC" 1389 "EVEX Co., LTD" 1398 "Gobius Sensor Technology AB" 1403 "Arco Marine" 1408 "Lenco Marine Inc." 1413 "Naocontrol S.L." 1417 "Revatek" 1438 "Aeolionics" 1439 "PredictWind Ltd" 1440 "Egis Mobile Electric" 1445 "Starboard Yacht Group" 1446 "Roswell Marine" 1451 "ePropulsion (Guangdong ePropulsion Technology Ltd.)" 1452 "Micro-Air LLC" 1453 "Vital Battery" 1458 "Ride Controller LLC" 1460 "Tocaro Blue" 1461 "Vanquish Yachts" 1471 "FT Technologies" 1478 "Alps Alpine Co., Ltd." 1481 "E-Force Marine" 1482 "CMC Marine" 1483 "Nanjing Sandemarine Information Technology Co., Ltd." 1850 "Teleflex Marine (SeaStar Solutions)" 1851 "Raymarine" 1852 "Navionics" 1853 "Japan Radio Co" 1854 "Northstar Technologies" 1855 "Furuno" 1856 "Trimble" 1857 "Simrad" 1858 "Litton" 1859 "Kvasar AB" 1860 "MMP" 1861 "Vector Cantech" 1862 "Yamaha Marine" 1863 "Faria Instruments" ;
VAL_ 2566869246 industryCode 0 "Global" 1 "Highway" 2 "Agriculture" 3 "Construction" 4 "Marine Industry" 5 "Industrial" ;
VAL_ 2566869246 manufacturerCode 69 "ARKS Enterprises, Inc." 78 "FW Murphy/Enovation Controls" 80 "Twin Disc" 85 "Kohler Power Systems" 88 "Hemisphere GPS Inc" 116 "BEP Marine" 135 "Airmar" 137 "Maretron" 140 "Lowrance" 144 "Mercury Marine" 147 "Nautibus Electronic GmbH" 148 "Blue Water Data" 154 "Westerbeke" 157 "ISSPRO Inc" 161 "Offshore Systems (UK) Ltd." 163 "Evinrude/BRP" 165 "CPAC Systems AB" 168 "Xantrex Technology Inc." 169 "Marlin Technologies, Inc." 172 "Yanmar Marine" 174 "Volvo Penta" 175 "Honda Marine" 176 "Carling Technologies Inc. (Moritz Aerospace)" 185 "Beede Instruments" 192 "Floscan Instrument Co. Inc." 193 "Nobletec" 198 "Mystic Valley Communications" 199 "Actia" 200 "Honda Marine 2" 201 "Disenos Y Technologia" 211 "Digital Switching Systems" 215 "Xintex/Atena" 224 "EMMI NETWORK S.L." 225 "Honda Marine 3" 228 "ZF" 229 "Garmin" 233 "Yacht Monitoring Solutions" 235 "Sailormade Marine Telemetry/Tetra Technology LTD" 243 "Eride" 250 "Honda Marine 4" 257 "Honda Motor Company LTD" 272 "Groco" 273 "Actisense" 274 "Amphenol LTW Technology" 275 "Navico" 283 "Hamilton Jet" 285 "Sea Recovery" 286 "Coelmo SRL Italy" 295 "BEP Marine 2" 304 "Empir Bus" 305 "NovAtel" 306 "Sleipner Motor AS" 307 "MBW Technologies" 311 "Fischer Panda" 315 "ICOM" 328 "Qwerty" 329 "Dief" 341 "Boening Automationstechnologie GmbH & Co. KG" 345 "Korean Maritime University" 351 "Thrane and Thrane" 355 "Mastervolt" 356 "Fischer Panda Generators" 358 "Victron Energy" 370 "Rolls Royce Marine" 373 "Electronic Design" 374 "Northern Lights" 378 "Glendinning" 381 "B & G" 384 "Rose Point Navigation Systems" 385 "Johnson Outdoors Marine Electronics Inc Geonav" 394 "Capi 2" 396 "Beyond Measure" 400 "Livorsi Marine" 404 "ComNav" 409 "Chetco" 419 "Fusion Electronics" 421 "Standard Horizon" 422 "True Heading AB" 426 "Egersund Marine Electronics AS" 427 "em-trak Marine Electronics" 431 "Tohatsu Co, JP" 437 "Digital Yacht" 438 "Comar Systems Limited" 440 "Cummins" 443 "VDO (aka Continental-Corporation)" 451 "Parker Hannifin aka Village Marine Tech" 459 "Alltek Marine Electronics Corp" 460 "SAN GIORGIO S.E.I.N" 466 "Veethree Electronics & Marine" 467 "Humminbird Marine Electronics" 470 "SI-TEX Marine Electronics" 471 "Sea Cross Marine AB" 475 "GME aka Standard Communications Pty LTD" 476 "Humminbird Marine Electronics 2" 478 "Ocean Sat BV" 481 "Chetco Digitial Instruments" 493 "Watcheye" 499 "Lcj Capteurs" 502 "Attwood Marine" 503 "Naviop S.R.L." 504 "Vesper Marine Ltd" 510 "Marinesoft Co. LTD" 513 "Simarine" 517 "NoLand Engineering" 518 "Transas USA" 529 "National Instruments Korea" 530 "National Marine Electronics Association" 532 "Onwa Marine" 540 "Webasto" 571 "Marinecraft (South Korea)" 573 "McMurdo Group aka Orolia LTD" 578 "Advansea" 579 "KVH" 580 "San Jose Technology" 583 "Yacht Control" 586 "Suzuki Motor Corporation" 591 "US Coast Guard" 595 "Ship Module aka Customware" 600 "Aquatic AV" 605 "Aventics GmbH" 606 "Intellian" 612 "SamwonIT" 614 "Arlt Tecnologies" 637 "Bavaria Yacts" 641 "Diverse Yacht Services" 644 "Wema U.S.A dba KUS" 645 "Garmin 2" 658 "Shenzhen Jiuzhou Himunication" 688 "Rockford Corp" 699 "Harman International" 704 "JL Audio" 708 "Lars Thrane" 715 "Autonnic" 717 "Yacht Devices" 734 "REAP Systems" 735 "Au Electronics Group" 739 "LxNav" 741 "Littelfuse, Inc (formerly Carling Technologies)" 743 "DaeMyung" 744 "Woosung" 748 "ISOTTA IFRA srl" 772 "Blink Marine" 773 "Clarion US" 776 "HMI Systems" 777 "Ocean Signal" 778 "Seekeeper" 781 "Poly Planar" 785 "Fischer Panda DE" 795 "Broyda Industries" 796 "Canadian Automotive" 797 "Tides Marine" 798 "Lumishore" 799 "Still Water Designs and Audio" 802 "BJ Technologies (Beneteau)" 803 "Gill Sensors" 811 "Blue Water Desalination" 815 "FLIR" 824 "Undheim Systems" 826 "Lewmar Inc" 838 "TeamSurv" 844 "Fell Marine" 847 "Oceanvolt" 862 "Prospec" 868 "Data Panel Corp" 890 "L3 Technologies" 894 "Rhodan Marine Systems" 896 "Nexfour Solutions" 905 "ASA Electronics" 909 "Marines Co (South Korea)" 911 "Nautic-on" 917 "Sentinel" 929 "JL Marine ystems" 930 "Ecotronix" 944 "Zontisa Marine" 951 "EXOR International" 962 "Timbolier Industries" 963 "TJC Micro" 968 "Cox Powertrain" 969 "Blue Seas" 981 "Kobelt Manufacturing Co. Ltd" 992 "Blue Ocean IOT" 997 "Xenta Systems" 999 "Signal K" 1004 "Ultraflex SpA" 1008 "Lintest SmartBoat" 1011 "Soundmax" 1020 "Team Italia Marine (Onyx Marine Automation s.r.l)" 1021 "Entratech" 1022 "ITC Inc." 1029 "The Marine Guardian LLC" 1047 "Sonic Corporation" 1051 "ProNav" 1053 "Vetus Maxwell INC." 1056 "Lithium Pros" 1059 "Boatrax" 1062 "Marol Co ltd" 1065 "CALYPSO Instruments" 1066 "Spot Zero Water" 1069 "Lithionics Battery LLC" 1070 "Quick-teck Electronics Ltd" 1075 "Uniden America" 1083 "Nauticoncept" 1084 "Shadow-Caster LED lighting LLC" 1085 "Wet Sounds, LLC" 1088 "E-T-A Circuit Breakers" 1092 "Scheiber" 1100 "Smart Yachts International Limited" 1109 "Dockmate" 1114 "Bobs Machine" 1118 "L3Harris ASV" 1119 "Balmar LLC" 1120 "Elettromedia spa" 1127 "Electromaax" 1140 "Across Oceans Systems Ltd." 1145 "Kiwi Yachting" 1150 "BSB Artificial Intelligence GmbH" 1151 "Orca Technologoes AS" 1154 "TBS Electronics BV" 1158 "Technoton Electroics" 1160 "MG Energy Systems B.V." 1169 "Sea Macine Robotics Inc." 1171 "Vista Manufacturing" 1183 "Zipwake" 1186 "Sailmon BV" 1192 "Airmoniq Pro Kft" 1194 "Sierra Marine" 1200 "Xinuo Information Technology (Xiamen)" 1218 "Septentrio" 1233 "NKE Marine Elecronics" 1238 "SuperTrack Aps" 1239 "Honda Electronics Co., LTD" 1245 "Raritan Engineering Company, Inc" 1249 "Integrated Power Solutions AG" 1260 "Interactive Technologies, Inc." 1283 "LTG-Tech" 1299 "Energy Solutions (UK) LTD." 1300 "WATT Fuel Cell Corp" 1302 "Pro Mainer" 1305 "Dragonfly Energy" 1306 "Koden Electronics Co., Ltd" 1311 "Humphree AB" 1316 "Hinkley Yachts" 1317 "Global Marine Management GmbH (GMM)" 1320 "Triskel Marine Ltd" 1330 "Warwick Control Technologies" 1331 "Dolphin Charger" 1337 "Barnacle Systems Inc" 1348 "Radian IoT, Inc." 1353 "Ocean LED Marine Ltd" 1359 "BluNav" 1361 "OVA (Nantong Saiyang Electronics Co., Ltd)" 1368 "RAD Propulsion" 1369 "Electric Yacht" 1372 "Elco Motor Yachts" 1384 "Tecnoseal Foundry S.r.l" 1385 "Pro Charging Systems, LLC" 1389 "EVEX Co., LTD" 1398 "Gobius Sensor Technology AB" 1403 "Arco Marine" 1408 "Lenco Marine Inc." 1413 "Naocontrol S.L." 1417 "Revatek" 1438 "Aeolionics" 1439 "PredictWind Ltd" 1440 "Egis Mobile Electric" 1445 "Starboard Yacht Group" 1446 "Roswell Marine" 1451 "ePropulsion (Guangdong ePropulsion Technology Ltd.)" 1452 "Micro-Air LLC" 1453 "Vital Battery" 1458 "Ride Controller LLC" 1460 "Tocaro Blue" 1461 "Vanquish Yachts" 1471 "FT Technologies" 1478 "Alps Alpine Co., Ltd." 1481 "E-Force Marine" 1482 "CMC Marine" 1483 "Nanjing Sandemarine Information Technology Co., Ltd." 1850 "Teleflex Marine (SeaStar Solutions)" 1851 "Raymarine" 1852 "Navionics" 1853 "Japan Radio Co" 1854 "Northstar Technologies" 1855 "Furuno" 1856 "Trimble" 1857 "Simrad" 1858 "Litton" 1859 "Kvasar AB" 1860 "MMP" 1861 "Vector Cantech" 1862 "Yamaha Marine" 1863 "Faria Instruments" ;
VAL_ 2566869502 alarmGroup 0 "Instrument" 1 "Autopilot" 2 "Radar" 3 "Chart Plotter" 4 "AIS" 5 "Bluetooth Accessory" ;
VAL_ 2566869502 alarmId 0 "No Alarm" 1 "Shallow Depth" 2 "Deep Depth" 3 "Shallow Anchor" 4 "Deep Anchor" 5 "Off Course" 6 "AWA High" 7 "AWA Low" 8 "AWS High" 9 "AWS Low" 10 "TWA High" 11 "TWA Low" 12 "TWS High" 13 "TWS Low" 14 "WP Arrival" 15 "Boat Speed High" 16 "Boat Speed Low" 17 "Sea Temperature High" 18 "Sea Temperature Low" 19 "Pilot Watch" 20 "Pilot Off Course" 21 "Pilot Wind Shift" 22 "Pilot Low Battery" 23 "Pilot Last Minute Of Watch" 24 "Pilot No NMEA Data" 25 "Pilot Large XTE" 26 "Pilot NMEA DataError" 27 "Pilot CU Disconnected" 28 "Pilot Auto Release" 29 "Pilot Way Point Advance" 30 "Pilot Drive Stopped" 31 "Pilot Type Unspecified" 32 "Pilot Calibration Required" 33 "Pilot Last Heading" 34 "Pilot No Pilot" 35 "Pilot Route Complete" 36 "Pilot Variable Text" 37 "GPS Failure" 38 "MOB" 39 "Seatalk1 Anchor" 40 "Pilot Swapped Motor Power" 41 "Pilot Standby Too Fast To Fish" 42 "Pilot No GPS Fix" 43 "Pilot No GPS COG" 44 "Pilot Start Up" 45 "Pilot Too Slow" 46 "Pilot No Compass" 47 "Pilot Rate Gyro Fault" 48 "Pilot Current Limit" 49 "Pilot Way Point Advance Port" 50 "Pilot Way Point Advance Stbd" 51 "Pilot No Wind Data" 52 "Pilot No Speed Data" 53 "Pilot Seatalk Fail1" 54 "Pilot Seatalk Fail2" 55 "Pilot Warning Too Fast To Fish" 56 "Pilot Auto Dockside Fail" 57 "Pilot Turn Too Fast" 58 "Pilot No Nav Data" 59 "Pilot Lost Waypoint Data" 60 "Pilot EEPROM Corrupt" 61 "Pilot Rudder Feedback Fail" 62 "Pilot Autolearn Fail1" 63 "Pilot Autolearn Fail2" 64 "Pilot Autolearn Fail3" 65 "Pilot Autolearn Fail4" 66 "Pilot Autolearn Fail5" 67 "Pilot Autolearn Fail6" 68 "Pilot Warning Cal Required" 69 "Pilot Warning OffCourse" 70 "Pilot Warning XTE" 71 "Pilot Warning Wind Shift" 72 "Pilot Warning Drive Short" 73 "Pilot Warning Clutch Short" 74 "Pilot Warning Solenoid Short" 75 "Pilot Joystick Fault" 76 "Pilot No Joystick Data" 80 "Pilot Invalid Command" 81 "AIS TX Malfunction" 82 "AIS Antenna VSWR fault" 83 "AIS Rx channel 1 malfunction" 84 "AIS Rx channel 2 malfunction" 85 "AIS No sensor position in use" 86 "AIS No valid SOG information" 87 "AIS No valid COG information" 88 "AIS 12V alarm" 89 "AIS 6V alarm" 90 "AIS Noise threshold exceeded channel A" 91 "AIS Noise threshold exceeded channel B" 92 "AIS Transmitter PA fault" 93 "AIS 3V3 alarm" 94 "AIS Rx channel 70 malfunction" 95 "AIS Heading lost/invalid" 96 "AIS internal GPS lost" 97 "AIS No sensor position" 98 "AIS Lock failure" 99 "AIS Internal GGA timeout" 100 "AIS Protocol stack restart" 101 "Pilot No IPS communications" 102 "Pilot Power-On or Sleep-Switch Reset While Engaged" 103 "Pilot Unexpected Reset While Engaged" 104 "AIS Dangerous Target" 105 "AIS Lost Target" 106 "AIS Safety Related Message (used to silence)" 107 "AIS Connection Lost" 108 "No Fix" 112 "Pilot Compass Calibration Complete" 113 "AIS Transmitter Disabled - MMSI Required" 122 "Bluetooth Device Low Battery" 123 "Bluetooth Device Sleep Mode" 124 "Bluetooth Device High Battery Temperature" 125 "Bluetooth Device Lost Communications" ;
VAL_ 2566869502 industryCode 0 "Global" 1 "Highway" 2 "Agriculture" 3 "Construction" 4 "Marine Industry" 5 "Industrial" ;
VAL_ 2566869502 manufacturerCode 69 "ARKS Enterprises, Inc." 78 "FW Murphy/Enovation Controls" 80 "Twin Disc" 85 "Kohler Power Systems" 88 "Hemisphere GPS Inc" 116 "BEP Marine" 135 "Airmar" 137 "Maretron" 140 "Lowrance" 144 "Mercury Marine" 147 "Nautibus Electronic GmbH" 148 "Blue Water Data" 154 "Westerbeke" 157 "ISSPRO Inc" 161 "Offshore Systems (UK) Ltd." 163 "Evinrude/BRP" 165 "CPAC Systems AB" 168 "Xantrex Technology Inc." 169 "Marlin Technologies, Inc." 172 "Yanmar Marine" 174 "Volvo Penta" 175 "Honda Marine" 176 "Carling Technologies Inc. (Moritz Aerospace)" 185 "Beede Instruments" 192 "Floscan Instrument Co. Inc." 193 "Nobletec" 198 "Mystic Valley Communications" 199 "Actia" 200 "Honda Marine 2" 201 "Disenos Y Technologia" 211 "Digital Switching Systems" 215 "Xintex/Atena" 224 "EMMI NETWORK S.L." 225 "Honda Marine 3" 228 "ZF" 229 "Garmin" 233 "Yacht Monitoring Solutions" 235 "Sailormade Marine Telemetry/Tetra Technology LTD" 243 "Eride" 250 "Honda Marine 4" 257 "Honda Motor Company LTD" 272 "Groco" 273 "Actisense" 274 "Amphenol LTW Technology" 275 "Navico" 283 "Hamilton Jet" 285 "Sea Recovery" 286 "Coelmo SRL Italy" 295 "BEP Marine 2" 304 "Empir Bus" 305 "NovAtel" 306 "Sleipner Motor AS" 307 "MBW Technologies" 311 "Fischer Panda" 315 "ICOM" 328 "Qwerty" 329 "Dief" 341 "Boening Automationstechnologie GmbH & Co. KG" 345 "Korean Maritime University" 351 "Thrane and Thrane" 355 "Mastervolt" 356 "Fischer Panda Generators" 358 "Victron Energy" 370 "Rolls Royce Marine" 373 "Electronic Design" 374 "Northern Lights" 378 "Glendinning" 381 "B & G" 384 "Rose Point Navigation Systems" 385 "Johnson Outdoors Marine Electronics Inc Geonav" 394 "Capi 2" 396 "Beyond Measure" 400 "Livorsi Marine" 404 "ComNav" 409 "Chetco" 419 "Fusion Electronics" 421 "Standard Horizon" 422 "True Heading AB" 426 "Egersund Marine Electronics AS" 427 "em-trak Marine Electronics" 431 "Tohatsu Co, JP" 437 "Digital Yacht" 438 "Comar Systems Limited" 440 "Cummins" 443 "VDO (aka Continental-Corporation)" 451 "Parker Hannifin aka Village Marine Tech" 459 "Alltek Marine Electronics Corp" 460 "SAN GIORGIO S.E.I.N" 466 "Veethree Electronics & Marine" 467 "Humminbird Marine Electronics" 470 "SI-TEX Marine Electronics" 471 "Sea Cross Marine AB" 475 "GME aka Standard Communications Pty LTD" 476 "Humminbird Marine Electronics 2" 478 "Ocean Sat BV" 481 "Chetco Digitial Instruments" 493 "Watcheye" 499 "Lcj Capteurs" 502 "Attwood Marine" 503 "Naviop S.R.L." 504 "Vesper Marine Ltd" 510 "Marinesoft Co. LTD" 513 "Simarine" 517 "NoLand Engineering" 518 "Transas USA" 529 "National Instruments Korea" 530 "National Marine Electronics Association" 532 "Onwa Marine" 540 "Webasto" 571 "Marinecraft (South Korea)" 573 "McMurdo Group aka Orolia LTD" 578 "Advansea" 579 "KVH" 580 "San Jose Technology" 583 "Yacht Control" 586 "Suzuki Motor Corporation" 591 "US Coast Guard" 595 "Ship Module aka Customware" 600 "Aquatic AV" 605 "Aventics GmbH" 606 "Intellian" 612 "SamwonIT" 614 "Arlt Tecnologies" 637 "Bavaria Yacts" 641 "Diverse Yacht Services" 644 "Wema U.S.A dba KUS" 645 "Garmin 2" 658 "Shenzhen Jiuzhou Himunication" 688 "Rockford Corp" 699 "Harman International" 704 "JL Audio" 708 "Lars Thrane" 715 "Autonnic" 717 "Yacht Devices" 734 "REAP Systems" 735 "Au Electronics Group" 739 "LxNav" 741 "Littelfuse, Inc (formerly Carling Technologies)" 743 "DaeMyung" 744 "Woosung" 748 "ISOTTA IFRA srl" 772 "Blink Marine" 773 "Clarion US" 776 "HMI Systems" 777 "Ocean Signal" 778 "Seekeeper" 781 "Poly Planar" 785 "Fischer Panda DE" 795 "Broyda Industries" 796 "Canadian Automotive" 797 "Tides Marine" 798 "Lumishore" 799 "Still Water Designs and Audio" 802 "BJ Technologies (Beneteau)" 803 "Gill Sensors" 811 "Blue Water Desalination" 815 "FLIR" 824 "Undheim Systems" 826 "Lewmar Inc" 838 "TeamSurv" 844 "Fell Marine" 847 "Oceanvolt" 862 "Prospec" 868 "Data Panel Corp" 890 "L3 Technologies" 894 "Rhodan Marine Systems" 896 "Nexfour Solutions" 905 "ASA Electronics" 909 "Marines Co (South Korea)" 911 "Nautic-on" 917 "Sentinel" 929 "JL Marine ystems" 930 "Ecotronix" 944 "Zontisa Marine" 951 "EXOR International" 962 "Timbolier Industries" 963 "TJC Micro" 968 "Cox Powertrain" 969 "Blue Seas" 981 "Kobelt Manufacturing Co. Ltd" 992 "Blue Ocean IOT" 997 "Xenta Systems" 999 "Signal K" 1004 "Ultraflex SpA" 1008 "Lintest SmartBoat" 1011 "Soundmax" 1020 "Team Italia Marine (Onyx Marine Automation s.r.l)" 1021 "Entratech" 1022 "ITC Inc." 1029 "The Marine Guardian LLC" 1047 "Sonic Corporation" 1051 "ProNav" 1053 "Vetus Maxwell INC." 1056 "Lithium Pros" 1059 "Boatrax" 1062 "Marol Co ltd" 1065 "CALYPSO Instruments" 1066 "Spot Zero Water" 1069 "Lithionics Battery LLC" 1070 "Quick-teck Electronics Ltd" 1075 "Uniden America" 1083 "Nauticoncept" 1084 "Shadow-Caster LED lighting LLC" 1085 "Wet Sounds, LLC" 1088 "E-T-A Circuit Breakers" 1092 "Scheiber" 1100 "Smart Yachts International Limited" 1109 "Dockmate" 1114 "Bobs Machine" 1118 "L3Harris ASV" 1119 "Balmar LLC" 1120 "Elettromedia spa" 1127 "Electromaax" 1140 "Across Oceans Systems Ltd." 1145 "Kiwi Yachting" 1150 "BSB Artificial Intelligence GmbH" 1151 "Orca Technologoes AS" 1154 "TBS Electronics BV" 1158 "Technoton Electroics" 1160 "MG Energy Systems B.V." 1169 "Sea Macine Robotics Inc." 1171 "Vista Manufacturing" 1183 "Zipwake" 1186 "Sailmon BV" 1192 "Airmoniq Pro Kft" 1194 "Sierra Marine" 1200 "Xinuo Information Technology (Xiamen)" 1218 "Septentrio" 1233 "NKE Marine Elecronics" 1238 "SuperTrack Aps" 1239 "Honda Electronics Co., LTD" 1245 "Raritan Engineering Company, Inc" 1249 "Integrated Power Solutions AG" 1260 "Interactive Technologies, Inc." 1283 "LTG-Tech" 1299 "Energy Solutions (UK) LTD." 1300 "WATT Fuel Cell Corp" 1302 "Pro Mainer" 1305 "Dragonfly Energy" 1306 "Koden Electronics Co., Ltd" 1311 "Humphree AB" 1316 "Hinkley Yachts" 1317 "Global Marine Management GmbH (GMM)" 1320 "Triskel Marine Ltd" 1330 "Warwick Control Technologies" 1331 "Dolphin Charger" 1337 "Barnacle Systems Inc" 1348 "Radian IoT, Inc." 1353 "Ocean LED Marine Ltd" 1359 "BluNav" 1361 "OVA (Nantong Saiyang Electronics Co., Ltd)" 1368 "RAD Propulsion" 1369 "Electric Yacht" 1372 "Elco Motor Yachts" 1384 "Tecnoseal Foundry S.r.l" 1385 "Pro Charging Systems, LLC" 1389 "EVEX Co., LTD" 1398 "Gobius Sensor Technology AB" 1403 "Arco Marine" 1408 "Lenco Marine Inc." 1413 "Naocontrol S.L." 1417 "Revatek" 1438 "Aeolionics" 1439 "PredictWind Ltd" 1440 "Egis Mobile Electric" 1445 "Starboard Yacht Group" 1446 "Roswell Marine" 1451 "ePropulsion (Guangdong ePropulsion Technology Ltd.)" 1452 "Micro-Air LLC" 1453 "Vital Battery" 1458 "Ride Controller LLC" 1460 "Tocaro Blue" 1461 "Vanquish Yachts" 1471 "FT Technologies" 1478 "Alps Alpine Co., Ltd." 1481 "E-Force Marine" 1482 "CMC Marine" 1483 "Nanjing Sandemarine Information Technology Co., Ltd." 1850 "Teleflex Marine (SeaStar Solutions)" 1851 "Raymarine" 1852 "Navionics" 1853 "Japan Radio Co" 1854 "Northstar Technologies" 1855 "Furuno" 1856 "Trimble" 1857 "Simrad" 1858 "Litton" 1859 "Kvasar AB" 1860 "MMP" 1861 "Vector Cantech" 1862 "Yamaha Marine" 1863 "Faria Instruments" ;
VAL_ 2566872062 industryCode 0 "Global" 1 "Highway" 2 "Agriculture" 3 "Construction" 4 "Marine Industry" 5 "Industrial" ;
VAL_ 2566872062 manufacturerCode 69 "ARKS Enterprises, Inc." 78 "FW Murphy/Enovation Controls" 80 "Twin Disc" 85 "Kohler Power Systems" 88 "Hemisphere GPS Inc" 116 "BEP Marine" 135 "Airmar" 137 "Maretron" 140 "Lowrance" 144 "Mercury Marine" 147 "Nautibus Electronic GmbH" 148 "Blue Water Data" 154 "Westerbeke" 157 "ISSPRO Inc" 161 "Offshore Systems (UK) Ltd." 163 "Evinrude/BRP" 165 "CPAC Systems AB" 168 "Xantrex Technology Inc." 169 "Marlin Technologies, Inc." 172 "Yanmar Marine" 174 "Volvo Penta" 175 "Honda Marine" 176 "Carling Technologies Inc. (Moritz Aerospace)" 185 "Beede Instruments" 192 "Floscan Instrument Co. Inc." 193 "Nobletec" 198 "Mystic Valley Communications" 199 "Actia" 200 "Honda Marine 2" 201 "Disenos Y Technologia" 211 "Digital Switching Systems" 215 "Xintex/Atena" 224 "EMMI NETWORK S.L." 225 "Honda Marine 3" 228 "ZF" 229 "Garmin" 233 "Yacht Monitoring Solutions" 235 "Sailormade Marine Telemetry/Tetra Technology LTD" 243 "Eride" 250 "Honda Marine 4" 257 "Honda Motor Company LTD" 272 "Groco" 273 "Actisense" 274 "Amphenol LTW Technology" 275 "Navico" 283 "Hamilton Jet" 285 "Sea Recovery" 286 "Coelmo SRL Italy" 295 "BEP Marine 2" 304 "Empir Bus" 305 "NovAtel" 306 "Sleipner Motor AS" 307 "MBW Technologies" 311 "Fischer Panda" 315 "ICOM" 328 "Qwerty" 329 "Dief" 341 "Boening Automationstechnologie GmbH & Co. KG" 345 "Korean Maritime University" 351 "Thrane and Thrane" 355 "Mastervolt" 356 "Fischer Panda Generators" 358 "Victron Energy" 370 "Rolls Royce Marine" 373 "Electronic Design" 374 "Northern Lights" 378 "Glendinning" 381 "B & G" 384 "Rose Point Navigation Systems" 385 "Johnson Outdoors Marine Electronics Inc Geonav" 394 "Capi 2" 396 "Beyond Measure" 400 "Livorsi Marine" 404 "ComNav" 409 "Chetco" 419 "Fusion Electronics" 421 "Standard Horizon" 422 "True Heading AB" 426 "Egersund Marine Electronics AS" 427 "em-trak Marine Electronics" 431 "Tohatsu Co, JP" 437 "Digital Yacht" 438 "Comar Systems Limited" 440 "Cummins" 443 "VDO (aka Continental-Corporation)" 451 "Parker Hannifin aka Village Marine Tech" 459 "Alltek Marine Electronics Corp" 460 "SAN GIORGIO S.E.I.N" 466 "Veethree Electronics & Marine" 467 "Humminbird Marine Electronics" 470 "SI-TEX Marine Electronics" 471 "Sea Cross Marine AB" 475 "GME aka Standard Communications Pty LTD" 476 "Humminbird Marine Electronics 2" 478 "Ocean Sat BV" 481 "Chetco Digitial Instruments" 493 "Watcheye" 499 "Lcj Capteurs" 502 "Attwood Marine" 503 "Naviop S.R.L." 504 "Vesper Marine Ltd" 510 "Marinesoft Co. LTD" 513 "Simarine" 517 "NoLand Engineering" 518 "Transas USA" 529 "National Instruments Korea" 530 "National Marine Electronics Association" 532 "Onwa Marine" 540 "Webasto" 571 "Marinecraft (South Korea)" 573 "McMurdo Group aka Orolia LTD" 578 "Advansea" 579 "KVH" 580 "San Jose Technology" 583 "Yacht Control" 586 "Suzuki Motor Corporation" 591 "US Coast Guard" 595 "Ship Module aka Customware" 600 "Aquatic AV" 605 "Aventics GmbH" 606 "Intellian" 612 "SamwonIT" 614 "Arlt Tecnologies" 637 "Bavaria Yacts" 641 "Diverse Yacht Services" 644 "Wema U.S.A dba KUS" 645 "Garmin 2" 658 "Shenzhen Jiuzhou Himunication" 688 "Rockford Corp" 699 "Harman International" 704 "JL Audio" 708 "Lars Thrane" 715 "Autonnic" 717 "Yacht Devices" 734 "REAP Systems" 735 "Au Electronics Group" 739 "LxNav" 741 "Littelfuse, Inc (formerly Carling Technologies)" 743 "DaeMyung" 744 "Woosung" 748 "ISOTTA IFRA srl" 772 "Blink Marine" 773 "Clarion US" 776 "HMI Systems" 777 "Ocean Signal" 778 "Seekeeper" 781 "Poly Planar" 785 "Fischer Panda DE" 795 "Broyda Industries" 796 "Canadian Automotive" 797 "Tides Marine" 798 "Lumishore" 799 "Still Water Designs and Audio" 802 "BJ Technologies (Beneteau)" 803 "Gill Sensors" 811 "Blue Water Desalination" 815 "FLIR" 824 "Undheim Systems" 826 "Lewmar Inc" 838 "TeamSurv" 844 "Fell Marine" 847 "Oceanvolt" 862 "Prospec" 868 "Data Panel Corp" 890 "L3 Technologies" 894 "Rhodan Marine Systems" 896 "Nexfour Solutions" 905 "ASA Electronics" 909 "Marines Co (South Korea)" 911 "Nautic-on" 917 "Sentinel" 929 "JL Marine ystems" 930 "Ecotronix" 944 "Zontisa Marine" 951 "EXOR International" 962 "Timbolier Industries" 963 "TJC Micro" 968 "Cox Powertrain" 969 "Blue Seas" 981 "Kobelt Manufacturing Co. Ltd" 992 "Blue Ocean IOT" 997 "Xenta Systems" 999 "Signal K" 1004 "Ultraflex SpA" 1008 "Lintest SmartBoat" 1011 "Soundmax" 1020 "Team Italia Marine (Onyx Marine Automation s.r.l)" 1021 "Entratech" 1022 "ITC Inc." 1029 "The Marine Guardian LLC" 1047 "Sonic Corporation" 1051 "ProNav" 1053 "Vetus Maxwell INC." 1056 "Lithium Pros" 1059 "Boatrax" 1062 "Marol Co ltd" 1065 "CALYPSO Instruments" 1066 "Spot Zero Water" 1069 "Lithionics Battery LLC" 1070 "Quick-teck Electronics Ltd" 1075 "Uniden America" 1083 "Nauticoncept" 1084 "Shadow-Caster LED lighting LLC" 1085 "Wet Sounds, LLC" 1088 "E-T-A Circuit Breakers" 1092 "Scheiber" 1100 "Smart Yachts International Limited" 1109 "Dockmate" 1114 "Bobs Machine" 1118 "L3Harris ASV" 1119 "Balmar LLC" 1120 "Elettromedia spa" 1127 "Electromaax" 1140 "Across Oceans Systems Ltd." 1145 "Kiwi Yachting" 1150 "BSB Artificial Intelligence GmbH" 1151 "Orca Technologoes AS" 1154 "TBS Electronics BV" 1158 "Technoton Electroics" 1160 "MG Energy Systems B.V." 1169 "Sea Macine Robotics Inc." 1171 "Vista Manufacturing" 1183 "Zipwake" 1186 "Sailmon BV" 1192 "Airmoniq Pro Kft" 1194 "Sierra Marine" 1200 "Xinuo Information Technology (Xiamen)" 1218 "Septentrio" 1233 "NKE Marine Elecronics" 1238 "SuperTrack Aps" 1239 "Honda Electronics Co., LTD" 1245 "Raritan Engineering Company, Inc" 1249 "Integrated Power Solutions AG" 1260 "Interactive Technologies, Inc." 1283 "LTG-Tech" 1299 "Energy Solutions (UK) LTD." 1300 "WATT Fuel Cell Corp" 1302 "Pro Mainer" 1305 "Dragonfly Energy" 1306 "Koden Electronics Co., Ltd" 1311 "Humphree AB" 1316 "Hinkley Yachts" 1317 "Global Marine Management GmbH (GMM)" 1320 "Triskel Marine Ltd" 1330 "Warwick Control Technologies" 1331 "Dolphin Charger" 1337 "Barnacle Systems Inc" 1348 "Radian IoT, Inc." 1353 "Ocean LED Marine Ltd" 1359 "BluNav" 1361 "OVA (Nantong Saiyang Electronics Co., Ltd)" 1368 "RAD Propulsion" 1369 "Electric Yacht" 1372 "Elco Motor Yachts" 1384 "Tecnoseal Foundry S.r.l" 1385 "Pro Charging Systems, LLC" 1389 "EVEX Co., LTD" 1398 "Gobius Sensor Technology AB" 1403 "Arco Marine" 1408 "Lenco Marine Inc." 1413 "Naocontrol S.L." 1417 "Revatek" 1438 "Aeolionics" 1439 "PredictWind Ltd" 1440 "Egis Mobile Electric" 1445 "Starboard Yacht Group" 1446 "Roswell Marine" 1451 "ePropulsion (Guangdong ePropulsion Technology Ltd.)" 1452 "Micro-Air LLC" 1453 "Vital Battery" 1458 "Ride Controller LLC" 1460 "Tocaro Blue" 1461 "Vanquish Yachts" 1471 "FT Technologies" 1478 "Alps Alpine Co., Ltd." 1481 "E-Force Marine" 1482 "CMC Marine" 1483 "Nanjing Sandemarine Information Technology Co., Ltd." 1850 "Teleflex Marine (SeaStar Solutions)" 1851 "Raymarine" 1852 "Navionics" 1853 "Japan Radio Co" 1854 "Northstar Technologies" 1855 "Furuno" 1856 "Trimble" 1857 "Simrad" 1858 "Litton" 1859 "Kvasar AB" 1860 "MMP" 1861 "Vector Cantech" 1862 "Yamaha Marine" 1863 "Faria Instruments" ;
VAL_ 2566872830 industryCode 0 "Global" 1 "Highway" 2 "Agriculture" 3 "Construction" 4 "Marine Industry" 5 "Industrial" ;
VAL_ 2566872830 manufacturerCode 69 "ARKS Enterprises, Inc." 78 "FW Murphy/Enovation Controls" 80 "Twin Disc" 85 "Kohler Power Systems" 88 "Hemisphere GPS Inc" 116 "BEP Marine" 135 "Airmar" 137 "Maretron" 140 "Lowrance" 144 "Mercury Marine" 147 "Nautibus Electronic GmbH" 148 "Blue Water Data" 154 "Westerbeke" 157 "ISSPRO Inc" 161 "Offshore Systems (UK) Ltd." 163 "Evinrude/BRP" 165 "CPAC Systems AB" 168 "Xantrex Technology Inc." 169 "Marlin Technologies, Inc." 172 "Yanmar Marine" 174 "Volvo Penta" 175 "Honda Marine" 176 "Carling Technologies Inc. (Moritz Aerospace)" 185 "Beede Instruments" 192 "Floscan Instrument Co. Inc." 193 "Nobletec" 198 "Mystic Valley Communications" 199 "Actia" 200 "Honda Marine 2" 201 "Disenos Y Technologia" 211 "Digital Switching Systems" 215 "Xintex/Atena" 224 "EMMI NETWORK S.L." 225 "Honda Marine 3" 228 "ZF" 229 "Garmin" 233 "Yacht Monitoring Solutions" 235 "Sailormade Marine Telemetry/Tetra Technology LTD" 243 "Eride" 250 "Honda Marine 4" 257 "Honda Motor Company LTD" 272 "Groco" 273 "Actisense" 274 "Amphenol LTW Technology" 275 "Navico" 283 "Hamilton Jet" 285 "Sea Recovery" 286 "Coelmo SRL Italy" 295 "BEP Marine 2" 304 "Empir Bus" 305 "NovAtel" 306 "Sleipner Motor AS" 307 "MBW Technologies" 311 "Fischer Panda" 315 "ICOM" 328 "Qwerty" 329 "Dief" 341 "Boening Automationstechnologie GmbH & Co. KG" 345 "Korean Maritime University" 351 "Thrane and Thrane" 355 "Mastervolt" 356 "Fischer Panda Generators" 358 "Victron Energy" 370 "Rolls Royce Marine" 373 "Electronic Design" 374 "Northern Lights" 378 "Glendinning" 381 "B & G" 384 "Rose Point Navigation Systems" 385 "Johnson Outdoors Marine Electronics Inc Geonav" 394 "Capi 2" 396 "Beyond Measure" 400 "Livorsi Marine" 404 "ComNav" 409 "Chetco" 419 "Fusion Electronics" 421 "Standard Horizon" 422 "True Heading AB" 426 "Egersund Marine Electronics AS" 427 "em-trak Marine Electronics" 431 "Tohatsu Co, JP" 437 "Digital Yacht" 438 "Comar Systems Limited" 440 "Cummins" 443 "VDO (aka Continental-Corporation)" 451 "Parker Hannifin aka Village Marine Tech" 459 "Alltek Marine Electronics Corp" 460 "SAN GIORGIO S.E.I.N" 466 "Veethree Electronics & Marine" 467 "Humminbird Marine Electronics" 470 "SI-TEX Marine Electronics" 471 "Sea Cross Marine AB" 475 "GME aka Standard Communications Pty LTD" 476 "Humminbird Marine Electronics 2" 478 "Ocean Sat BV" 481 "Chetco Digitial Instruments" 493 "Watcheye" 499 "Lcj Capteurs" 502 "Attwood Marine" 503 "Naviop S.R.L." 504 "Vesper Marine Ltd" 510 "Marinesoft Co. LTD" 513 "Simarine" 517 "NoLand Engineering" 518 "Transas USA" 529 "National Instruments Korea" 530 "National Marine Electronics Association" 532 "Onwa Marine" 540 "Webasto" 571 "Marinecraft (South Korea)" 573 "McMurdo Group aka Orolia LTD" 578 "Advansea" 579 "KVH" 580 "San Jose Technology" 583 "Yacht Control" 586 "Suzuki Motor Corporation" 591 "US Coast Guard" 595 "Ship Module aka Customware" 600 "Aquatic AV" 605 "Aventics GmbH" 606 "Intellian" 612 "SamwonIT" 614 "Arlt Tecnologies" 637 "Bavaria Yacts" 641 "Diverse Yacht Services" 644 "Wema U.S.A dba KUS" 645 "Garmin 2" 658 "Shenzhen Jiuzhou Himunication" 688 "Rockford Corp" 699 "Harman International" 704 "JL Audio" 708 "Lars Thrane" 715 "Autonnic" 717 "Yacht Devices" 734 "REAP Systems" 735 "Au Electronics Group" 739 "LxNav" 741 "Littelfuse, Inc (formerly Carling Technologies)" 743 "DaeMyung" 744 "Woosung" 748 "ISOTTA IFRA srl" 772 "Blink Marine" 773 "Clarion US" 776 "HMI Systems" 777 "Ocean Signal" 778 "Seekeeper" 781 "Poly Planar" 785 "Fischer Panda DE" 795 "Broyda Industries" 796 "Canadian Automotive" 797 "Tides Marine" 798 "Lumishore" 799 "Still Water Designs and Audio" 802 "BJ Technologies (Beneteau)" 803 "Gill Sensors" 811 "Blue Water Desalination" 815 "FLIR" 824 "Undheim Systems" 826 "Lewmar Inc" 838 "TeamSurv" 844 "Fell Marine" 847 "Oceanvolt" 862 "Prospec" 868 "Data Panel Corp" 890 "L3 Technologies" 894 "Rhodan Marine Systems" 896 "Nexfour Solutions" 905 "ASA Electronics" 909 "Marines Co (South Korea)" 911 "Nautic-on" 917 "Sentinel" 929 "JL Marine ystems" 930 "Ecotronix" 944 "Zontisa Marine" 951 "EXOR International" 962 "Timbolier Industries" 963 "TJC Micro" 968 "Cox Powertrain" 969 "Blue Seas" 981 "Kobelt Manufacturing Co. Ltd" 992 "Blue Ocean IOT" 997 "Xenta Systems" 999 "Signal K" 1004 "Ultraflex SpA" 1008 "Lintest SmartBoat" 1011 "Soundmax" 1020 "Team Italia Marine (Onyx Marine Automation s.r.l)" 1021 "Entratech" 1022 "ITC Inc." 1029 "The Marine Guardian LLC" 1047 "Sonic Corporation" 1051 "ProNav" 1053 "Vetus Maxwell INC." 1056 "Lithium Pros" 1059 "Boatrax" 1062 "Marol Co ltd" 1065 "CALYPSO Instruments" 1066 "Spot Zero Water" 1069 "Lithionics Battery LLC" 1070 "Quick-teck Electronics Ltd" 1075 "Uniden America" 1083 "Nauticoncept" 1084 "Shadow-Caster LED lighting LLC" 1085 "Wet Sounds, LLC" 1088 "E-T-A Circuit Breakers" 1092 "Scheiber" 1100 "Smart Yachts International Limited" 1109 "Dockmate" 1114 "Bobs Machine" 1118 "L3Harris ASV" 1119 "Balmar LLC" 1120 "Elettromedia spa" 1127 "Electromaax" 1140 "Across Oceans Systems Ltd." 1145 "Kiwi Yachting" 1150 "BSB Artificial Intelligence GmbH" 1151 "Orca Technologoes AS" 1154 "TBS Electronics BV" 1158 "Technoton Electroics" 1160 "MG Energy Systems B.V." 1169 "Sea Macine Robotics Inc." 1171 "Vista Manufacturing" 1183 "Zipwake" 1186 "Sailmon BV" 1192 "Airmoniq Pro Kft" 1194 "Sierra Marine" 1200 "Xinuo Information Technology (Xiamen)" 1218 "Septentrio" 1233 "NKE Marine Elecronics" 1238 "SuperTrack Aps" 1239 "Honda Electronics Co., LTD" 1245 "Raritan Engineering Company, Inc" 1249 "Integrated Power Solutions AG" 1260 "Interactive Technologies, Inc." 1283 "LTG-Tech" 1299 "Energy Solutions (UK) LTD." 1300 "WATT Fuel Cell Corp" 1302 "Pro Mainer" 1305 "Dragonfly Energy" 1306 "Koden Electronics Co., Ltd" 1311 "Humphree AB" 1316 "Hinkley Yachts" 1317 "Global Marine Management GmbH (GMM)" 1320 "Triskel Marine Ltd" 1330 "Warwick Control Technologies" 1331 "Dolphin Charger" 1337 "Barnacle Systems Inc" 1348 "Radian IoT, Inc." 1353 "Ocean LED Marine Ltd" 1359 "BluNav" 1361 "OVA (Nantong Saiyang Electronics Co., Ltd)" 1368 "RAD Propulsion" 1369 "Electric Yacht" 1372 "Elco Motor Yachts" 1384 "Tecnoseal Foundry S.r.l" 1385 "Pro Charging Systems, LLC" 1389 "EVEX Co., LTD" 1398 "Gobius Sensor Technology AB" 1403 "Arco Marine" 1408 "Lenco Marine Inc." 1413 "Naocontrol S.L." 1417 "Revatek" 1438 "Aeolionics" 1439 "PredictWind Ltd" 1440 "Egis Mobile Electric" 1445 "Starboard Yacht Group" 1446 "Roswell Marine" 1451 "ePropulsion (Guangdong ePropulsion Technology Ltd.)" 1452 "Micro-Air LLC" 1453 "Vital Battery" 1458 "Ride Controller LLC" 1460 "Tocaro Blue" 1461 "Vanquish Yachts" 1471 "FT Technologies" 1478 "Alps Alpine Co., Ltd." 1481 "E-Force Marine" 1482 "CMC Marine" 1483 "Nanjing Sandemarine Information Technology Co., Ltd." 1850 "Teleflex Marine (SeaStar Solutions)" 1851 "Raymarine" 1852 "Navionics" 1853 "Japan Radio Co" 1854 "Northstar Technologies" 1855 "Furuno" 1856 "Trimble" 1857 "Simrad" 1858 "Litton" 1859 "Kvasar AB" 1860 "MMP" 1861 "Vector Cantech" 1862 "Yamaha Marine" 1863 "Faria Instruments" ;
VAL_ 2566874110 pilotMode 0 "Standby" 64 "Auto, compass commanded" 256 "Vane, Wind Mode" 384 "Track Mode" 385 "No Drift, COG referenced (In track, course changes)" ;
VAL_ 2566874110 industryCode 0 "Global" 1 "Highway" 2 "Agriculture" 3 "Construction" 4 "Marine Industry" 5 "Industrial" ;
VAL_ 2566874110 manufacturerCode 69 "ARKS Enterprises, Inc." 78 "FW Murphy/Enovation Controls" 80 "Twin Disc" 85 "Kohler Power Systems" 88 "Hemisphere GPS Inc" 116 "BEP Marine" 135 "Airmar" 137 "Maretron" 140 "Lowrance" 144 "Mercury Marine" 147 "Nautibus Electronic GmbH" 148 "Blue Water Data" 154 "Westerbeke" 157 "ISSPRO Inc" 161 "Offshore Systems (UK) Ltd." 163 "Evinrude/BRP" 165 "CPAC Systems AB" 168 "Xantrex Technology Inc." 169 "Marlin Technologies, Inc." 172 "Yanmar Marine" 174 "Volvo Penta" 175 "Honda Marine" 176 "Carling Technologies Inc. (Moritz Aerospace)" 185 "Beede Instruments" 192 "Floscan Instrument Co. Inc." 193 "Nobletec" 198 "Mystic Valley Communications" 199 "Actia" 200 "Honda Marine 2" 201 "Disenos Y Technologia" 211 "Digital Switching Systems" 215 "Xintex/Atena" 224 "EMMI NETWORK S.L." 225 "Honda Marine 3" 228 "ZF" 229 "Garmin" 233 "Yacht Monitoring Solutions" 235 "Sailormade Marine Telemetry/Tetra Technology LTD" 243 "Eride" 250 "Honda Marine 4" 257 "Honda Motor Company LTD" 272 "Groco" 273 "Actisense" 274 "Amphenol LTW Technology" 275 "Navico" 283 "Hamilton Jet" 285 "Sea Recovery" 286 "Coelmo SRL Italy" 295 "BEP Marine 2" 304 "Empir Bus" 305 "NovAtel" 306 "Sleipner Motor AS" 307 "MBW Technologies" 311 "Fischer Panda" 315 "ICOM" 328 "Qwerty" 329 "Dief" 341 "Boening Automationstechnologie GmbH & Co. KG" 345 "Korean Maritime University" 351 "Thrane and Thrane" 355 "Mastervolt" 356 "Fischer Panda Generators" 358 "Victron Energy" 370 "Rolls Royce Marine" 373 "Electronic Design" 374 "Northern Lights" 378 "Glendinning" 381 "B & G" 384 "Rose Point Navigation Systems" 385 "Johnson Outdoors Marine Electronics Inc Geonav" 394 "Capi 2" 396 "Beyond Measure" 400 "Livorsi Marine" 404 "ComNav" 409 "Chetco" 419 "Fusion Electronics" 421 "Standard Horizon" 422 "True Heading AB" 426 "Egersund Marine Electronics AS" 427 "em-trak Marine Electronics" 431 "Tohatsu Co, JP" 437 "Digital Yacht" 438 "Comar Systems Limited" 440 "Cummins" 443 "VDO (aka Continental-Corporation)" 451 "Parker Hannifin aka Village Marine Tech" 459 "Alltek Marine Electronics Corp" 460 "SAN GIORGIO S.E.I.N" 466 "Veethree Electronics & Marine" 467 "Humminbird Marine Electronics" 470 "SI-TEX Marine Electronics" 471 "Sea Cross Marine AB" 475 "GME aka Standard Communications Pty LTD" 476 "Humminbird Marine Electronics 2" 478 "Ocean Sat BV" 481 "Chetco Digitial Instruments" 493 "Watcheye" 499 "Lcj Capteurs" 502 "Attwood Marine" 503 "Naviop S.R.L." 504 "Vesper Marine Ltd" 510 "Marinesoft Co. LTD" 513 "Simarine" 517 "NoLand Engineering" 518 "Transas USA" 529 "National Instruments Korea" 530 "National Marine Electronics Association" 532 "Onwa Marine" 540 "Webasto" 571 "Marinecraft (South Korea)" 573 "McMurdo Group aka Orolia LTD" 578 "Advansea" 579 "KVH" 580 "San Jose Technology" 583 "Yacht Control" 586 "Suzuki Motor Corporation" 591 "US Coast Guard" 595 "Ship Module aka Customware" 600 "Aquatic AV" 605 "Aventics GmbH" 606 "Intellian" 612 "SamwonIT" 614 "Arlt Tecnologies" 637 "Bavaria Yacts" 641 "Diverse Yacht Services" 644 "Wema U.S.A dba KUS" 645 "Garmin 2" 658 "Shenzhen Jiuzhou Himunication" 688 "Rockford Corp" 699 "Harman International" 704 "JL Audio" 708 "Lars Thrane" 715 "Autonnic" 717 "Yacht Devices" 734 "REAP Systems" 735 "Au Electronics Group" 739 "LxNav" 741 "Littelfuse, Inc (formerly Carling Technologies)" 743 "DaeMyung" 744 "Woosung" 748 "ISOTTA IFRA srl" 772 "Blink Marine" 773 "Clarion US" 776 "HMI Systems" 777 "Ocean Signal" 778 "Seekeeper" 781 "Poly Planar" 785 "Fischer Panda DE" 795 "Broyda Industries" 796 "Canadian Automotive" 797 "Tides Marine" 798 "Lumishore" 799 "Still Water Designs and Audio" 802 "BJ Technologies (Beneteau)" 803 "Gill Sensors" 811 "Blue Water Desalination" 815 "FLIR" 824 "Undheim Systems" 826 "Lewmar Inc" 838 "TeamSurv" 844 "Fell Marine" 847 "Oceanvolt" 862 "Prospec" 868 "Data Panel Corp" 890 "L3 Technologies" 894 "Rhodan Marine Systems" 896 "Nexfour Solutions" 905 "ASA Electronics" 909 "Marines Co (South Korea)" 911 "Nautic-on" 917 "Sentinel" 929 "JL Marine ystems" 930 "Ecotronix" 944 "Zontisa Marine" 951 "EXOR International" 962 "Timbolier Industries" 963 "TJC Micro" 968 "Cox Powertrain" 969 "Blue Seas" 981 "Kobelt Manufacturing Co. Ltd" 992 "Blue Ocean IOT" 997 "Xenta Systems" 999 "Signal K" 1004 "Ultraflex SpA" 1008 "Lintest SmartBoat" 1011 "Soundmax" 1020 "Team Italia Marine (Onyx Marine Automation s.r.l)" 1021 "Entratech" 1022 "ITC Inc." 1029 "The Marine Guardian LLC" 1047 "Sonic Corporation" 1051 "ProNav" 1053 "Vetus Maxwell INC." 1056 "Lithium Pros" 1059 "Boatrax" 1062 "Marol Co ltd" 1065 "CALYPSO Instruments" 1066 "Spot Zero Water" 1069 "Lithionics Battery LLC" 1070 "Quick-teck Electronics Ltd" 1075 "Uniden America" 1083 "Nauticoncept" 1084 "Shadow-Caster LED lighting LLC" 1085 "Wet Sounds, LLC" 1088 "E-T-A Circuit Breakers" 1092 "Scheiber" 1100 "Smart Yachts International Limited" 1109 "Dockmate" 1114 "Bobs Machine" 1118 "L3Harris ASV" 1119 "Balmar LLC" 1120 "Elettromedia spa" 1127 "Electromaax" 1140 "Across Oceans Systems Ltd." 1145 "Kiwi Yachting" 1150 "BSB Artificial Intelligence GmbH" 1151 "Orca Technologoes AS" 1154 "TBS Electronics BV" 1158 "Technoton Electroics" 1160 "MG Energy Systems B.V." 1169 "Sea Macine Robotics Inc." 1171 "Vista Manufacturing" 1183 "Zipwake" 1186 "Sailmon BV" 1192 "Airmoniq Pro Kft" 1194 "Sierra Marine" 1200 "Xinuo Information Technology (Xiamen)" 1218 "Septentrio" 1233 "NKE Marine Elecronics" 1238 "SuperTrack Aps" 1239 "Honda Electronics Co., LTD" 1245 "Raritan Engineering Company, Inc" 1249 "Integrated Power Solutions AG" 1260 "Interactive Technologies, Inc." 1283 "LTG-Tech" 1299 "Energy Solutions (UK) LTD." 1300 "WATT Fuel Cell Corp" 1302 "Pro Mainer" 1305 "Dragonfly Energy" 1306 "Koden Electronics Co., Ltd" 1311 "Humphree AB" 1316 "Hinkley Yachts" 1317 "Global Marine Management GmbH (GMM)" 1320 "Triskel Marine Ltd" 1330 "Warwick Control Technologies" 1331 "Dolphin Charger" 1337 "Barnacle Systems Inc" 1348 "Radian IoT, Inc." 1353 "Ocean LED Marine Ltd" 1359 "BluNav" 1361 "OVA (Nantong Saiyang Electronics Co., Ltd)" 1368 "RAD Propulsion" 1369 "Electric Yacht" 1372 "Elco Motor Yachts" 1384 "Tecnoseal Foundry S.r.l" 1385 "Pro Charging Systems, LLC" 1389 "EVEX Co., LTD" 1398 "Gobius Sensor Technology AB" 1403 "Arco Marine" 1408 "Lenco Marine Inc." 1413 "Naocontrol S.L." 1417 "Revatek" 1438 "Aeolionics" 1439 "PredictWind Ltd" 1440 "Egis Mobile Electric" 1445 "Starboard Yacht Group" 1446 "Roswell Marine" 1451 "ePropulsion (Guangdong ePropulsion Technology Ltd.)" 1452 "Micro-Air LLC" 1453 "Vital Battery" 1458 "Ride Controller LLC" 1460 "Tocaro Blue" 1461 "Vanquish Yachts" 1471 "FT Technologies" 1478 "Alps Alpine Co., Ltd." 1481 "E-Force Marine" 1482 "CMC Marine" 1483 "Nanjing Sandemarine Information Technology Co., Ltd." 1850 "Teleflex Marine (SeaStar Solutions)" 1851 "Raymarine" 1852 "Navionics" 1853 "Japan Radio Co" 1854 "Northstar Technologies" 1855 "Furuno" 1856 "Trimble" 1857 "Simrad" 1858 "Litton" 1859 "Kvasar AB" 1860 "MMP" 1861 "Vector Cantech" 1862 "Yamaha Marine" 1863 "Faria Instruments" ;
SG_MUL_VAL_ 2566857470 m39207_data manufacturerIndustry 39207-39207;
SG_MUL_VAL_ 2566857470 m39110_reserved4 manufacturerIndustry 39110-39110;
SG_MUL_VAL_ 2566857470 m39110_reserved5 manufacturerIndustry 39110-39110;
SG_MUL_VAL_ 2566857470 m39110_neutral manufacturerIndustry 39110-39110;
SG_MUL_VAL_ 2566857470 m39110_reserved7 manufacturerIndustry 39110-39110;
SG_MUL_VAL_ 2566857470 m39110_reserved8 manufacturerIndustry 39110-39110;
